VERSION ""

NS_ :

BS_:

BU_: APIM_CISM APIM ESPM DSP FCIMB RACM_RCIM HUD_ADV WCM TRM_ITRM ACM GWM _delete IPC GENERIC TSTR

BO_ 413 LBS1_Indication_Signals: 8 APIM
 SG_ LBS1_ParentID : 31|16@0+ (1,0) [0|65535] "unitless"  RACM_RCIM,IPC
 SG_ LBS1_ListStatus : 57|2@0+ (1,0) [0|3] "SED"  RACM_RCIM,IPC
 SG_ LBS1_ListServer : 7|8@0+ (1,0) [0|255] "unitless"  RACM_RCIM,IPC
 SG_ LBS1_ListID : 15|16@0+ (1,0) [0|65535] "unitless"  RACM_RCIM,IPC
 SG_ LBS1_EntryIndex : 47|16@0+ (1,0) [0|65535] "unitless"  RACM_RCIM,IPC

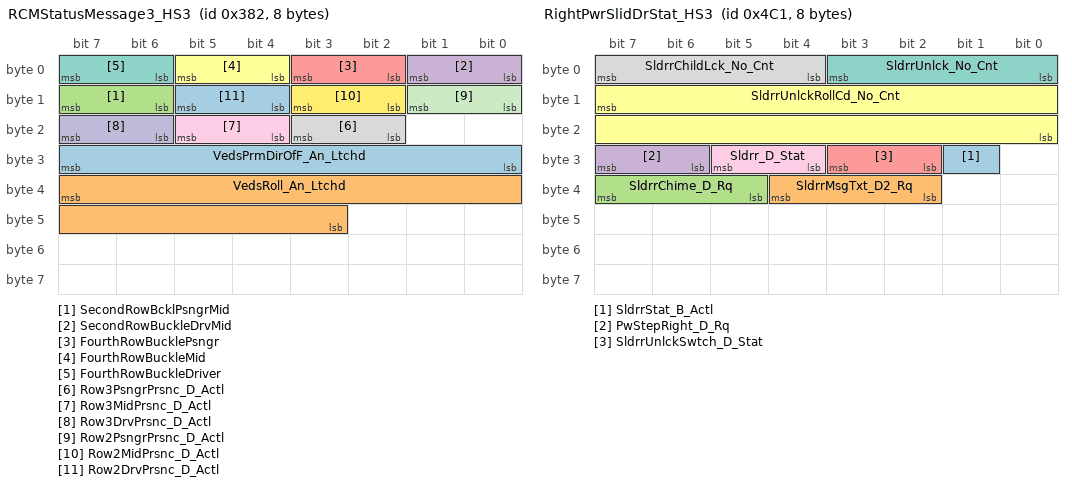
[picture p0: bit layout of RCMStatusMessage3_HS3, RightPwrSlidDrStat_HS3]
BO_ 898 RCMStatusMessage3_HS3: 8 GWM
 SG_ VedsPrmDirOfF_An_Ltchd : 31|8@0+ (2,-180) [-178|326] "degree"  APIM
 SG_ VedsRoll_An_Ltchd : 39|13@0+ (0.5,-2048) [-2047.5|2046.5] "degree"  APIM
 SG_ SecondRowBcklPsngrMid : 15|2@0+ (1,0) [0|3] "SED"  IPC
 SG_ SecondRowBuckleDrvMid : 1|2@0+ (1,0) [0|3] "SED"  IPC
 SG_ FourthRowBucklePsngr : 3|2@0+ (1,0) [0|3] "SED"  IPC
 SG_ FourthRowBuckleMid : 5|2@0+ (1,0) [0|3] "SED"  IPC
 SG_ FourthRowBuckleDriver : 7|2@0+ (1,0) [0|3] "SED"  IPC
 SG_ Row3PsngrPrsnc_D_Actl : 19|2@0+ (1,0) [0|3] "SED"  APIM,APIM_CISM,IPC
 SG_ Row3MidPrsnc_D_Actl : 21|2@0+ (1,0) [0|3] "SED"  APIM,APIM_CISM,IPC
 SG_ Row3DrvPrsnc_D_Actl : 23|2@0+ (1,0) [0|3] "SED"  APIM,APIM_CISM,IPC
 SG_ Row2PsngrPrsnc_D_Actl : 9|2@0+ (1,0) [0|3] "SED"  APIM,APIM_CISM,IPC
 SG_ Row2MidPrsnc_D_Actl : 11|2@0+ (1,0) [0|3] "SED"  APIM,APIM_CISM,IPC
 SG_ Row2DrvPrsnc_D_Actl : 13|2@0+ (1,0) [0|3] "SED"  APIM,APIM_CISM,IPC

BO_ 1020 Personality_APIM_Data4: 8 APIM
 SG_ CtrStkPersIndex2_D_Actl : 39|3@0+ (1,0) [0|7] "SED"  HUD_ADV,IPC
 SG_ CtrStkFeat2ConfigActl : 7|16@0+ (1,0) [0|65535] "Undefined"  HUD_ADV,IPC
 SG_ CtrStkFeat2NoActl : 23|16@0+ (1,0) [0|65535] "Undefined"  HUD_ADV,IPC
 SG_ CtrStkDsplyOp2_D_Rq : 36|3@0+ (1,0) [0|7] "SED"  HUD_ADV,IPC

BO_ 1007 Personality_IPC_Data_3: 8 IPC
 SG_ PersIndexIpc2_D_Actl : 39|3@0+ (1,0) [0|7] "SED"  APIM,APIM_CISM
 SG_ FeatNoIpc2Actl : 23|16@0+ (1,0) [0|65535] "Number"  APIM,APIM_CISM
 SG_ FeatConfigIpc2Actl : 7|16@0+ (1,0) [0|65535] "unitless"  APIM,APIM_CISM

BO_ 1217 RightPwrSlidDrStat_HS3: 8 GWM
 SG_ SldrrStat_B_Actl : 25|1@0+ (1,0) [0|1] "SED"  IPC
 SG_ SldrrMsgTxt_D2_Rq : 36|3@0+ (1,0) [0|7] "SED"  IPC
 SG_ SldrrChime_D_Rq : 39|3@0+ (1,0) [0|7] "SED"  IPC
 SG_ PwStepRight_D_Rq : 31|2@0+ (1,0) [0|3] "SED" Vector__XXX
 SG_ SldrrUnlckSwtch_D_Stat : 27|2@0+ (1,0) [0|3] "SED" Vector__XXX
 SG_ SldrrUnlckRollCd_No_Cnt : 15|16@0+ (1,0) [0|65535] "unitless" Vector__XXX
 SG_ SldrrUnlck_No_Cnt : 3|4@0+ (1,0) [0|15] "unitless" Vector__XXX
 SG_ SldrrChildLck_No_Cnt : 7|4@0+ (1,0) [0|15] "unitless" Vector__XXX
 SG_ Sldrr_D_Stat : 29|2@0+ (1,0) [0|3] "SED" Vector__XXX

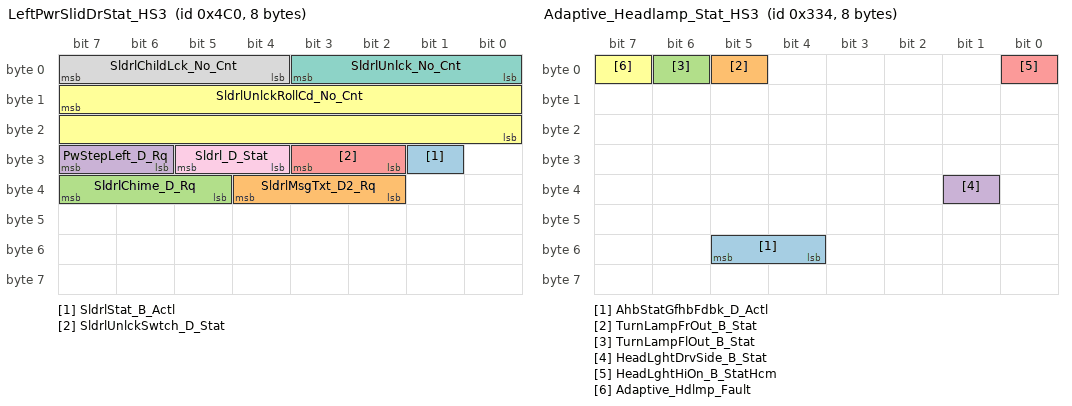
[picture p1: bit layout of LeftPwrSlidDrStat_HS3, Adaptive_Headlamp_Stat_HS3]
BO_ 1216 LeftPwrSlidDrStat_HS3: 8 GWM
 SG_ SldrlStat_B_Actl : 25|1@0+ (1,0) [0|1] "SED"  IPC
 SG_ SldrlMsgTxt_D2_Rq : 36|3@0+ (1,0) [0|7] "SED"  IPC
 SG_ SldrlChime_D_Rq : 39|3@0+ (1,0) [0|7] "SED"  IPC
 SG_ PwStepLeft_D_Rq : 31|2@0+ (1,0) [0|3] "SED" Vector__XXX
 SG_ SldrlUnlckSwtch_D_Stat : 27|2@0+ (1,0) [0|3] "SED" Vector__XXX
 SG_ SldrlUnlckRollCd_No_Cnt : 15|16@0+ (1,0) [0|65535] "unitless" Vector__XXX
 SG_ SldrlUnlck_No_Cnt : 3|4@0+ (1,0) [0|15] "unitless" Vector__XXX
 SG_ SldrlChildLck_No_Cnt : 7|4@0+ (1,0) [0|15] "unitless" Vector__XXX
 SG_ Sldrl_D_Stat : 29|2@0+ (1,0) [0|3] "SED" Vector__XXX

BO_ 820 Adaptive_Headlamp_Stat_HS3: 8 GWM
 SG_ AhbStatGfhbFdbk_D_Actl : 53|2@0+ (1,0) [0|3] "SED" Vector__XXX
 SG_ TurnLampFrOut_B_Stat : 5|1@0+ (1,0) [0|1] "SED" Vector__XXX
 SG_ TurnLampFlOut_B_Stat : 6|1@0+ (1,0) [0|1] "SED" Vector__XXX
 SG_ HeadLghtDrvSide_B_Stat : 33|1@0+ (1,0) [0|1] "SED" Vector__XXX
 SG_ HeadLghtHiOn_B_StatHcm : 0|1@0+ (1,0) [0|1] "SED"  IPC
 SG_ Adaptive_Hdlmp_Fault : 7|1@0+ (1,0) [0|1] "SED"  IPC

BO_ 1247 PowerDistData_4_HS3: 8 GWM
 SG_ TrlrBrkCtl3_B_Falt : 2|1@0+ (1,0) [0|1] "SED"  TRM_ITRM
 SG_ StopLampBRqTrlrAft_No_Cs : 15|8@0+ (1,0) [0|255] "Unitless" Vector__XXX
 SG_ StopLampBRqTrlrAft_No_Cnt : 6|4@0+ (1,0) [0|15] "Unitless" Vector__XXX
 SG_ StopLamp_B_RqTrlrAft : 7|1@0+ (1,0) [0|1] "SED"  TRM_ITRM

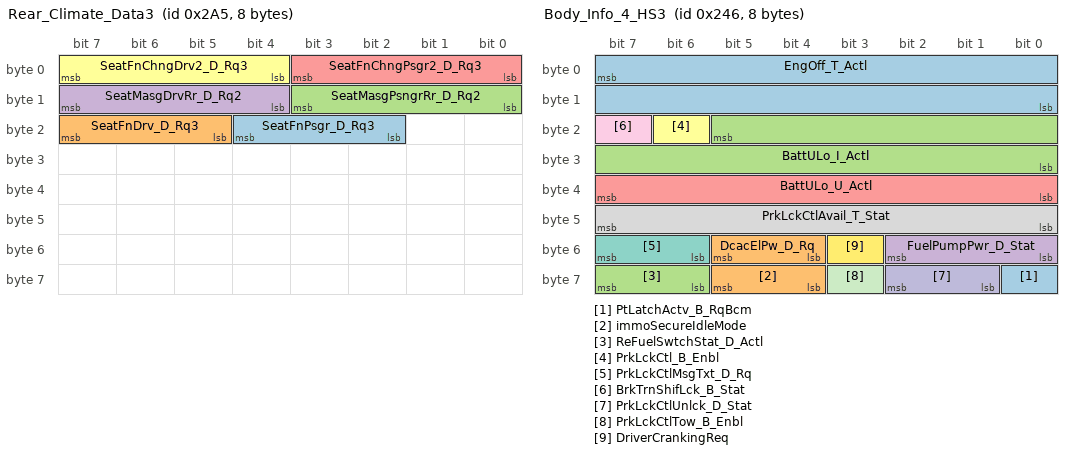
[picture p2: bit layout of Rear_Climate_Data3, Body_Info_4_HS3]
BO_ 677 Rear_Climate_Data3: 8 RACM_RCIM
 SG_ SeatFnPsgr_D_Rq3 : 20|3@0+ (1,0) [0|7] "SED"  GWM
 SG_ SeatFnDrv_D_Rq3 : 23|3@0+ (1,0) [0|7] "SED"  GWM
 SG_ SeatMasgPsngrRr_D_Rq2 : 11|4@0+ (1,0) [0|15] "SED"  GWM
 SG_ SeatMasgDrvRr_D_Rq2 : 15|4@0+ (1,0) [0|15] "SED"  GWM
 SG_ SeatFnChngPsgr2_D_Rq3 : 3|4@0+ (1,0) [0|15] "SED"  GWM
 SG_ SeatFnChngDrv2_D_Rq3 : 7|4@0+ (1,0) [0|15] "SED"  GWM

BO_ 582 Body_Info_4_HS3: 8 GWM
 SG_ PtLatchActv_B_RqBcm : 56|1@0+ (1,0) [0|1] "SED"  IPC
 SG_ immoSecureIdleMode : 61|2@0+ (1,0) [0|3] "SED"  APIM,APIM_CISM
 SG_ ReFuelSwtchStat_D_Actl : 63|2@0+ (1,0) [0|3] "SED" Vector__XXX
 SG_ FuelPumpPwr_D_Stat : 50|3@0+ (1,0) [0|7] "SED" Vector__XXX
 SG_ BattULo_U_Actl : 39|8@0+ (0.0625,0) [0|15.875] "volt" Vector__XXX
 SG_ PrkLckCtl_B_Enbl : 22|1@0+ (1,0) [0|1] "SED"  APIM,APIM_CISM,IPC
 SG_ PrkLckCtlMsgTxt_D_Rq : 55|2@0+ (1,0) [0|3] "SED"  IPC
 SG_ PrkLckCtlAvail_T_Stat : 47|8@0+ (1,0) [0|255] "second"  IPC
 SG_ BrkTrnShifLck_B_Stat : 23|1@0+ (1,0) [0|1] "SED" Vector__XXX
 SG_ PrkLckCtlUnlck_D_Stat : 58|2@0+ (1,0) [0|3] "SED"  IPC
 SG_ PrkLckCtlTow_B_Enbl : 59|1@0+ (1,0) [0|1] "SED"  IPC
 SG_ DriverCrankingReq : 51|1@0+ (1,0) [0|1] "SED" Vector__XXX
 SG_ EngOff_T_Actl : 7|16@0+ (1,0) [0|65534] "second^0.5"  IPC
 SG_ DcacElPw_D_Rq : 53|2@0+ (1,0) [0|3] "SED" Vector__XXX
 SG_ BattULo_I_Actl : 21|14@0+ (0.0625,-512) [-512|511.875] "ampere" Vector__XXX

BO_ 1036 PedestrianAlert_Data_HS3: 8 GWM
 SG_ PdstrnAlrt_B_Falt : 7|1@0+ (1,0) [0|1] "SED"  IPC

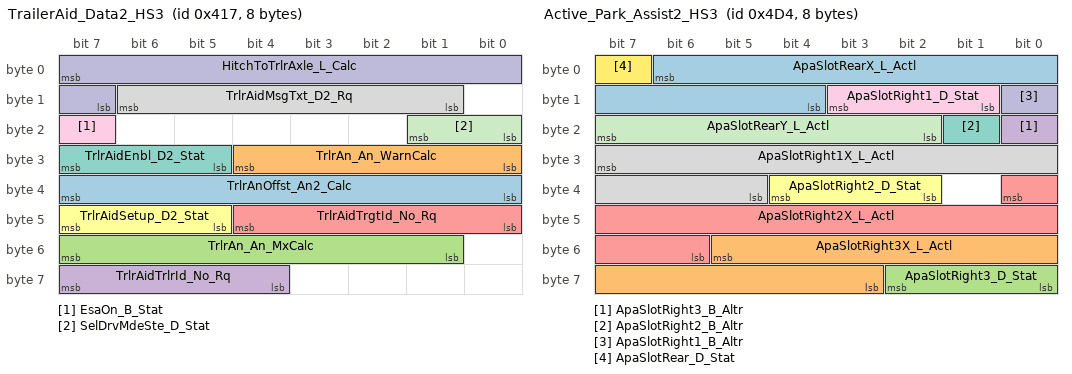
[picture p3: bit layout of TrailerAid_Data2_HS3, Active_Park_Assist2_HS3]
BO_ 1047 TrailerAid_Data2_HS3: 8 GWM
 SG_ TrlrAnOffst_An2_Calc : 39|8@0+ (0.5,-64) [-64|63.5] "degrees" Vector__XXX
 SG_ TrlrAn_An_WarnCalc : 28|5@0+ (1,0) [0|31] "degrees" Vector__XXX
 SG_ TrlrAn_An_MxCalc : 55|7@0+ (1,0) [0|127] "degrees" Vector__XXX
 SG_ TrlrAidTrlrId_No_Rq : 63|4@0+ (1,0) [0|15] "unitless"  APIM,APIM_CISM,IPC
 SG_ TrlrAidTrgtId_No_Rq : 44|5@0+ (1,0) [0|31] "unitless" Vector__XXX
 SG_ TrlrAidSetup_D2_Stat : 47|3@0+ (1,0) [0|7] "SED" Vector__XXX
 SG_ TrlrAidEnbl_D2_Stat : 31|3@0+ (1,0) [0|7] "SED"  APIM,APIM_CISM,TRM_ITRM,IPC
 SG_ TrlrAidMsgTxt_D2_Rq : 14|6@0+ (1,0) [0|63] "SED"  APIM,APIM_CISM,IPC,TRM_ITRM
 SG_ EsaOn_B_Stat : 23|1@0+ (1,0) [0|1] "SED"  IPC
 SG_ HitchToTrlrAxle_L_Calc : 7|9@0+ (0.0254,0) [0|12.9794] "meter" Vector__XXX
 SG_ SelDrvMdeSte_D_Stat : 17|2@0+ (1,0) [0|3] "SED" Vector__XXX

BO_ 688 APIM_TCUB_Word_Rx_HS3: 8 GWM
 SG_ APIM_TCUB_Word_Rx : 7|64@0+ (1,0) [0|1.84467440737096E+019] "unitless"  APIM,APIM_CISM

BO_ 696 APIM_TCUB_Word_Tx: 8 APIM
 SG_ APIM_TCUB_Word_Tx : 7|64@0+ (1,0) [0|1.84467440737096E+019] "unitless"  GWM

BO_ 1236 Active_Park_Assist2_HS3: 8 GWM
 SG_ ApaSlotRearX_L_Actl : 6|11@0+ (0.02,-20.96) [-20.96|19.98] "meter"  APIM,APIM_CISM
 SG_ ApaSlotRight3X_L_Actl : 53|11@0+ (0.02,-20.96) [-20.96|19.98] "meter"  APIM,APIM_CISM
 SG_ ApaSlotRight3_D_Stat : 58|3@0+ (1,0) [0|7] "SED"  APIM,APIM_CISM
 SG_ ApaSlotRight3_B_Altr : 16|1@0+ (1,0) [0|1] "SED"  APIM,APIM_CISM
 SG_ ApaSlotRight2X_L_Actl : 32|11@0+ (0.02,-20.96) [-20.96|19.98] "meter"  APIM,APIM_CISM
 SG_ ApaSlotRight2_D_Stat : 36|3@0+ (1,0) [0|7] "SED"  APIM,APIM_CISM
 SG_ ApaSlotRight2_B_Altr : 17|1@0+ (1,0) [0|1] "SED"  APIM,APIM_CISM
 SG_ ApaSlotRight1X_L_Actl : 31|11@0+ (0.02,-20.96) [-20.96|19.98] "meter"  APIM,APIM_CISM
 SG_ ApaSlotRight1_D_Stat : 11|3@0+ (1,0) [0|7] "SED"  APIM,APIM_CISM
 SG_ ApaSlotRight1_B_Altr : 8|1@0+ (1,0) [0|1] "SED"  APIM,APIM_CISM
 SG_ ApaSlotRearY_L_Actl : 23|6@0+ (0.2,-6.4) [-6.4|6.2] "meter"  APIM,APIM_CISM
 SG_ ApaSlotRear_D_Stat : 7|1@0+ (1,0) [0|1] "SED"  APIM,APIM_CISM

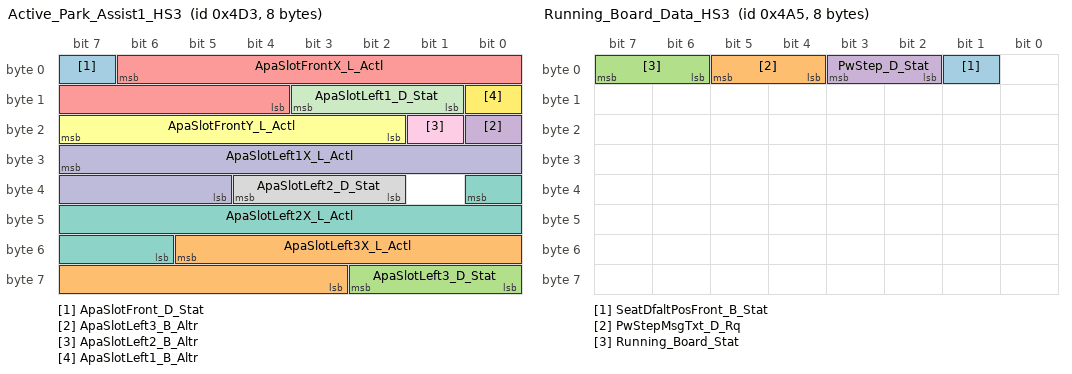
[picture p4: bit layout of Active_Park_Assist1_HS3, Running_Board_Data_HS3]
BO_ 1235 Active_Park_Assist1_HS3: 8 GWM
 SG_ ApaSlotFront_D_Stat : 7|1@0+ (1,0) [0|1] "SED"  APIM,APIM_CISM
 SG_ ApaSlotLeft3X_L_Actl : 53|11@0+ (0.02,-20.96) [-20.96|19.98] "meter"  APIM,APIM_CISM
 SG_ ApaSlotLeft3_D_Stat : 58|3@0+ (1,0) [0|7] "SED"  APIM,APIM_CISM
 SG_ ApaSlotLeft3_B_Altr : 16|1@0+ (1,0) [0|1] "SED"  APIM,APIM_CISM
 SG_ ApaSlotFrontX_L_Actl : 6|11@0+ (0.02,-20.96) [-20.96|19.98] "meter"  APIM,APIM_CISM
 SG_ ApaSlotFrontY_L_Actl : 23|6@0+ (0.2,-6.4) [-6.4|6.2] "meter"  APIM,APIM_CISM
 SG_ ApaSlotLeft2X_L_Actl : 32|11@0+ (0.02,-20.96) [-20.96|19.98] "meter"  APIM,APIM_CISM
 SG_ ApaSlotLeft2_D_Stat : 36|3@0+ (1,0) [0|7] "SED"  APIM,APIM_CISM
 SG_ ApaSlotLeft2_B_Altr : 17|1@0+ (1,0) [0|1] "SED"  APIM,APIM_CISM
 SG_ ApaSlotLeft1X_L_Actl : 31|11@0+ (0.02,-20.96) [-20.96|19.98] "meter"  APIM,APIM_CISM
 SG_ ApaSlotLeft1_D_Stat : 11|3@0+ (1,0) [0|7] "SED"  APIM,APIM_CISM
 SG_ ApaSlotLeft1_B_Altr : 8|1@0+ (1,0) [0|1] "SED"  APIM,APIM_CISM

BO_ 841 FuelOpHeater_Stat2_HS3: 8 GWM
 SG_ FohStrtDateDay_No_Stat : 7|16@0+ (1,0) [0|65535] "julian day"  IPC
 SG_ FohStrtDateYr_No_Stat : 23|8@0+ (1,2000) [2000|2255] "year"  IPC
 SG_ FohAddHeater_D_Stat : 31|2@0+ (1,0) [0|3] "SED" Vector__XXX

BO_ 1189 Running_Board_Data_HS3: 8 GWM
 SG_ SeatDfaltPosFront_B_Stat : 1|1@0+ (1,0) [0|1] "SED" Vector__XXX
 SG_ PwStepMsgTxt_D_Rq : 5|2@0+ (1,0) [0|3] "SED"  IPC
 SG_ Running_Board_Stat : 7|2@0+ (1,0) [0|3] "SED"  APIM,APIM_CISM,IPC
 SG_ PwStep_D_Stat : 3|2@0+ (1,0) [0|3] "SED" Vector__XXX

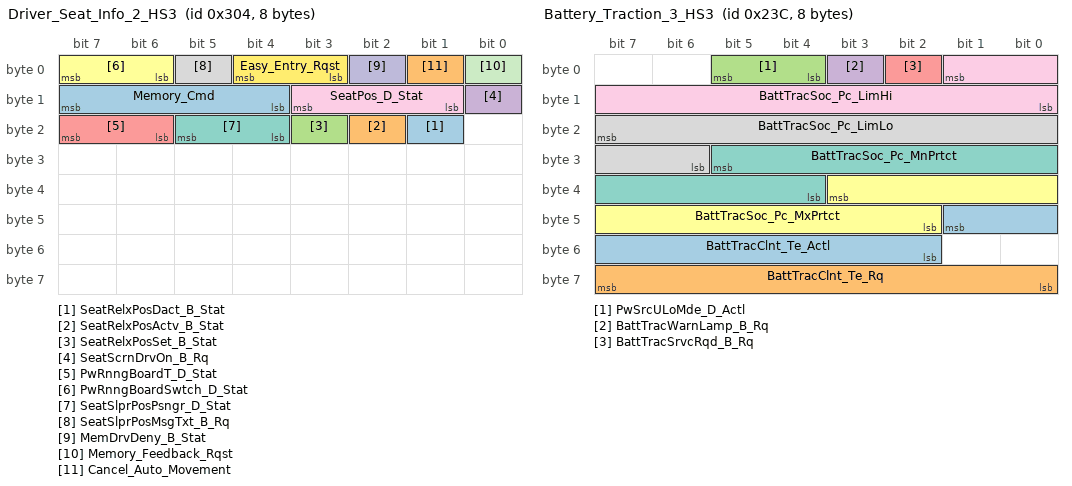
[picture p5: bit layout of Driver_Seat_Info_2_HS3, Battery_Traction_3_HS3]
BO_ 772 Driver_Seat_Info_2_HS3: 8 GWM
 SG_ SeatRelxPosDact_B_Stat : 17|1@0+ (1,0) [0|1] "SED"  APIM,APIM_CISM
 SG_ SeatRelxPosActv_B_Stat : 18|1@0+ (1,0) [0|1] "SED"  APIM,APIM_CISM
 SG_ SeatRelxPosSet_B_Stat : 19|1@0+ (1,0) [0|1] "SED"  APIM,APIM_CISM
 SG_ SeatScrnDrvOn_B_Rq : 8|1@0+ (1,0) [0|1] "SED"  APIM,APIM_CISM
 SG_ PwRnngBoardT_D_Stat : 23|2@0+ (1,0) [0|3] "SED"  APIM,APIM_CISM,IPC
 SG_ PwRnngBoardSwtch_D_Stat : 7|2@0+ (1,0) [0|3] "SED"  APIM,APIM_CISM,IPC
 SG_ SeatSlprPosPsngr_D_Stat : 21|2@0+ (1,0) [0|3] "SED" Vector__XXX
 SG_ SeatSlprPosMsgTxt_B_Rq : 5|1@0+ (1,0) [0|1] "SED"  IPC
 SG_ SeatPos_D_Stat : 11|3@0+ (1,0) [0|7] "SED" Vector__XXX
 SG_ MemDrvDeny_B_Stat : 2|1@0+ (1,0) [0|1] "SED"  IPC
 SG_ Memory_Feedback_Rqst : 0|1@0+ (1,0) [0|1] "SED"  IPC
 SG_ Easy_Entry_Rqst : 4|2@0+ (1,0) [0|3] "SED" Vector__XXX
 SG_ Memory_Cmd : 15|4@0+ (1,0) [0|15] "SED"  IPC
 SG_ Cancel_Auto_Movement : 1|1@0+ (1,0) [0|1] "SED"  APIM_CISM

BO_ 1054 BrakeSysFeatures_3_HS3: 8 GWM
 SG_ SelDrvMdeChassis3_D_Rq : 61|5@0+ (1,0) [0|31] "SED" Vector__XXX
 SG_ RbaBrk_D_Stat : 63|2@0+ (1,0) [0|3] "SED" Vector__XXX
 SG_ SelDrvMdeChassis2_D_Rq : 45|5@0+ (1,0) [0|31] "SED" Vector__XXX
 SG_ BrkBstrLoLampOn_B_Rq : 24|1@0+ (1,0) [0|1] "SED" Vector__XXX
 SG_ TrailCtl_D_Stat : 55|3@0+ (1,0) [0|7] "SED"  APIM,APIM_CISM,IPC
 SG_ TrailCtlMsgTxt_D_Rq : 52|4@0+ (1,0) [0|15] "SED"  APIM_CISM,IPC
 SG_ BrkPadMsgTxt_D_Rq : 31|2@0+ (1,0) [0|3] "SED"  IPC
 SG_ BrkBstrVac_D_Stat : 18|2@0+ (1,0) [0|3] "SED" Vector__XXX
 SG_ DrvSlipCtlOffLamp_D_Rq : 23|2@0+ (1,0) [0|3] "SED"  APIM,APIM_CISM,IPC
 SG_ DrvSlipCtlMdeMsg_D_Rq : 13|5@0+ (1,0) [0|31] "SED"  APIM,APIM_CISM,IPC
 SG_ HdcOn_B_Ind : 16|1@0+ (1,0) [0|1] "SED"  APIM,APIM_CISM,IPC
 SG_ AutoHoldMsgTxt_D_Rq : 4|4@0+ (1,0) [0|15] "SED"  IPC
 SG_ CtaBrk_D_Stat : 47|2@0+ (1,0) [0|3] "SED" Vector__XXX
 SG_ SelDrvMdeAwd_D_Rq : 29|5@0+ (1,0) [0|31] "SED" Vector__XXX
 SG_ AutoHoldSwMde_B_Ind : 0|1@0+ (1,0) [0|1] "SED"  APIM,APIM_CISM
 SG_ AutoHoldMde_D_Ind : 15|2@0+ (1,0) [0|3] "SED"  IPC,HUD_ADV
 SG_ BrkMdeInhbt_B_RqDsply : 8|1@0+ (1,0) [0|1] "SED"  IPC
 SG_ BrkLineLck_D_Stat : 21|3@0+ (1,0) [0|7] "SED"  IPC
 SG_ SelDrvMdeChassis_D_Rq : 39|5@0+ (1,0) [0|31] "SED" Vector__XXX
 SG_ ApaBrk_D_Stat : 34|2@0+ (1,0) [0|3] "SED" Vector__XXX
 SG_ FrontDiffElckrOpen_B_Rq : 48|1@0+ (1,0) [0|1] "SED" Vector__XXX
 SG_ OnePdlDrvDeny_B_Stat : 40|1@0+ (1,0) [0|1] "SED" Vector__XXX
 SG_ BrkDrvMde_D_Stat : 7|3@0+ (1,0) [0|7] "SED"  ACM,IPC
 SG_ TrailOnePdlTqLm_B_Actl : 56|1@0+ (1,0) [0|1] "SED" Vector__XXX

BO_ 572 Battery_Traction_3_HS3: 8 GWM
 SG_ BattTracClnt_Te_Actl : 41|8@0+ (0.5,-60) [-60|66.5] "degC" Vector__XXX
 SG_ BattTracClnt_Te_Rq : 63|8@0+ (0.5,-60) [-60|67.5] "degC" Vector__XXX
 SG_ PwSrcULoMde_D_Actl : 5|2@0+ (1,0) [0|3] "SED" Vector__XXX
 SG_ BattTracWarnLamp_B_Rq : 3|1@0+ (1,0) [0|1] "SED"  IPC
 SG_ BattTracSrvcRqd_B_Rq : 2|1@0+ (1,0) [0|1] "SED"  IPC
 SG_ BattTracSoc_Pc_MxPrtct : 35|10@0+ (0.1,0) [0|100] "%" Vector__XXX
 SG_ BattTracSoc_Pc_MnPrtct : 29|10@0+ (0.1,0) [0|100] "%" Vector__XXX
 SG_ BattTracSoc_Pc_LimLo : 23|10@0+ (0.1,0) [0|100] "%" Vector__XXX
 SG_ BattTracSoc_Pc_LimHi : 1|10@0+ (0.1,0) [0|100] "%" Vector__XXX

BO_ 561 TransGearData_2_HS3: 8 GWM
 SG_ TrnMsgTxt2_D_Rq : 39|3@0+ (1,0) [0|7] "SED"  APIM_CISM,IPC
 SG_ TrnMsgTxt_D_Rq : 23|4@0+ (1,0) [0|15] "SED"  IPC

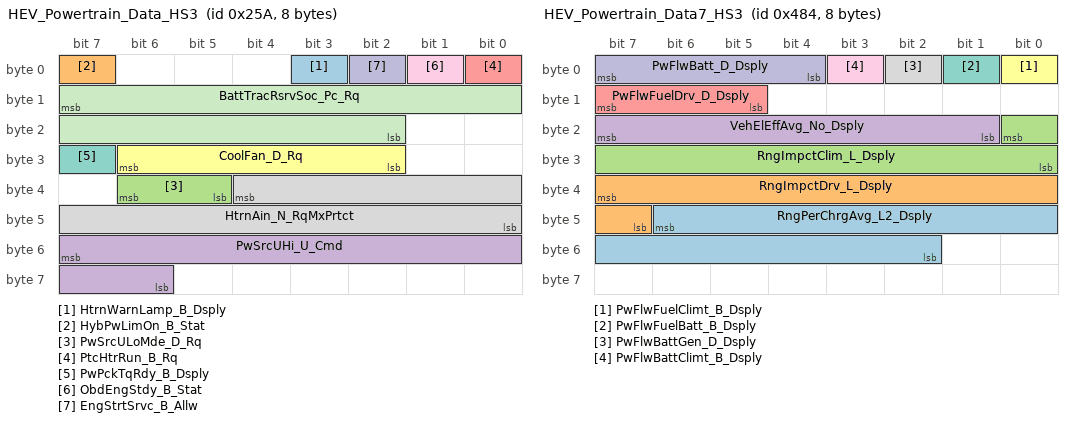
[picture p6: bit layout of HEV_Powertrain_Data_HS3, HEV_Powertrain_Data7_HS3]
BO_ 602 HEV_Powertrain_Data_HS3: 8 GWM
 SG_ HtrnWarnLamp_B_Dsply : 3|1@0+ (1,0) [0|1] "SED"  IPC
 SG_ HybPwLimOn_B_Stat : 7|1@0+ (1,0) [0|1] "SED" Vector__XXX
 SG_ PwSrcULoMde_D_Rq : 38|2@0+ (1,0) [0|3] "SED" Vector__XXX
 SG_ PwSrcUHi_U_Cmd : 55|10@0+ (0.5,0) [0|511.5] "volt" Vector__XXX
 SG_ PtcHtrRun_B_Rq : 0|1@0+ (1,0) [0|1] "SED" Vector__XXX
 SG_ CoolFan_D_Rq : 30|5@0+ (1,0) [0|31] "unitless" Vector__XXX
 SG_ PwPckTqRdy_B_Dsply : 31|1@0+ (1,0) [0|1] "SED"  APIM,APIM_CISM,IPC
 SG_ HtrnAin_N_RqMxPrtct : 36|13@0+ (2,0) [0|16382] "RPM" Vector__XXX
 SG_ ObdEngStdy_B_Stat : 1|1@0+ (1,0) [0|1] "SED" Vector__XXX
 SG_ EngStrtSrvc_B_Allw : 2|1@0+ (1,0) [0|1] "SED" Vector__XXX
 SG_ BattTracRsrvSoc_Pc_Rq : 15|14@0+ (0.01,0) [0|163.81] "percent" Vector__XXX

BO_ 92 Gear_Shift_by_Wire_3_HS3: 8 GWM
 SG_ TrnGearMsgTxt2_D_Rq : 53|5@0+ (1,0) [0|31] "SED"  IPC
 SG_ RaceTrakMde_D_Stat : 55|2@0+ (1,0) [0|3] "SED" Vector__XXX
 SG_ TrnLvrV_D_Rq : 43|2@0+ (1,0) [0|3] "SED" Vector__XXX
 SG_ TrnSbwSysHlth_D_Actl : 1|2@0+ (1,0) [0|3] "SED" Vector__XXX
 SG_ TrnDtpCmd_D_Actl : 46|3@0+ (1,0) [0|7] "SED" Vector__XXX
 SG_ TrnGearNtmAllow_B_Stat : 47|1@0+ (1,0) [0|1] "SED"  APIM,APIM_CISM,IPC
 SG_ GearSelLck_D_Rq : 41|2@0+ (1,0) [0|3] "SED" Vector__XXX
 SG_ TrnGearCmd_No_Cs : 31|8@0+ (1,0) [0|255] "unitless" Vector__XXX
 SG_ TrnValidGear_D_Cnfm : 11|2@0+ (1,0) [0|3] "SED" Vector__XXX
 SG_ TrnNtrlTowCmd_D_Actl : 6|2@0+ (1,0) [0|3] "SED" Vector__XXX
 SG_ TrnGearCmd_Pc_ActlPt : 9|10@0+ (0.1,0) [0|102.2] "percent duty cycle" Vector__XXX
 SG_ TrnGear_D_RqPt : 4|3@0+ (1,0) [0|7] "SED" Vector__XXX
 SG_ TrnCmdState_B_Actl : 39|1@0+ (1,0) [0|1] "SED" Vector__XXX
 SG_ TrnCmdCnt_B_Actl : 7|1@0+ (1,0) [0|1] "unitless" Vector__XXX
 SG_ PrkBrkActv_D_RqTrnGear : 38|2@0+ (1,0) [0|3] "SED" Vector__XXX
 SG_ TrnGearMsgTxt_D_Rq : 36|5@0+ (1,0) [0|31] "SED"  APIM,IPC
 SG_ TrnGearCmd_No_Cnt : 15|4@0+ (1,0) [0|15] "unitless" Vector__XXX

BO_ 1156 HEV_Powertrain_Data7_HS3: 8 GWM
 SG_ RngPerChrgAvg_L2_Dsply : 46|13@0+ (0.1,0) [0|818.9] "km"  APIM,APIM_CISM,IPC
 SG_ RngImpctDrv_L_Dsply : 39|9@0+ (1,-255) [-255|256] "km"  IPC
 SG_ RngImpctClim_L_Dsply : 16|9@0+ (1,-255) [-255|256] "km"  IPC
 SG_ VehElEffAvg_No_Dsply : 23|7@0+ (10,-100) [-100|1150] "wattHr/km"  APIM,APIM_CISM,IPC
 SG_ PwFlwFuelDrv_D_Dsply : 15|3@0+ (1,0) [0|7] "SED"  APIM,APIM_CISM
 SG_ PwFlwFuelClimt_B_Dsply : 0|1@0+ (1,0) [0|1] "SED"  APIM,APIM_CISM
 SG_ PwFlwFuelBatt_B_Dsply : 1|1@0+ (1,0) [0|1] "SED"  APIM,APIM_CISM
 SG_ PwFlwBattGen_D_Dsply : 2|1@0+ (1,0) [0|1] "SED"  APIM,APIM_CISM
 SG_ PwFlwBattClimt_B_Dsply : 3|1@0+ (1,0) [0|1] "SED"  APIM,APIM_CISM
 SG_ PwFlwBatt_D_Dsply : 7|4@0+ (1,0) [0|15] "SED"  APIM,APIM_CISM

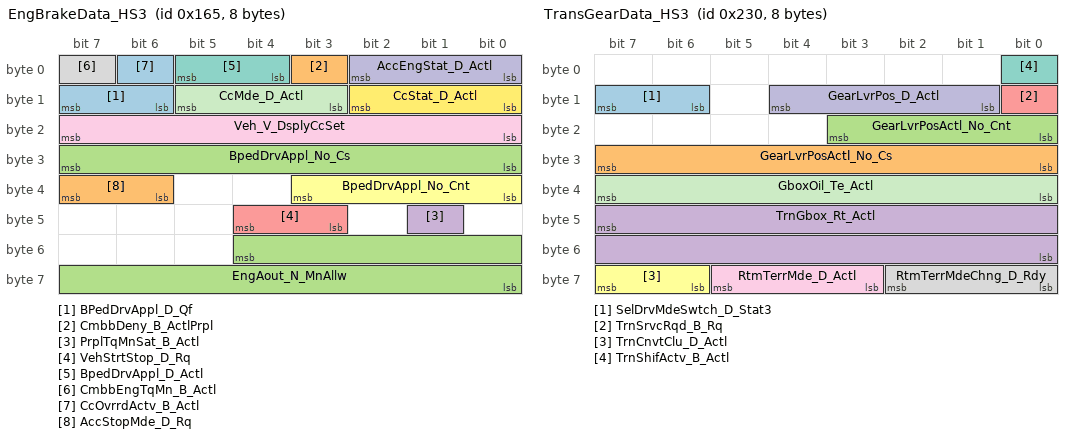
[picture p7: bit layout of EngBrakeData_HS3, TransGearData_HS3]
BO_ 357 EngBrakeData_HS3: 8 GWM
 SG_ BPedDrvAppl_D_Qf : 15|2@0+ (1,0) [0|3] "SED" Vector__XXX
 SG_ CmbbDeny_B_ActlPrpl : 3|1@0+ (1,0) [0|1] "SED" Vector__XXX
 SG_ BpedDrvAppl_No_Cs : 31|8@0+ (1,0) [0|255] "unitless" Vector__XXX
 SG_ PrplTqMnSat_B_Actl : 41|1@0+ (1,0) [0|1] "SED" Vector__XXX
 SG_ VehStrtStop_D_Rq : 44|2@0+ (1,0) [0|3] "SED" Vector__XXX
 SG_ BpedDrvAppl_No_Cnt : 35|4@0+ (1,0) [0|15] "unitless" Vector__XXX
 SG_ BpedDrvAppl_D_Actl : 5|2@0+ (1,0) [0|3] "SED"  APIM,APIM_CISM,IPC,TRM_ITRM
 SG_ CmbbEngTqMn_B_Actl : 7|1@0+ (1,0) [0|1] "SED" Vector__XXX
 SG_ Veh_V_DsplyCcSet : 23|8@0+ (1,0) [0|253] "unitless"  HUD_ADV,IPC
 SG_ AccEngStat_D_Actl : 2|3@0+ (1,0) [0|7] "SED" Vector__XXX
 SG_ CcMde_D_Actl : 13|3@0+ (1,0) [0|7] "SED" Vector__XXX
 SG_ CcStat_D_Actl : 10|3@0+ (1,0) [0|7] "SED"  IPC,HUD_ADV
 SG_ CcOvrrdActv_B_Actl : 6|1@0+ (1,0) [0|1] "SED"  HUD_ADV,IPC
 SG_ AccStopMde_D_Rq : 39|2@0+ (1,0) [0|3] "SED" Vector__XXX
 SG_ EngAout_N_MnAllw : 52|13@0+ (2,0) [0|16382] "rpm" Vector__XXX

BO_ 1100 PowertrainData_9_HS3: 8 GWM
 SG_ RearDiffLckLamp_D_Rq2 : 21|2@0+ (1,0) [0|3] "SED"  IPC
 SG_ RvltnMatchAllw_D_Stat : 41|2@0+ (1,0) [0|3] "SED"  IPC
 SG_ WakeAlarm1_T_Rq : 55|15@0+ (1,0) [0|32767] "minute" Vector__XXX
 SG_ WakeAlarm1_B_Typ : 56|1@0+ (1,0) [0|1] "SED" Vector__XXX
 SG_ TrnNtrlIdlExit_B_Rq : 38|1@0+ (1,0) [0|1] "SED" Vector__XXX
 SG_ Veh_V_DsplyTrailCtlSet : 47|6@0+ (0.5,0) [0|31] "unitless"  IPC
 SG_ TrailCtlPt_B_Falt : 36|2@0+ (1,0) [0|3] "SED" Vector__XXX
 SG_ TrnNtrlIdlInhbt_B_Rq : 37|1@0+ (1,0) [0|1] "SED" Vector__XXX
 SG_ AutoTowAllw_D_StatMnu : 25|2@0+ (1,0) [0|3] "SED"  IPC
 SG_ AutoTowActv_B_Stat : 39|1@0+ (1,0) [0|1] "SED"  IPC
 SG_ SpareTireDetct_B_Stat : 30|1@0+ (1,0) [0|1] "SED" Vector__XXX
 SG_ RearDiffSumpOil_Te_Est : 15|8@0+ (1,-40) [-40|213] "degC" Vector__XXX
 SG_ RearDiffMtrRun_B_Stat : 31|1@0+ (1,0) [0|1] "SED" Vector__XXX
 SG_ EngTrlrCnnct_D_Stat : 23|2@0+ (1,0) [0|3] "SED" Vector__XXX
 SG_ GrossTrainWeight_M_Est : 7|8@0+ (100,0) [0|25300] "kilogram" Vector__XXX
 SG_ SuspVlimMsgTxt_B_Rq : 29|1@0+ (1,0) [0|1] "SED"  IPC
 SG_ RearDiffLckMsg2_D_Rq : 19|4@0+ (1,0) [0|15] "SED"  IPC
 SG_ EngExhMdeQuiet_D2_Stat : 28|3@0+ (1,0) [0|7] "SED"  APIM,APIM_CISM,ACM,IPC
 SG_ HvacCmprLim_D_Stat : 34|3@0+ (1,0) [0|7] "SED" Vector__XXX

BO_ 1152 HEV_Powertrain_Data6_HS3: 8 GWM
 SG_ PwCabinEnblScnd_B_Rq : 28|1@0+ (1,0) [0|1] "SED" Vector__XXX
 SG_ PwCabinEnbl_B_Rq : 29|1@0+ (1,0) [0|1] "SED" Vector__XXX
 SG_ PwTrnkFrntEnblScnd_B_Rq : 30|1@0+ (1,0) [0|1] "SED" Vector__XXX
 SG_ PwTrnkFrntEnbl_B_Rq : 31|1@0+ (1,0) [0|1] "SED" Vector__XXX
 SG_ PwOutlet8EnblScnd_B_Rq : 16|1@0+ (1,0) [0|1] "SED" Vector__XXX
 SG_ PwOutlet8Enbl_B_Rq : 17|1@0+ (1,0) [0|1] "SED" Vector__XXX
 SG_ PwOutlet7EnblScnd_B_Rq : 18|1@0+ (1,0) [0|1] "SED" Vector__XXX
 SG_ PwOutlet7Enbl_B_Rq : 19|1@0+ (1,0) [0|1] "SED" Vector__XXX
 SG_ PwOutlet6EnblScnd_B_Rq : 20|1@0+ (1,0) [0|1] "SED" Vector__XXX
 SG_ PwOutlet6Enbl_B_Rq : 21|1@0+ (1,0) [0|1] "SED" Vector__XXX
 SG_ HybPwULoLamp_B_Rq : 22|1@0+ (1,0) [0|1] "SED" Vector__XXX
 SG_ StopStrtVThres_D_Stat : 1|2@0+ (1,0) [0|3] "SED"  APIM,IPC
 SG_ GrdAsstActv_B_Stat : 8|1@0+ (1,0) [0|1] "SED"  IPC
 SG_ EngTeHi_B_Actl : 5|1@0+ (1,0) [0|1] "SED" Vector__XXX
 SG_ DcdcOn_B_Rq : 6|1@0+ (1,0) [0|1] "SED" Vector__XXX
 SG_ ULoBattSpprtSustn_B_Rq : 7|1@0+ (1,0) [0|1] "SED" Vector__XXX
 SG_ OnePdlDrv_D_Dsply : 4|2@0+ (1,0) [0|3] "SED"  APIM,APIM_CISM,IPC
 SG_ OnePdlDrvLamp_B_Rq : 23|1@0+ (1,0) [0|1] "SED"  IPC
 SG_ BattTracDiagClr_B_Stat : 2|1@0+ (1,0) [0|1] "SED" Vector__XXX
 SG_ VehElEff_No_Avg : 15|7@0+ (10,-100) [-100|1150] "watt*hr/km" Vector__XXX

BO_ 2612224064 PARSEDPushWCMtoGWM_ECG: 8 WCM
 SG_ PARSEDPushWCMtoGWM_ECG : 7|29@0+ (1,0) [0|536870911] "unitless"  GWM

BO_ 2612068568 PARSEDPushFcGWM_ECGtoWCM: 8 GWM
 SG_ PARSEDPushFcGWM_ECGtoWCM : 7|29@0+ (1,0) [0|536870911] "unitless"  WCM

BO_ 2611175488 PARSEDPhysWCMtoGWM_ECG: 8 WCM
 SG_ PARSEDPhysWCMtoGWM_ECG : 7|29@0+ (1,0) [0|536870911] "unitless"  GWM

BO_ 2611019992 PARSEDPhysGWM_ECGtoWCM: 8 GWM
 SG_ PARSEDPhysGWM_ECGtoWCM : 7|29@0+ (1,0) [0|536870911] "unitless"  WCM

BO_ 2610126912 OTAPhysWCMtoGWM_ECG: 8 WCM
 SG_ OTAPhysWCMtoGWM_ECG : 7|29@0+ (1,0) [0|536870911] "unitless"  GWM

BO_ 2609971416 OTAPhysGWM_ECGtoWCM: 8 GWM
 SG_ OTAPhysGWM_ECGtoWCM : 7|29@0+ (1,0) [0|536870911] "unitless"  WCM

BO_ 652 TCUB_Send_Signals_HS3: 8 GWM
 SG_ TelematicsSrvc_D_St2 : 7|3@0+ (1,0) [0|7] "SED"  APIM,APIM_CISM

BO_ 560 TransGearData_HS3: 8 GWM
 SG_ SelDrvMdeSwtch_D_Stat3 : 15|2@0+ (1,0) [0|3] "SED" Vector__XXX
 SG_ GearLvrPosActl_No_Cs : 31|8@0+ (1,0) [0|255] "unitless"  TRM_ITRM
 SG_ GearLvrPosActl_No_Cnt : 19|4@0+ (1,0) [0|15] "unitless"  TRM_ITRM
 SG_ TrnGbox_Rt_Actl : 47|16@0+ (0.001,0) [0|65.533] "unitless" Vector__XXX
 SG_ TrnSrvcRqd_B_Rq : 8|1@0+ (1,0) [0|1] "SED"  IPC
 SG_ TrnCnvtClu_D_Actl : 63|2@0+ (1,0) [0|3] "SED" Vector__XXX
 SG_ TrnShifActv_B_Actl : 0|1@0+ (1,0) [0|1] "SED" Vector__XXX
 SG_ RtmTerrMdeChng_D_Rdy : 58|3@0+ (1,0) [0|7] "SED" Vector__XXX
 SG_ RtmTerrMde_D_Actl : 61|3@0+ (1,0) [0|7] "SED" Vector__XXX
 SG_ GearLvrPos_D_Actl : 12|4@0+ (1,0) [0|15] "SED"  APIM,APIM_CISM,ACM,DSP,IPC,TRM_ITRM
 SG_ GboxOil_Te_Actl : 39|8@0+ (1,-60) [-60|193] "degC"  APIM,APIM_CISM,IPC

BO_ 1153 All_Terrain_Data_HS3: 8 GWM
 SG_ TerrStat_D_RqDsply : 7|4@0+ (1,0) [0|15] "SED"  GENERIC
 SG_ TerrMde_D_RqDrv : 3|3@0+ (1,0) [0|7] "SED" Vector__XXX

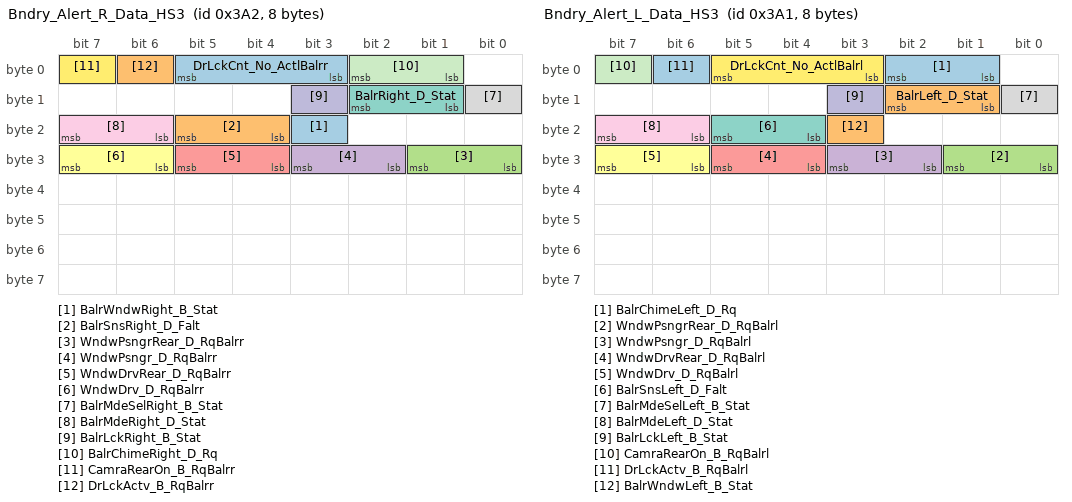
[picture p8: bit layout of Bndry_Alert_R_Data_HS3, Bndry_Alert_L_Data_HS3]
BO_ 930 Bndry_Alert_R_Data_HS3: 8 GWM
 SG_ BalrWndwRight_B_Stat : 19|1@0+ (1,0) [0|1] "SED"  IPC
 SG_ BalrSnsRight_D_Falt : 21|2@0+ (1,0) [0|3] "SED"  IPC
 SG_ WndwPsngrRear_D_RqBalrr : 25|2@0+ (1,0) [0|3] "SED" Vector__XXX
 SG_ WndwPsngr_D_RqBalrr : 27|2@0+ (1,0) [0|3] "SED" Vector__XXX
 SG_ WndwDrvRear_D_RqBalrr : 29|2@0+ (1,0) [0|3] "SED" Vector__XXX
 SG_ WndwDrv_D_RqBalrr : 31|2@0+ (1,0) [0|3] "SED" Vector__XXX
 SG_ BalrRight_D_Stat : 10|2@0+ (1,0) [0|3] "SED"  IPC
 SG_ BalrMdeSelRight_B_Stat : 8|1@0+ (1,0) [0|1] "SED"  IPC
 SG_ BalrMdeRight_D_Stat : 23|2@0+ (1,0) [0|3] "SED"  IPC
 SG_ BalrLckRight_B_Stat : 11|1@0+ (1,0) [0|1] "SED"  IPC
 SG_ BalrChimeRight_D_Rq : 2|2@0+ (1,0) [0|3] "SED"  IPC
 SG_ CamraRearOn_B_RqBalrr : 7|1@0+ (1,0) [0|1] "SED"  APIM,APIM_CISM,ACM,TRM_ITRM
 SG_ DrLckCnt_No_ActlBalrr : 5|3@0+ (1,0) [0|7] "unitless" Vector__XXX
 SG_ DrLckActv_B_RqBalrr : 6|1@0+ (1,0) [0|1] "SED" Vector__XXX

BO_ 929 Bndry_Alert_L_Data_HS3: 8 GWM
 SG_ BalrChimeLeft_D_Rq : 2|2@0+ (1,0) [0|3] "SED"  IPC
 SG_ BalrLeft_D_Stat : 10|2@0+ (1,0) [0|3] "SED"  IPC
 SG_ WndwPsngrRear_D_RqBalrl : 25|2@0+ (1,0) [0|3] "SED" Vector__XXX
 SG_ WndwPsngr_D_RqBalrl : 27|2@0+ (1,0) [0|3] "SED" Vector__XXX
 SG_ WndwDrvRear_D_RqBalrl : 29|2@0+ (1,0) [0|3] "SED" Vector__XXX
 SG_ WndwDrv_D_RqBalrl : 31|2@0+ (1,0) [0|3] "SED" Vector__XXX
 SG_ BalrSnsLeft_D_Falt : 21|2@0+ (1,0) [0|3] "SED"  IPC
 SG_ BalrMdeSelLeft_B_Stat : 8|1@0+ (1,0) [0|1] "SED"  IPC
 SG_ BalrMdeLeft_D_Stat : 23|2@0+ (1,0) [0|3] "SED"  IPC
 SG_ BalrLckLeft_B_Stat : 11|1@0+ (1,0) [0|1] "SED"  IPC
 SG_ CamraRearOn_B_RqBalrl : 7|1@0+ (1,0) [0|1] "SED"  APIM,APIM_CISM,ACM,TRM_ITRM
 SG_ DrLckCnt_No_ActlBalrl : 5|3@0+ (1,0) [0|7] "unitless" Vector__XXX
 SG_ DrLckActv_B_RqBalrl : 6|1@0+ (1,0) [0|1] "SED" Vector__XXX
 SG_ BalrWndwLeft_B_Stat : 19|1@0+ (1,0) [0|1] "SED"  IPC

BO_ 788 PowertrainData_13_HS3: 8 GWM
 SG_ EcoCochDecel2_Pc_Dsply : 47|8@0+ (0.392157,0) [0|100.000035] "percent"  APIM,APIM_CISM
 SG_ EcoCochDecel1_Pc_Dsply : 39|8@0+ (0.392157,0) [0|100.000035] "percent"  APIM,APIM_CISM
 SG_ EcoCochCrus2_Pc_Dsply : 31|8@0+ (0.392157,0) [0|100.000035] "percent"  APIM,APIM_CISM
 SG_ EcoCochCrus1_Pc_Dsply : 23|8@0+ (0.392157,0) [0|100.000035] "percent"  APIM,APIM_CISM
 SG_ EcoCochATrip2_Pc_Dsply : 15|8@0+ (0.392157,0) [0|100.000035] "percent"  APIM,APIM_CISM
 SG_ EcoCochATrip1_Pc_Dsply : 7|8@0+ (0.392157,0) [0|100.000035] "percent"  APIM,APIM_CISM

BO_ 391 ACU_Request_Signals_3: 8 ACM
 SG_ ACU_CtrlChimeChan_Rq : 7|2@0+ (1,0) [0|3] "SED"  DSP

BO_ 670 Driver_Dr_Stat2_HS3: 8 GWM
 SG_ DrHandleOuterRl_D_Stat : 4|3@0+ (1,0) [0|7] "SED"  IPC
 SG_ DrHandleOuterFl_D_Stat : 7|3@0+ (1,0) [0|7] "SED"  IPC

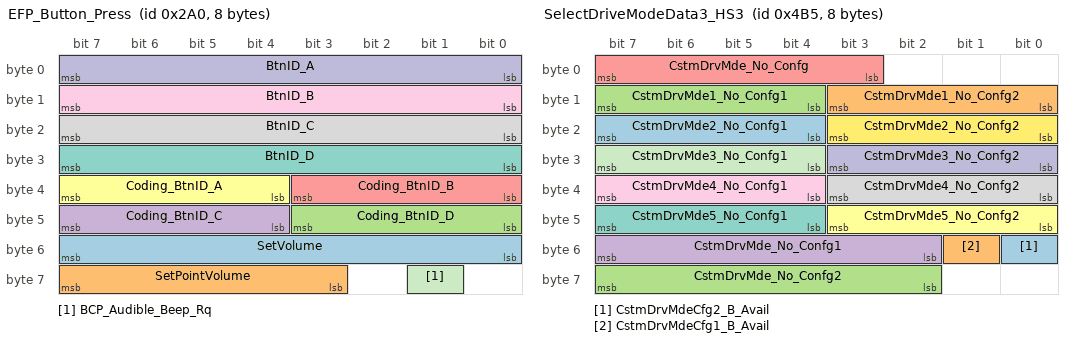
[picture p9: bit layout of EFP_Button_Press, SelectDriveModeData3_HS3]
BO_ 672 EFP_Button_Press: 8 FCIMB
 SG_ SetVolume : 55|8@0+ (1,-30) [-30|30] "unitless"  APIM,APIM_CISM,GWM,DSP,ACM
 SG_ SetPointVolume : 63|5@0+ (1,0) [0|31] "unitless"  APIM,APIM_CISM,GWM,DSP,ACM
 SG_ Coding_BtnID_D : 43|4@0+ (1,0) [0|15] "SED"  APIM,APIM_CISM,ACM
 SG_ Coding_BtnID_C : 47|4@0+ (1,0) [0|15] "SED"  APIM,APIM_CISM,ACM
 SG_ Coding_BtnID_B : 35|4@0+ (1,0) [0|15] "SED"  APIM,APIM_CISM,ACM
 SG_ Coding_BtnID_A : 39|4@0+ (1,0) [0|15] "SED"  APIM,APIM_CISM,ACM
 SG_ BtnID_D : 31|8@0+ (1,0) [0|255] "unitless"  APIM,APIM_CISM,ACM
 SG_ BtnID_C : 23|8@0+ (1,0) [0|255] "unitless"  APIM,APIM_CISM,ACM
 SG_ BtnID_B : 15|8@0+ (1,0) [0|255] "unitless"  APIM,APIM_CISM,ACM
 SG_ BtnID_A : 7|8@0+ (1,0) [0|255] "unitless"  APIM,APIM_CISM,ACM
 SG_ BCP_Audible_Beep_Rq : 57|1@0+ (1,0) [0|1] "SED"  APIM_CISM,ACM,DSP

BO_ 1205 SelectDriveModeData3_HS3: 8 GWM
 SG_ CstmDrvMdeCfg2_B_Avail : 48|1@0+ (1,0) [0|1] "SED"  IPC
 SG_ CstmDrvMdeCfg1_B_Avail : 49|1@0+ (1,0) [0|1] "SED"  IPC
 SG_ CstmDrvMde_No_Confg2 : 63|6@0+ (1,0) [0|63] "unitless"  IPC
 SG_ CstmDrvMde_No_Confg1 : 55|6@0+ (1,0) [0|63] "unitless"  IPC
 SG_ CstmDrvMde_No_Confg : 7|5@0+ (1,0) [0|31] "unitless"  IPC
 SG_ CstmDrvMde5_No_Confg2 : 43|4@0+ (1,0) [0|15] "unitless"  IPC
 SG_ CstmDrvMde5_No_Confg1 : 47|4@0+ (1,0) [0|15] "unitless"  IPC
 SG_ CstmDrvMde4_No_Confg2 : 35|4@0+ (1,0) [0|15] "unitless"  IPC
 SG_ CstmDrvMde4_No_Confg1 : 39|4@0+ (1,0) [0|15] "unitless"  IPC
 SG_ CstmDrvMde3_No_Confg2 : 27|4@0+ (1,0) [0|15] "unitless"  IPC
 SG_ CstmDrvMde3_No_Confg1 : 31|4@0+ (1,0) [0|15] "unitless"  IPC
 SG_ CstmDrvMde2_No_Confg2 : 19|4@0+ (1,0) [0|15] "unitless"  IPC
 SG_ CstmDrvMde2_No_Confg1 : 23|4@0+ (1,0) [0|15] "unitless"  IPC
 SG_ CstmDrvMde1_No_Confg2 : 11|4@0+ (1,0) [0|15] "unitless"  IPC
 SG_ CstmDrvMde1_No_Confg1 : 15|4@0+ (1,0) [0|15] "unitless"  IPC

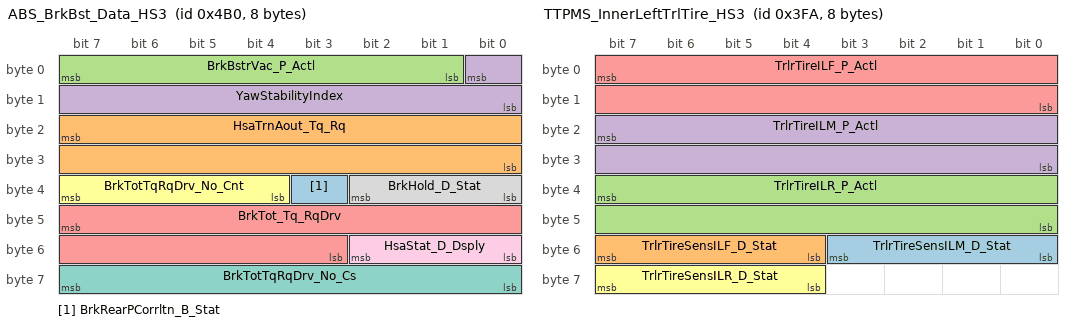
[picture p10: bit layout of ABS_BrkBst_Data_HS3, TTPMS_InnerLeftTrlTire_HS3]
BO_ 1200 ABS_BrkBst_Data_HS3: 8 GWM
 SG_ BrkRearPCorrltn_B_Stat : 35|1@0+ (1,0) [0|1] "SED" Vector__XXX
 SG_ HsaTrnAout_Tq_Rq : 23|16@0+ (4,-131072) [-131072|131060] "Nm" Vector__XXX
 SG_ BrkBstrVac_P_Actl : 7|7@0+ (8,0) [0|1008] "millibar" Vector__XXX
 SG_ YawStabilityIndex : 0|9@0+ (1,-256) [-256|255] "%" Vector__XXX
 SG_ BrkTot_Tq_RqDrv : 47|13@0+ (4,0) [0|32760] "Nm"  APIM,APIM_CISM
 SG_ BrkTotTqRqDrv_No_Cnt : 39|4@0+ (1,0) [0|15] "unitless" Vector__XXX
 SG_ BrkTotTqRqDrv_No_Cs : 63|8@0+ (1,0) [0|255] "unitless" Vector__XXX
 SG_ BrkHold_D_Stat : 34|3@0+ (1,0) [0|7] "SED" Vector__XXX
 SG_ HsaStat_D_Dsply : 50|3@0+ (1,0) [0|7] "SED" Vector__XXX

BO_ 593 ECG_MC_WORD_Tx: 8 GWM
 SG_ ECG_MC_WORD_Tx : 7|64@0+ (1,0) [0|1.84467440737096E+019] "unitless"  IPC

BO_ 601 ECG_MC_WORD_Rx: 8 IPC
 SG_ ECG_MC_WORD_Rx : 7|64@0+ (1,0) [0|1.84467440737096E+019] "unitless"  GWM

BO_ 1018 TTPMS_InnerLeftTrlTire_HS3: 8 GWM
 SG_ TrlrTireSensILM_D_Stat : 51|4@0+ (1,0) [0|15] "SED"  APIM,APIM_CISM,IPC
 SG_ TrlrTireSensILF_D_Stat : 55|4@0+ (1,0) [0|15] "SED"  APIM,APIM_CISM,IPC
 SG_ TrlrTireILR_P_Actl : 39|16@0+ (1,0) [0|65533] "kilopascal"  APIM,APIM_CISM,IPC
 SG_ TrlrTireILM_P_Actl : 23|16@0+ (1,0) [0|65533] "kilopascal"  APIM,APIM_CISM,IPC
 SG_ TrlrTireILF_P_Actl : 7|16@0+ (1,0) [0|65533] "kilopascal"  APIM,APIM_CISM,IPC
 SG_ TrlrTireSensILR_D_Stat : 63|4@0+ (1,0) [0|15] "SED"  APIM,APIM_CISM,IPC

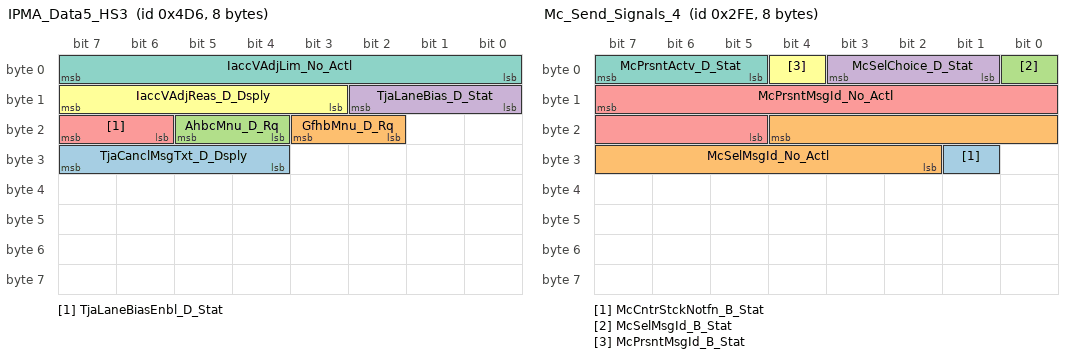
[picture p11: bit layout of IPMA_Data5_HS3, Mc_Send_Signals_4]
BO_ 1238 IPMA_Data5_HS3: 8 GWM
 SG_ TjaCanclMsgTxt_D_Dsply : 31|4@0+ (1,0) [0|15] "SED" Vector__XXX
 SG_ GfhbMnu_D_Rq : 19|2@0+ (1,0) [0|3] "SED"  APIM,IPC,APIM_CISM
 SG_ AhbcMnu_D_Rq : 21|2@0+ (1,0) [0|3] "SED"  APIM,IPC,APIM_CISM
 SG_ TjaLaneBias_D_Stat : 10|3@0+ (1,0) [0|7] "SED"  IPC
 SG_ TjaLaneBiasEnbl_D_Stat : 23|2@0+ (1,0) [0|3] "SED"  APIM,APIM_CISM
 SG_ IaccVAdjReas_D_Dsply : 15|5@0+ (1,0) [0|31] "SED"  APIM,APIM_CISM,IPC
 SG_ IaccVAdjLim_No_Actl : 7|8@0+ (1,0) [0|255] "unitless"  APIM,APIM_CISM,IPC

BO_ 766 Mc_Send_Signals_4: 8 APIM
 SG_ McCntrStckNotfn_B_Stat : 25|1@0+ (1,0) [0|1] "SED"  IPC
 SG_ McSelMsgId_No_Actl : 20|11@0+ (1,0) [0|2047] "unitless"  IPC
 SG_ McSelMsgId_B_Stat : 0|1@0+ (1,0) [0|1] "SED"  IPC
 SG_ McSelChoice_D_Stat : 3|3@0+ (1,0) [0|7] "SED"  IPC
 SG_ McPrsntMsgId_No_Actl : 15|11@0+ (1,0) [0|2047] "unitless"  IPC
 SG_ McPrsntMsgId_B_Stat : 4|1@0+ (1,0) [0|1] "SED"  IPC
 SG_ McPrsntActv_D_Stat : 7|3@0+ (1,0) [0|7] "SED"  IPC

BO_ 840 FoH_Day_Req: 8 IPC
 SG_ FohAddHeater_D_Rq : 9|2@0+ (1,0) [0|3] "SED"  GWM
 SG_ FohStrtDateYr_No_Rq : 39|8@0+ (1,2000) [2000|2255] "year"  GWM
 SG_ FohStrtDateDay_No_Rq : 23|16@0+ (1,0) [0|65535] "julian day"  GWM
 SG_ FohT2Friday_T_Rq : 0|1@0+ (1,0) [0|1] "SED"  GWM
 SG_ FohT1Friday_T_Rq : 7|1@0+ (1,0) [0|1] "SED"  GWM
 SG_ FohT2Wednesday_T_Rq : 10|1@0+ (1,0) [0|1] "SED"  GWM
 SG_ FohT2Tuesday_T_Rq : 11|1@0+ (1,0) [0|1] "SED"  GWM
 SG_ FohT2Thursday_T_Rq : 12|1@0+ (1,0) [0|1] "SED"  GWM
 SG_ FohT2Sunday_T_Rq : 13|1@0+ (1,0) [0|1] "SED"  GWM
 SG_ FohT2Saturday_T_Rq : 14|1@0+ (1,0) [0|1] "SED"  GWM
 SG_ FohT2Monday_T_Rq : 15|1@0+ (1,0) [0|1] "SED"  GWM
 SG_ FohT1Wednesday_T_Rq : 1|1@0+ (1,0) [0|1] "SED"  GWM
 SG_ FohT1Tuesday_T_Rq : 2|1@0+ (1,0) [0|1] "SED"  GWM
 SG_ FohT1Thursday_T_Rq : 3|1@0+ (1,0) [0|1] "SED"  GWM
 SG_ FohT1Sunday_T_Rq : 4|1@0+ (1,0) [0|1] "SED"  GWM
 SG_ FohT1Saturday_T_Rq : 5|1@0+ (1,0) [0|1] "SED"  GWM
 SG_ FohT1Monday_T_Rq : 6|1@0+ (1,0) [0|1] "SED"  GWM

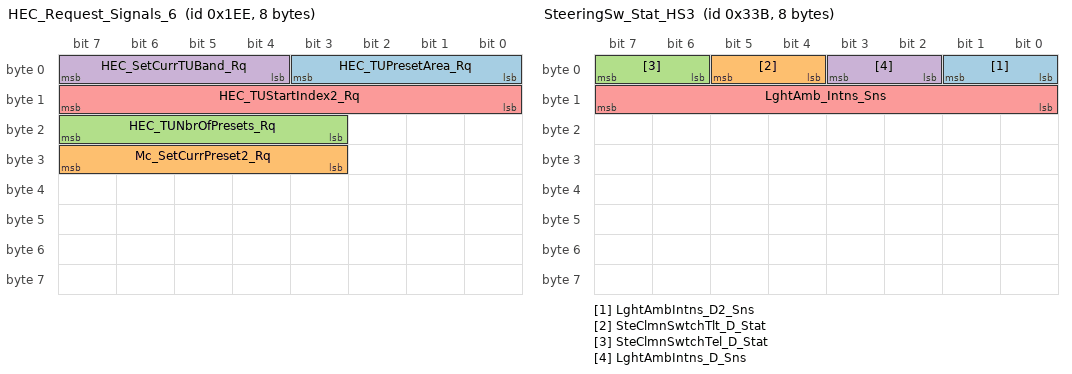
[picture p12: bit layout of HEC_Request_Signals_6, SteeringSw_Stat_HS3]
BO_ 494 HEC_Request_Signals_6: 8 IPC
 SG_ HEC_TUPresetArea_Rq : 3|4@0+ (1,0) [0|15] "SED"  APIM_CISM,ACM
 SG_ Mc_SetCurrPreset2_Rq : 31|5@0+ (1,0) [0|30] "SED"  APIM_CISM,ACM
 SG_ HEC_TUNbrOfPresets_Rq : 23|5@0+ (1,0) [0|30] "unitless"  APIM_CISM,ACM
 SG_ HEC_SetCurrTUBand_Rq : 7|4@0+ (1,0) [0|15] "SED"  APIM_CISM,ACM
 SG_ HEC_TUStartIndex2_Rq : 15|8@0+ (1,0) [0|255] "unitless"  APIM_CISM,ACM

BO_ 714 SDARS_MC_WORD_Rx: 8 IPC
 SG_ SDARS_MC_WORD_Rx : 7|64@0+ (1,0) [0|1.84467440737096E+019] "unitless"  APIM_CISM,ACM

BO_ 498 HEC_Request_Signals_3: 8 IPC
 SG_ HEC_ARReqstrPriority_Rq : 11|4@0+ (1,0) [0|15] "SED"  APIM_CISM,ACM
 SG_ HEC_AROperationType_Rq : 7|3@0+ (1,0) [0|7] "SED"  APIM_CISM,ACM
 SG_ HEC_ARReqstrSystem_Rq : 4|1@0+ (1,0) [0|1] "SED"  APIM_CISM,ACM
 SG_ HEC_ARAudioSource_Rq : 3|4@0+ (1,0) [0|15] "SED"  APIM_CISM,ACM

BO_ 145 MFD_DateTime: 8 APIM
 SG_ MFD_Year : 7|8@0+ (1,2000) [2000|2254] "year"  DSP,IPC,RACM_RCIM
 SG_ MFD_Second : 39|8@0+ (1,0) [0|59] "second"  DSP,IPC,RACM_RCIM
 SG_ MFD_Month : 15|8@0+ (1,0) [0|12] "month"  DSP,IPC,RACM_RCIM
 SG_ MFD_Minute : 47|8@0+ (1,0) [0|59] "minute"  DSP,IPC,RACM_RCIM
 SG_ MFD_Hour : 31|8@0+ (1,0) [0|23] "hour"  DSP,IPC,RACM_RCIM
 SG_ MFD_Day : 23|8@0+ (1,0) [0|31] "day"  DSP,IPC,RACM_RCIM

BO_ 607 RDRV_RSE_WORD_Rx: 8 RACM_RCIM
 SG_ RDRV_RSE_WORD_Rx : 7|64@0+ (1,0) [0|1.84467440737096E+019] "unitless"  GENERIC

BO_ 598 CONMP_RSE_WORD_Tx: 8 APIM
 SG_ CONMP_RSE_WORD_Tx : 7|64@0+ (1,0) [0|1.84467440737096E+019] "unitless"  RACM_RCIM

BO_ 606 CONMP_RSE_WORD_Rx: 8 RACM_RCIM
 SG_ CONMP_RSE_WORD_Rx : 7|64@0+ (1,0) [0|1.84467440737096E+019] "unitless"  APIM,APIM_CISM

BO_ 597 AUDIO_RSE_WORD_Tx: 8 APIM
 SG_ AUDIO_RSE_WORD_Tx : 7|64@0+ (1,0) [0|1.84467440737096E+019] "unitless"  RACM_RCIM

BO_ 605 AUDIO_RSE_WORD_Rx: 8 RACM_RCIM
 SG_ AUDIO_RSE_WORD_Rx : 7|64@0+ (1,0) [0|1.84467440737096E+019] "unitless"  APIM_CISM,ACM

BO_ 827 SteeringSw_Stat_HS3: 8 GWM
 SG_ LghtAmbIntns_D2_Sns : 1|2@0+ (1,0) [0|3] "SED"  HUD_ADV
 SG_ SteClmnSwtchTlt_D_Stat : 5|2@0+ (1,0) [0|3] "SED" Vector__XXX
 SG_ SteClmnSwtchTel_D_Stat : 7|2@0+ (1,0) [0|3] "SED" Vector__XXX
 SG_ LghtAmbIntns_D_Sns : 3|2@0+ (1,0) [0|3] "SED"  HUD_ADV
 SG_ LghtAmb_Intns_Sns : 15|8@0+ (1,0) [0|255] "unitless"  HUD_ADV

BO_ 1043 ABS_BrkData_HS3: 8 GWM
 SG_ PrkBrkApplCpblty_B_Stat : 42|1@0+ (1,0) [0|1] "SED" Vector__XXX
 SG_ PrkBrkPerfActv_B_Stat : 32|1@0+ (1,0) [0|1] "SED" Vector__XXX
 SG_ PrkBrkPerfMde_D_Stat : 34|2@0+ (1,0) [0|3] "SED"  APIM,IPC,APIM_CISM
 SG_ PrkBrkPerfMsgTxt_D_Rq : 63|5@0+ (1,0) [0|31] "SED"  APIM,IPC,APIM_CISM
 SG_ SelDrvMdeHmi04_D_Rq : 55|5@0+ (1,0) [0|31] "SED"  APIM_CISM,ACM
 SG_ SelDrvMdeHmi02_D_Rq : 47|5@0+ (1,0) [0|31] "SED"  APIM,APIM_CISM,HUD_ADV,IPC
 SG_ IndvMde5_B_Avail : 35|1@0+ (1,0) [0|1] "SED"  IPC
 SG_ IndvMde4_B_Avail : 36|1@0+ (1,0) [0|1] "SED"  IPC
 SG_ IndvMde3_B_Avail : 37|1@0+ (1,0) [0|1] "SED"  IPC
 SG_ IndvMde2_B_Avail : 38|1@0+ (1,0) [0|1] "SED"  IPC
 SG_ IndvMde1_B_Avail : 39|1@0+ (1,0) [0|1] "SED"  IPC
 SG_ IndvMdeSusp_No_Stat : 27|4@0+ (1,0) [0|15] "unitless"  IPC
 SG_ IndvMdeSte_No_Stat : 31|4@0+ (1,0) [0|15] "unitless"  IPC
 SG_ IndvMdeSel_No_Rq : 19|4@0+ (1,0) [0|15] "unitless"  IPC
 SG_ IndvMdeSel_D_Stat : 9|2@0+ (1,0) [0|3] "SED"  IPC
 SG_ IndvMdeMsgTxt_D_Rq : 23|4@0+ (1,0) [0|15] "SED"  IPC
 SG_ TrailOnePdlMsgTxt_D_Rq : 12|3@0+ (1,0) [0|7] "SED"  APIM_CISM,IPC
 SG_ TrailOnePdlMde_D_Ind : 15|3@0+ (1,0) [0|7] "SED"  APIM_CISM,IPC
 SG_ OrtaSwtchLamp_B_Rq : 0|1@0+ (1,0) [0|1] "SED"  APIM,APIM_CISM
 SG_ OrtaMsgTxt_D_Rq : 4|4@0+ (1,0) [0|15] "SED"  APIM,APIM_CISM,IPC
 SG_ OrtaMde_D_Ind : 7|3@0+ (1,0) [0|7] "SED"  APIM,APIM_CISM,IPC

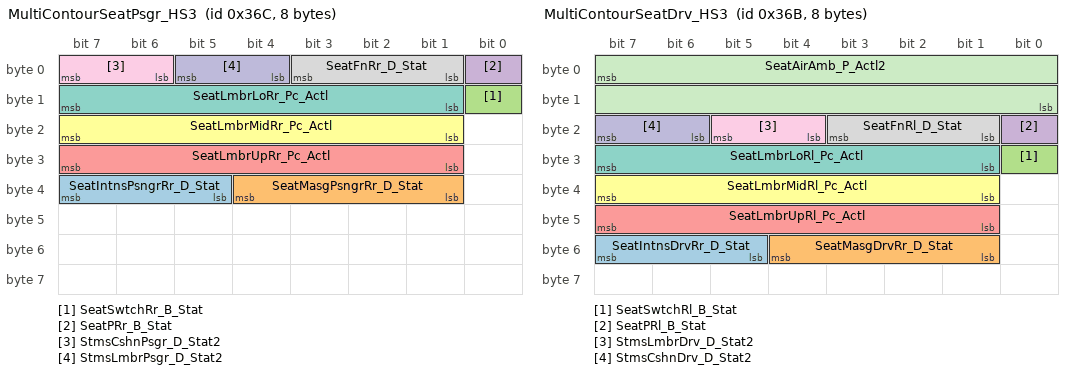
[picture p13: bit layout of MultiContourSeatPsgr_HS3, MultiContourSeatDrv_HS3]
BO_ 876 MultiContourSeatPsgr_HS3: 8 GWM
 SG_ SeatIntnsPsngrRr_D_Stat : 39|3@0+ (1,0) [0|7] "SED"  GENERIC
 SG_ SeatMasgPsngrRr_D_Stat : 36|4@0+ (1,0) [0|15] "SED"  GENERIC
 SG_ SeatSwtchRr_B_Stat : 8|1@0+ (1,0) [0|1] "SED"  RACM_RCIM
 SG_ SeatPRr_B_Stat : 0|1@0+ (1,0) [0|1] "SED"  RACM_RCIM
 SG_ SeatLmbrUpRr_Pc_Actl : 31|7@0+ (1,0) [0|127] "Percent"  RACM_RCIM
 SG_ SeatLmbrMidRr_Pc_Actl : 23|7@0+ (1,0) [0|127] "Percent" Vector__XXX
 SG_ SeatLmbrLoRr_Pc_Actl : 15|7@0+ (1,0) [0|127] "Percent"  RACM_RCIM
 SG_ SeatFnRr_D_Stat : 3|3@0+ (1,0) [0|7] "SED"  RACM_RCIM
 SG_ StmsCshnPsgr_D_Stat2 : 7|2@0+ (1,0) [0|3] "SED"  RACM_RCIM
 SG_ StmsLmbrPsgr_D_Stat2 : 5|2@0+ (1,0) [0|3] "SED"  RACM_RCIM

BO_ 875 MultiContourSeatDrv_HS3: 8 GWM
 SG_ SeatIntnsDrvRr_D_Stat : 55|3@0+ (1,0) [0|7] "SED"  GENERIC
 SG_ SeatMasgDrvRr_D_Stat : 52|4@0+ (1,0) [0|15] "SED"  GENERIC
 SG_ SeatSwtchRl_B_Stat : 24|1@0+ (1,0) [0|1] "SED"  RACM_RCIM
 SG_ SeatPRl_B_Stat : 16|1@0+ (1,0) [0|1] "SED"  RACM_RCIM
 SG_ SeatLmbrUpRl_Pc_Actl : 47|7@0+ (1,0) [0|127] "Percent"  RACM_RCIM
 SG_ SeatLmbrMidRl_Pc_Actl : 39|7@0+ (1,0) [0|127] "Percent"  RACM_RCIM
 SG_ SeatLmbrLoRl_Pc_Actl : 31|7@0+ (1,0) [0|127] "Percent"  RACM_RCIM
 SG_ SeatFnRl_D_Stat : 19|3@0+ (1,0) [0|7] "SED"  RACM_RCIM
 SG_ StmsLmbrDrv_D_Stat2 : 21|2@0+ (1,0) [0|3] "SED"  RACM_RCIM
 SG_ StmsCshnDrv_D_Stat2 : 23|2@0+ (1,0) [0|3] "SED"  RACM_RCIM
 SG_ SeatAirAmb_P_Actl2 : 7|16@0+ (0.01,0) [0|655.35] "kilopascal"  RACM_RCIM

BO_ 545 DSPAMP_Send_Signals_1: 8 DSP
 SG_ SpkrDgtlRight_D_Stat : 47|2@0+ (1,0) [0|3] "SED"  GENERIC
 SG_ SpkrDgtlLeft_D_Stat : 45|2@0+ (1,0) [0|3] "SED"  GENERIC
 SG_ SpkrDgtlCntr_D_Stat : 43|2@0+ (1,0) [0|3] "SED"  APIM_CISM,ACM
 SG_ SurndSndUpmix2_D_Stat : 34|3@0+ (1,0) [0|7] "SED"  APIM,APIM_CISM
 SG_ DSP_Bezel_Diag_St : 23|4@0+ (1,0) [0|15] "SED"  APIM,APIM_CISM
 SG_ SndImmrsnLvl_D_Stat : 55|8@0+ (1,0) [0|255] "SED"  APIM,APIM_CISM
 SG_ DSP_Sur_Sound_st : 7|2@0+ (1,0) [0|3] "SED"  APIM,APIM_CISM
 SG_ DSP_MyKeyVolLimitUp_St : 19|2@0+ (1,0) [0|3] "SED"  APIM,APIM_CISM
 SG_ DSP_MyKeyVolLim_St : 2|2@0+ (1,0) [0|3] "SED"  APIM,APIM_CISM
 SG_ DSP_BeltminderAudio_St : 4|2@0+ (1,0) [0|3] "SED"  APIM,APIM_CISM
 SG_ DSP_Audio_Volume_Up_St : 9|1@0+ (1,0) [0|1] "SED"  APIM,APIM_CISM,IPC,ACM,HUD_ADV,RACM_RCIM,GWM
 SG_ DSP_Audio_Vol_Level_St : 15|5@0+ (1,0) [0|30] "unitless"  APIM,APIM_CISM,IPC,ACM,HUD_ADV,RACM_RCIM,WCM
 SG_ AutoConfigOcc_Rear : 28|1@0+ (1,0) [0|1] "SED"  APIM,APIM_CISM
 SG_ AutoConfigOcc_Front : 30|1@0+ (1,0) [0|1] "SED"  APIM,APIM_CISM
 SG_ AutoConfigOcc_Driver : 31|1@0+ (1,0) [0|1] "SED"  APIM,APIM_CISM
 SG_ AutoConfigOcc_AllSeats : 29|1@0+ (1,0) [0|1] "SED"  APIM,APIM_CISM
 SG_ AudioOccMde_D_Stat : 39|5@0+ (1,0) [0|31] "SED"  APIM,APIM_CISM

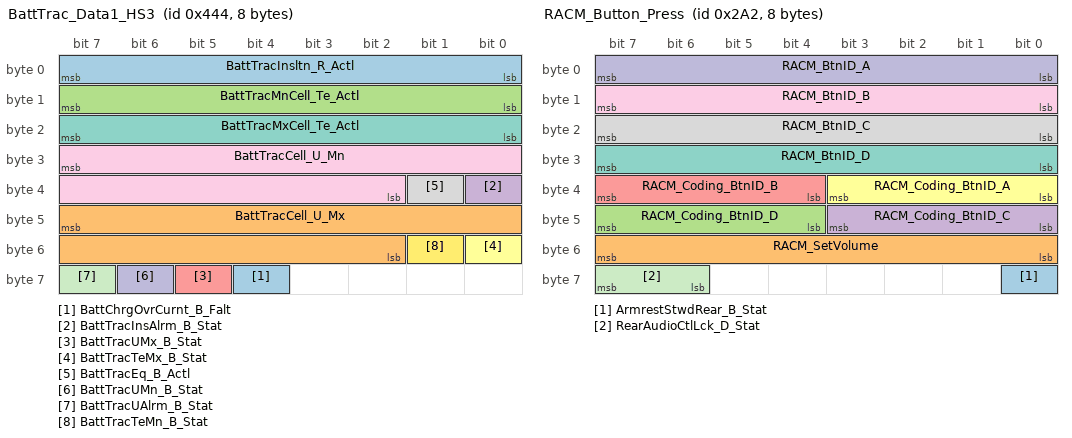
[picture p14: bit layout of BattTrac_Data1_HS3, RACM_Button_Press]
BO_ 1092 BattTrac_Data1_HS3: 8 GWM
 SG_ BattChrgOvrCurnt_B_Falt : 60|1@0+ (1,0) [0|1] "SED"  GENERIC
 SG_ BattTracCell_U_Mx : 47|14@0+ (0.001,0) [0|16.382] "volt" Vector__XXX
 SG_ BattTracMnCell_Te_Actl : 15|8@0+ (1,-40) [-40|213] "degC" Vector__XXX
 SG_ BattTracInsAlrm_B_Stat : 32|1@0+ (1,0) [0|1] "SED" Vector__XXX
 SG_ BattTracUMx_B_Stat : 61|1@0+ (1,0) [0|1] "SED" Vector__XXX
 SG_ BattTracTeMx_B_Stat : 48|1@0+ (1,0) [0|1] "SED" Vector__XXX
 SG_ BattTracMxCell_Te_Actl : 23|8@0+ (1,-40) [-40|213] "degC" Vector__XXX
 SG_ BattTracEq_B_Actl : 33|1@0+ (1,0) [0|1] "SED" Vector__XXX
 SG_ BattTracCell_U_Mn : 31|14@0+ (0.001,0) [0|16.382] "volt" Vector__XXX
 SG_ BattTracUMn_B_Stat : 62|1@0+ (1,0) [0|1] "SED" Vector__XXX
 SG_ BattTracUAlrm_B_Stat : 63|1@0+ (1,0) [0|1] "SED" Vector__XXX
 SG_ BattTracTeMn_B_Stat : 49|1@0+ (1,0) [0|1] "SED" Vector__XXX
 SG_ BattTracInsltn_R_Actl : 7|8@0+ (6000,0) [0|1524000] "ohm" Vector__XXX

BO_ 936 ParkAid_Data_HS3: 8 GWM
 SG_ SAPPStatusCoding : 7|8@0+ (1,0) [0|255] "unitless"  APIM,APIM_CISM
 SG_ ApaButtnPrssd_B_Stat : 58|1@0+ (1,0) [0|1] "SED"  GENERIC
 SG_ ApaSys_D_Stat : 61|3@0+ (1,0) [0|7] "SED"  APIM,APIM_CISM,IPC,ACM
 SG_ ApaSteWhl_D_RqDrv : 63|2@0+ (1,0) [0|3] "SED"  APIM,APIM_CISM,ACM
 SG_ ApaSteScanMde_D_Stat : 49|2@0+ (1,0) [0|3] "SED"  APIM,APIM_CISM,ACM
 SG_ ApaSelSapp_D_Stat : 51|2@0+ (1,0) [0|3] "SED"  APIM,APIM_CISM,ACM
 SG_ ApaSelPpa_D_Stat : 53|2@0+ (1,0) [0|3] "SED"  APIM,APIM_CISM,ACM
 SG_ ApaSelPoa_D_Stat : 55|2@0+ (1,0) [0|3] "SED"  APIM,APIM_CISM,ACM
 SG_ ApaScan_D_Stat : 41|2@0+ (1,0) [0|3] "SED"  APIM,APIM_CISM,ACM
 SG_ ApaLongCtl_D_RqDrv : 44|3@0+ (1,0) [0|7] "SED"  APIM,APIM_CISM,ACM
 SG_ ApaGearShif_D_RqDrv : 47|3@0+ (1,0) [0|7] "SED"  APIM,APIM_CISM,ACM
 SG_ ApaActvSide2_D_Stat : 33|2@0+ (1,0) [0|3] "SED"  APIM,APIM_CISM,ACM
 SG_ ApaAcsy_D_RqDrv : 36|3@0+ (1,0) [0|7] "SED"  APIM,APIM_CISM,ACM
 SG_ ApaChime_D_Rq : 39|3@0+ (1,0) [0|7] "SED"  IPC
 SG_ EPASExtAngleStatReq : 23|1@0+ (1,0) [0|1] "SED" Vector__XXX
 SG_ ExtSteeringAngleReq2 : 22|15@0+ (0.1,-1000) [-1000|2276.5] "degrees" Vector__XXX
 SG_ ApaTrgtDist_D_Stat : 11|4@0+ (1,0) [0|15] "SED"  APIM,APIM_CISM,ACM
 SG_ ApaMsgTxt_D_Rq : 15|4@0+ (1,0) [0|15] "SED"  APIM,APIM_CISM,ACM

BO_ 674 RACM_Button_Press: 8 RACM_RCIM
 SG_ ArmrestStwdRear_B_Stat : 56|1@0+ (1,0) [0|1] "SED"  GWM
 SG_ RACM_SetVolume : 55|8@0+ (1,-30) [-30|30] "unitless"  APIM,APIM_CISM
 SG_ RACM_Coding_BtnID_D : 47|4@0+ (1,0) [0|15] "SED"  APIM,APIM_CISM
 SG_ RACM_Coding_BtnID_C : 43|4@0+ (1,0) [0|15] "SED"  APIM,APIM_CISM
 SG_ RACM_Coding_BtnID_B : 39|4@0+ (1,0) [0|15] "SED"  APIM,APIM_CISM
 SG_ RACM_Coding_BtnID_A : 35|4@0+ (1,0) [0|15] "SED"  APIM,APIM_CISM
 SG_ RACM_BtnID_D : 31|8@0+ (1,0) [0|255] "unitless"  APIM,APIM_CISM
 SG_ RACM_BtnID_C : 23|8@0+ (1,0) [0|255] "unitless"  APIM,APIM_CISM
 SG_ RACM_BtnID_B : 15|8@0+ (1,0) [0|255] "unitless"  APIM,APIM_CISM
 SG_ RACM_BtnID_A : 7|8@0+ (1,0) [0|255] "unitless"  APIM,APIM_CISM
 SG_ RearAudioCtlLck_D_Stat : 63|2@0+ (1,0) [0|3] "SED"  APIM,APIM_CISM,FCIMB

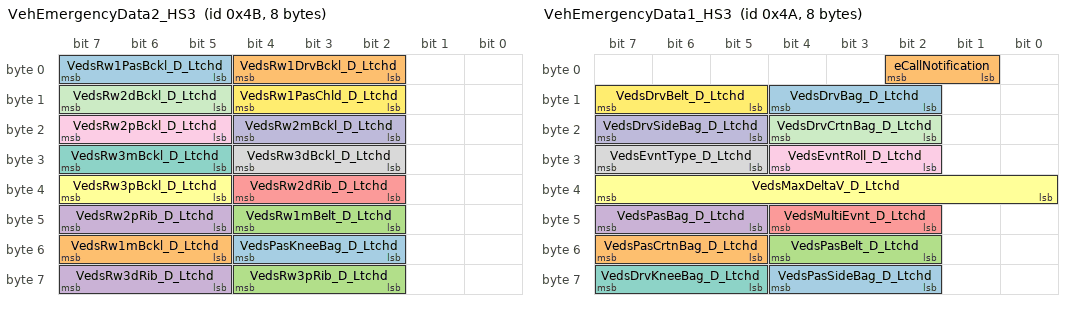
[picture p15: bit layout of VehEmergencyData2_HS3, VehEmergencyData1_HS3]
BO_ 75 VehEmergencyData2_HS3: 8 GWM
 SG_ VedsPasKneeBag_D_Ltchd : 52|3@0+ (1,0) [0|7] "SED"  APIM,APIM_CISM,ACM
 SG_ VedsRw1mBckl_D_Ltchd : 55|3@0+ (1,0) [0|7] "SED"  APIM,APIM_CISM
 SG_ VedsRw1mBelt_D_Ltchd : 44|3@0+ (1,0) [0|7] "SED"  APIM,APIM_CISM
 SG_ VedsRw2pRib_D_Ltchd : 47|3@0+ (1,0) [0|7] "SED"  APIM,APIM_CISM
 SG_ VedsRw2dRib_D_Ltchd : 36|3@0+ (1,0) [0|7] "SED"  APIM,APIM_CISM
 SG_ VedsRw3pBckl_D_Ltchd : 39|3@0+ (1,0) [0|7] "SED"  APIM,APIM_CISM
 SG_ VedsRw3mBckl_D_Ltchd : 31|3@0+ (1,0) [0|7] "SED"  APIM,APIM_CISM
 SG_ VedsRw3dBckl_D_Ltchd : 28|3@0+ (1,0) [0|7] "SED"  APIM,APIM_CISM
 SG_ VedsRw2pBckl_D_Ltchd : 23|3@0+ (1,0) [0|7] "SED"  APIM,APIM_CISM
 SG_ VedsRw2mBckl_D_Ltchd : 20|3@0+ (1,0) [0|7] "SED"  APIM,APIM_CISM
 SG_ VedsRw2dBckl_D_Ltchd : 15|3@0+ (1,0) [0|7] "SED"  APIM,APIM_CISM
 SG_ VedsRw1PasChld_D_Ltchd : 12|3@0+ (1,0) [0|7] "SED"  APIM,APIM_CISM
 SG_ VedsRw1PasBckl_D_Ltchd : 7|3@0+ (1,0) [0|7] "SED"  APIM,APIM_CISM
 SG_ VedsRw1DrvBckl_D_Ltchd : 4|3@0+ (1,0) [0|7] "SED"  APIM,APIM_CISM
 SG_ VedsRw3pRib_D_Ltchd : 60|3@0+ (1,0) [0|7] "SED"  APIM,APIM_CISM
 SG_ VedsRw3dRib_D_Ltchd : 63|3@0+ (1,0) [0|7] "SED"  APIM,APIM_CISM

BO_ 74 VehEmergencyData1_HS3: 8 GWM
 SG_ VedsPasSideBag_D_Ltchd : 60|3@0+ (1,0) [0|7] "SED"  APIM,APIM_CISM
 SG_ VedsPasCrtnBag_D_Ltchd : 55|3@0+ (1,0) [0|7] "SED"  APIM,APIM_CISM
 SG_ VedsPasBelt_D_Ltchd : 52|3@0+ (1,0) [0|7] "SED"  APIM,APIM_CISM
 SG_ VedsPasBag_D_Ltchd : 47|3@0+ (1,0) [0|7] "SED"  APIM,APIM_CISM
 SG_ VedsMultiEvnt_D_Ltchd : 44|3@0+ (1,0) [0|7] "SED"  APIM,APIM_CISM
 SG_ VedsMaxDeltaV_D_Ltchd : 39|8@0+ (1,0) [0|255] "kph"  APIM,APIM_CISM
 SG_ VedsDrvKneeBag_D_Ltchd : 63|3@0+ (1,0) [0|7] "SED"  APIM,APIM_CISM
 SG_ VedsEvntType_D_Ltchd : 31|3@0+ (1,0) [0|7] "SED"  APIM,APIM_CISM
 SG_ VedsEvntRoll_D_Ltchd : 28|3@0+ (1,0) [0|7] "SED"  APIM,APIM_CISM
 SG_ VedsDrvSideBag_D_Ltchd : 23|3@0+ (1,0) [0|7] "SED"  APIM,APIM_CISM
 SG_ VedsDrvCrtnBag_D_Ltchd : 20|3@0+ (1,0) [0|7] "SED"  APIM,APIM_CISM
 SG_ VedsDrvBelt_D_Ltchd : 15|3@0+ (1,0) [0|7] "SED"  APIM,APIM_CISM
 SG_ VedsDrvBag_D_Ltchd : 12|3@0+ (1,0) [0|7] "SED"  APIM,APIM_CISM,ACM
 SG_ eCallNotification : 2|2@0+ (1,0) [0|3] "SED"  APIM,APIM_CISM

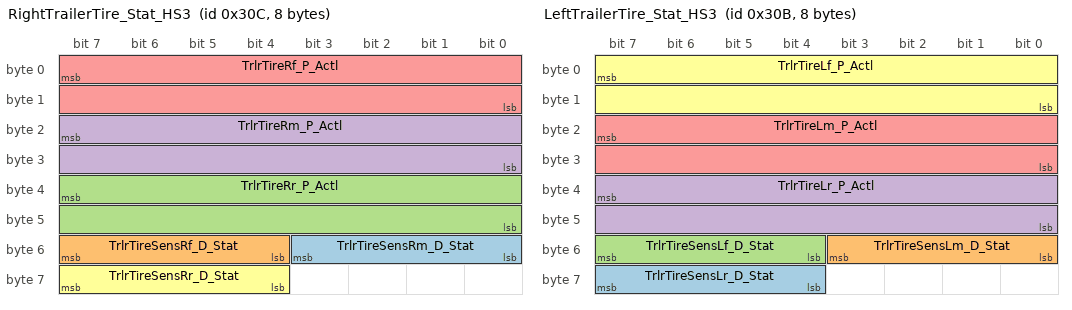
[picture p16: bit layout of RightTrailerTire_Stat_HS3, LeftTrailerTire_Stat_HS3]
BO_ 780 RightTrailerTire_Stat_HS3: 8 GWM
 SG_ TrlrTireSensRm_D_Stat : 51|4@0+ (1,0) [0|15] "SED"  IPC
 SG_ TrlrTireSensRf_D_Stat : 55|4@0+ (1,0) [0|15] "SED"  IPC
 SG_ TrlrTireRr_P_Actl : 39|16@0+ (1,0) [0|65533] "kilopascal"  IPC
 SG_ TrlrTireRm_P_Actl : 23|16@0+ (1,0) [0|65533] "kilopascal"  IPC
 SG_ TrlrTireRf_P_Actl : 7|16@0+ (1,0) [0|65533] "kilopascal"  IPC
 SG_ TrlrTireSensRr_D_Stat : 63|4@0+ (1,0) [0|15] "SED"  IPC

BO_ 779 LeftTrailerTire_Stat_HS3: 8 GWM
 SG_ TrlrTireSensLr_D_Stat : 63|4@0+ (1,0) [0|15] "SED"  APIM_CISM,IPC
 SG_ TrlrTireSensLm_D_Stat : 51|4@0+ (1,0) [0|15] "SED"  APIM_CISM,IPC
 SG_ TrlrTireSensLf_D_Stat : 55|4@0+ (1,0) [0|15] "SED"  APIM_CISM,IPC
 SG_ TrlrTireLr_P_Actl : 39|16@0+ (1,0) [0|65533] "kilopascal"  APIM_CISM,IPC
 SG_ TrlrTireLm_P_Actl : 23|16@0+ (1,0) [0|65533] "kilopascal"  APIM_CISM,IPC
 SG_ TrlrTireLf_P_Actl : 7|16@0+ (1,0) [0|65533] "kilopascal"  APIM_CISM,IPC

BO_ 783 Cluster_TireData: 8 IPC
 SG_ TrlrTireThresh_D_RqDrv : 7|8@0+ (1,0) [0|255] "unitless"  GWM
 SG_ TrlrTireCnt_D_RqDrv : 15|3@0+ (1,0) [0|6] "SED"  GWM
 SG_ TrlrLearnMdeOn_B_RqDrv : 12|1@0+ (1,0) [0|1] "SED"  GWM

BO_ 638 TCU_Send_Signals_5_HS3: 8 GWM
 SG_ EmgcyCallHmi_D_Stat : 14|4@0+ (1,0) [0|15] "SED"  APIM,APIM_CISM
 SG_ EmgcyCallFalt_B_Dsply : 15|1@0+ (1,0) [0|1] "SED"  IPC
 SG_ EmgcyCallCancl_T_Actl : 4|5@0+ (1,0) [0|31] "second"  APIM,APIM_CISM
 SG_ EmgcyCall_D_Stat : 7|3@0+ (1,0) [0|7] "SED"  APIM,APIM_CISM

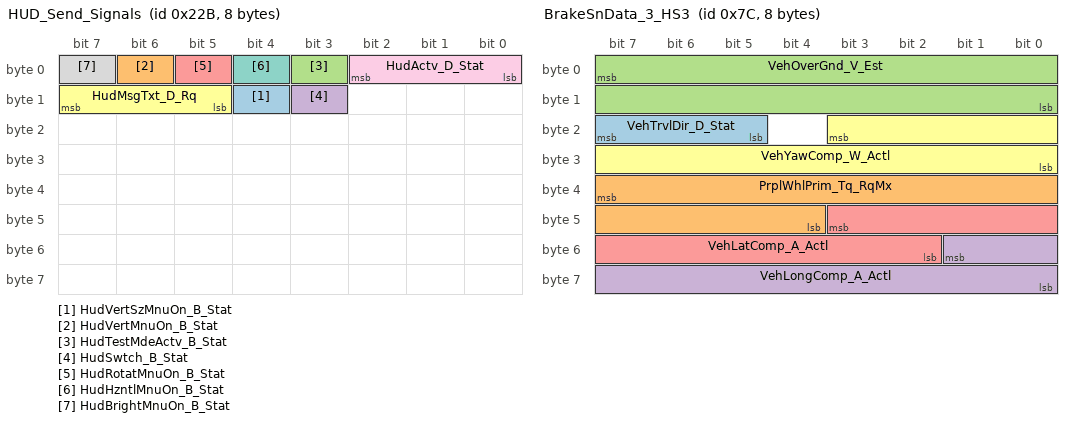
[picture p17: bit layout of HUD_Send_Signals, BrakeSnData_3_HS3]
BO_ 555 HUD_Send_Signals: 8 HUD_ADV
 SG_ HudVertSzMnuOn_B_Stat : 12|1@0+ (1,0) [0|1] "SED"  APIM_CISM,IPC
 SG_ HudVertMnuOn_B_Stat : 6|1@0+ (1,0) [0|1] "SED"  APIM_CISM,IPC
 SG_ HudTestMdeActv_B_Stat : 3|1@0+ (1,0) [0|1] "SED"  APIM_CISM,IPC
 SG_ HudSwtch_B_Stat : 11|1@0+ (1,0) [0|1] "SED"  APIM_CISM,IPC
 SG_ HudRotatMnuOn_B_Stat : 5|1@0+ (1,0) [0|1] "SED"  APIM_CISM,IPC
 SG_ HudMsgTxt_D_Rq : 15|3@0+ (1,0) [0|7] "SED"  APIM_CISM,IPC
 SG_ HudHzntlMnuOn_B_Stat : 4|1@0+ (1,0) [0|1] "SED"  APIM_CISM,IPC
 SG_ HudBrightMnuOn_B_Stat : 7|1@0+ (1,0) [0|1] "SED"  APIM_CISM,IPC
 SG_ HudActv_D_Stat : 2|3@0+ (1,0) [0|7] "SED"  APIM_CISM,IPC

BO_ 124 BrakeSnData_3_HS3: 8 GWM
 SG_ VehTrvlDir_D_Stat : 23|3@0+ (1,0) [0|7] "SED"  GENERIC
 SG_ PrplWhlPrim_Tq_RqMx : 39|12@0+ (8,0) [0|32760] "Nm"  GENERIC
 SG_ VehOverGnd_V_Est : 7|16@0+ (0.01,0) [0|655.33] "kph"  APIM,APIM_CISM,IPC
 SG_ VehLongComp_A_Actl : 49|10@0+ (0.035,-17.9) [-17.9|17.835] "m/s^2"  APIM,APIM_CISM,IPC
 SG_ VehLatComp_A_Actl : 43|10@0+ (0.035,-17.9) [-17.9|17.835] "m/s^2"  APIM,APIM_CISM,IPC
 SG_ VehYawComp_W_Actl : 19|12@0+ (0.03663,-75) [-75|74.92659] "deg/s"  APIM,APIM_CISM,IPC

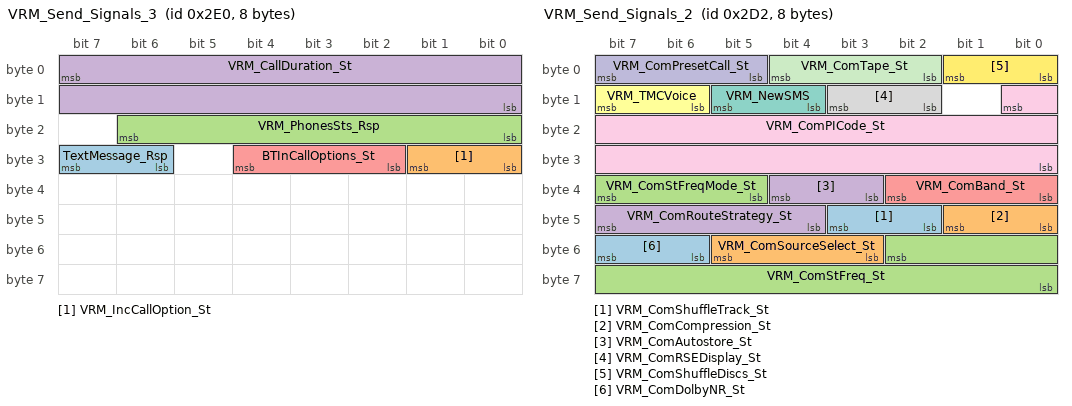
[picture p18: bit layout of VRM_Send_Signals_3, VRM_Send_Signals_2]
BO_ 736 VRM_Send_Signals_3: 8 APIM
 SG_ TextMessage_Rsp : 31|2@0+ (1,0) [0|3] "SED"  IPC
 SG_ VRM_IncCallOption_St : 25|2@0+ (1,0) [0|3] "SED"  GENERIC
 SG_ VRM_PhonesSts_Rsp : 22|7@0+ (1,0) [0|127] "unitless"  GENERIC
 SG_ VRM_CallDuration_St : 7|16@0+ (1,0) [0|65534] "second"  IPC
 SG_ BTInCallOptions_St : 28|3@0+ (1,0) [0|7] "SED"  IPC

BO_ 722 VRM_Send_Signals_2: 8 APIM
 SG_ VRM_ComShuffleTrack_St : 43|2@0+ (1,0) [0|3] "SED"  GENERIC
 SG_ VRM_ComCompression_St : 41|2@0+ (1,0) [0|3] "SED"  GENERIC
 SG_ VRM_ComStFreqMode_St : 39|3@0+ (1,0) [0|7] "SED"  GENERIC
 SG_ VRM_ComAutostore_St : 36|2@0+ (1,0) [0|3] "SED"  GENERIC
 SG_ VRM_ComBand_St : 34|3@0+ (1,0) [0|7] "SED"  GENERIC
 SG_ VRM_TMCVoice : 15|2@0+ (1,0) [0|3] "SED"  GENERIC
 SG_ VRM_NewSMS : 13|2@0+ (1,0) [0|3] "SED"  HUD_ADV,IPC
 SG_ VRM_ComRSEDisplay_St : 11|2@0+ (1,0) [0|3] "SED"  GENERIC
 SG_ VRM_ComPICode_St : 8|17@0+ (1,0) [0|65535] "unitless"  GENERIC
 SG_ VRM_ComPresetCall_St : 7|3@0+ (1,0) [0|7] "SED"  GENERIC
 SG_ VRM_ComTape_St : 4|3@0+ (1,0) [0|7] "SED"  GENERIC
 SG_ VRM_ComShuffleDiscs_St : 1|2@0+ (1,0) [0|3] "SED"  GENERIC
 SG_ VRM_ComDolbyNR_St : 55|2@0+ (1,0) [0|3] "SED"  GENERIC
 SG_ VRM_ComSourceSelect_St : 53|3@0+ (1,0) [0|7] "SED"  GENERIC
 SG_ VRM_ComStFreq_St : 50|11@0+ (1,0) [0|1557] "unitless"  GENERIC
 SG_ VRM_ComRouteStrategy_St : 47|4@0+ (1,0) [0|15] "SED"  GENERIC

BO_ 721 VRM_Send_Signals_1: 8 APIM
 SG_ VRM_BTDefaultPhone_St : 63|4@0+ (1,0) [0|15] "SED"  IPC
 SG_ VRM_DetourUnit_st : 59|2@0+ (1,0) [0|3] "SED"  GENERIC
 SG_ VRM_Zoom_Option_St : 57|2@0+ (1,0) [0|3] "SED"  GENERIC
 SG_ VRM_ComBTDTMFTone_St : 55|4@0+ (1,0) [0|15] "SED"  GENERIC
 SG_ VRM_SuggestedRoute_St : 51|2@0+ (1,0) [0|3] "SED"  GENERIC
 SG_ VRM_ComDelWaypoint_St : 49|2@0+ (1,0) [0|3] "SED"  GENERIC
 SG_ VRM_ComSelectDisc_St : 47|3@0+ (1,0) [0|7] "SED"  GENERIC
 SG_ VRM_ComTelService_St : 44|3@0+ (1,0) [0|7] "SED"  GENERIC
 SG_ VRM_ComDestHome_St : 41|2@0+ (1,0) [0|3] "SED"  GENERIC
 SG_ VRM_ComSelectTrack_St : 39|7@0+ (1,0) [0|100] "unitless"  GENERIC
 SG_ VRM_ComShowNavInfo_St : 31|3@0+ (1,0) [0|7] "SED"  GENERIC
 SG_ VRM_VoiceRecStatus_St : 28|3@0+ (1,0) [0|7] "SED"  IPC
 SG_ VRM_ComSelTrackSource_St : 25|2@0+ (1,0) [0|3] "SED"  GENERIC
 SG_ VRM_ComDetour_St : 23|4@0+ (1,0) [0|15] "SED"  GENERIC
 SG_ VRM_ComDisplay_St : 19|3@0+ (1,0) [0|7] "SED"  GENERIC
 SG_ VRM_ComDynamicGuidande_St : 15|2@0+ (1,0) [0|3] "SED"  GENERIC
 SG_ VRM_ComZoom_St : 12|5@0+ (1,0) [0|31] "SED"  GENERIC
 SG_ VRM_ComCallControl_St : 7|3@0+ (1,0) [0|7] "SED"  GENERIC
 SG_ VRM_ComGuidance_St : 4|3@0+ (1,0) [0|7] "SED"  GENERIC
 SG_ VRM_ComTrafficInfDsp_St : 1|2@0+ (1,0) [0|3] "SED"  GENERIC

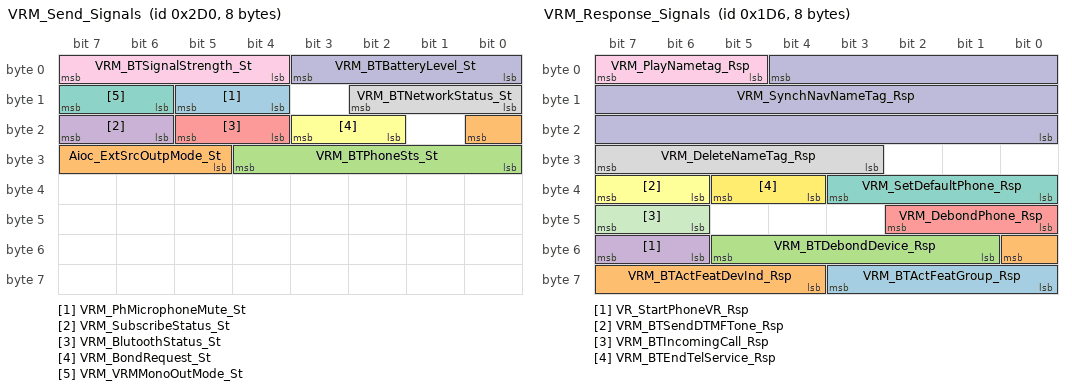
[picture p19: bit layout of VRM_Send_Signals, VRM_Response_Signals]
BO_ 720 VRM_Send_Signals: 8 APIM
 SG_ VRM_PhMicrophoneMute_St : 13|2@0+ (1,0) [0|3] "SED"  IPC
 SG_ Aioc_ExtSrcOutpMode_St : 16|4@0+ (1,0) [0|15] "SED"  GENERIC
 SG_ VRM_BTPhoneSts_St : 28|5@0+ (1,0) [0|31] "SED"  IPC,GWM,HUD_ADV
 SG_ VRM_SubscribeStatus_St : 23|2@0+ (1,0) [0|3] "SED"  GENERIC
 SG_ VRM_BlutoothStatus_St : 21|2@0+ (1,0) [0|3] "SED"  IPC
 SG_ VRM_BondRequest_St : 19|2@0+ (1,0) [0|3] "SED"  GENERIC
 SG_ VRM_VRMMonoOutMode_St : 15|2@0+ (1,0) [0|3] "SED"  GENERIC
 SG_ VRM_BTNetworkStatus_St : 10|3@0+ (1,0) [0|7] "unitless"  IPC
 SG_ VRM_BTSignalStrength_St : 7|4@0+ (1,0) [0|15] "unitless"  IPC
 SG_ VRM_BTBatteryLevel_St : 3|4@0+ (1,0) [0|15] "unitless"  IPC

BO_ 470 VRM_Response_Signals: 8 APIM
 SG_ VRM_BTActFeatGroup_Rsp : 59|4@0+ (1,0) [0|15] "SED" Vector__XXX
 SG_ VRM_BTActFeatDevInd_Rsp : 48|5@0+ (1,0) [0|31] "SED" Vector__XXX
 SG_ VRM_BTDebondDevice_Rsp : 53|5@0+ (1,0) [0|31] "SED" Vector__XXX
 SG_ VR_StartPhoneVR_Rsp : 55|2@0+ (1,0) [0|3] "SED" Vector__XXX
 SG_ VRM_DebondPhone_Rsp : 42|3@0+ (1,0) [0|7] "SED" Vector__XXX
 SG_ VRM_BTSendDTMFTone_Rsp : 39|2@0+ (1,0) [0|3] "SED" Vector__XXX
 SG_ VRM_SetDefaultPhone_Rsp : 35|4@0+ (1,0) [0|15] "SED" Vector__XXX
 SG_ VRM_DeleteNameTag_Rsp : 31|5@0+ (1,0) [0|31] "SED" Vector__XXX
 SG_ VRM_PlayNametag_Rsp : 7|3@0+ (1,0) [0|7] "SED" Vector__XXX
 SG_ VRM_SynchNavNameTag_Rsp : 4|21@0+ (1,0) [0|2097151] "unitless" Vector__XXX
 SG_ VRM_BTIncomingCall_Rsp : 47|2@0+ (1,0) [0|3] "SED"  HUD_ADV,IPC
 SG_ VRM_BTEndTelService_Rsp : 37|2@0+ (1,0) [0|3] "SED"  HUD_ADV,IPC

BO_ 1978 TesterPhysicalResHUD_ADV: 8 HUD_ADV
 SG_ TesterPhysicalResHUD_ADV : 7|64@0+ (1,0) [0|1.84467E+019] "unitless"  TSTR

BO_ 1970 TesterPhysicalReqHUD_ADV: 8 TSTR
 SG_ TesterPhysicalReqHUD_ADV : 7|64@0+ (1,0) [0|1.84467E+019] "unitless"  HUD_ADV

BO_ 758 SDARS_Status_Msg_1: 8 ACM
 SG_ SDARS_OpMode_St : 5|3@0+ (1,0) [0|7] "SED"  APIM,IPC
 SG_ SDARS_SetCategory_St : 31|8@0+ (1,0) [0|255] "unitless"  APIM,IPC
 SG_ SDARS_GCI_Update_Prg_St : 23|8@0+ (1,0) [0|255] "unitless"  APIM,RACM_RCIM,IPC
 SG_ SDARS_Factory_Reset_St : 7|2@0+ (1,0) [0|3] "SED"  APIM,IPC

BO_TX_BU_ 413 : APIM_CISM,APIM;
BO_TX_BU_ 1020 : APIM_CISM,APIM;
BO_TX_BU_ 696 : APIM_CISM,APIM;
BO_TX_BU_ 391 : APIM_CISM,ACM;
BO_TX_BU_ 672 : GWM,FCIMB;
BO_TX_BU_ 766 : APIM_CISM,APIM;
BO_TX_BU_ 145 : APIM_CISM,APIM;
BO_TX_BU_ 598 : APIM_CISM,APIM;
BO_TX_BU_ 597 : APIM_CISM,ACM,APIM;
BO_TX_BU_ 736 : APIM_CISM,APIM;
BO_TX_BU_ 722 : APIM_CISM,APIM;
BO_TX_BU_ 721 : APIM_CISM,APIM;
BO_TX_BU_ 720 : APIM_CISM,APIM;
BO_TX_BU_ 470 : APIM_CISM,APIM;
BO_TX_BU_ 758 : APIM_CISM,APIM,ACM;
CM_ SG_ 413 LBS1_ParentID "Object. ListBrowser.ItemInf.Rq.ActiveListID
0x0000:Root
0xFFFF:Reserved";
CM_ SG_ 413 LBS1_ListID "Object. ListBrowser.ItemInf.Rq.ItemIndex
0x0000:BrowseActiveListID
0x0001:EntryIndex_1
0xFFFF:ParentOfActiveListID";
CM_ SG_ 413 LBS1_EntryIndex "Object. ListBrowser.ItemInf.Rq.ActiveListID
0x0000:Root
0xFFFF:Reserved";
CM_ BO_ 688 "TP message";
CM_ SG_ 696 APIM_TCUB_Word_Tx "Tx by HS3 APIM";
CM_ SG_ 1189 Running_Board_Stat "Update msg. $115 to Event @ INIT in CMDB v4.06, 5/27/05.";
CM_ SG_ 772 Memory_Feedback_Rqst "Updated to 1 bit for CGEA, Not backwards compatible";
CM_ SG_ 92 TrnGearMsgTxt2_D_Rq "Signal not transmitted on vehicles that do not have shift by wire.";
CM_ SG_ 92 TrnSbwSysHlth_D_Actl "Signal not transmitted on vehicles that do not have shift by wire.";
CM_ SG_ 92 TrnDtpCmd_D_Actl "Signal not transmitted on vehicles that do not have shift by wire.";
CM_ SG_ 92 TrnGearNtmAllow_B_Stat "Signal not transmitted on vehicles that do not have shift by wire.";
CM_ SG_ 92 TrnGearCmd_No_Cs "Signal not transmitted on vehicles that do not have shift by wire.";
CM_ SG_ 92 TrnValidGear_D_Cnfm "Signal not transmitted on vehicles that do not have shift by wire.";
CM_ SG_ 92 TrnNtrlTowCmd_D_Actl "Signal not transmitted on vehicles that do not have shift by wire.";
CM_ SG_ 92 TrnGearCmd_Pc_ActlPt "Signal not transmitted on vehicles that do not have shift by wire.";
CM_ SG_ 92 TrnGear_D_RqPt "Signal not transmitted on vehicles that do not have shift by wire.";
CM_ SG_ 92 TrnCmdState_B_Actl "Signal not transmitted on vehicles that do not have shift by wire.";
CM_ SG_ 92 TrnCmdCnt_B_Actl "Signal not transmitted on vehicles that do not have shift by wire.";
CM_ SG_ 92 PrkBrkActv_D_RqTrnGear "Signal not transmitted on vehicles that do not have shift by wire.";
CM_ SG_ 92 TrnGearMsgTxt_D_Rq "Signal not transmitted on vehicles that do not have shift by wire.";
CM_ SG_ 92 TrnGearCmd_No_Cnt "Signal not transmitted on vehicles that do not have shift by wire.";
CM_ SG_ 357 BpedDrvAppl_D_Actl "CCMGenSigTimeoutTime=1000";
CM_ SG_ 357 CcStat_D_Actl "ABSGenSigTimeoutTime=1000";
CM_ SG_ 357 AccStopMde_D_Rq "ABSGenSigTimeoutTime=1000";
CM_ BO_ 560 "MHT (U611/625) the HPCM will Rx 0x230 from the PCM_HEV
Powersplit FWD HEV’s (Cx482/3 430) the HPCM will Tx 0x230";
CM_ SG_ 560 SelDrvMdeSwtch_D_Stat3 "ECM_HEV does not support or Transmit signal.";
CM_ SG_ 560 GearLvrPosActl_No_Cs "Signal not transmitted on Gas & HEV variants. MHT(U611/625) HPCM Rx 0x230 from PCM_HEV. Powersplit FWD HEV’s(Cx482/3 430) HPCM Tx 0x230.";
CM_ SG_ 560 GearLvrPosActl_No_Cnt "Signal not transmitted on Gas & HEV variants. MHT(U611/625) HPCM Rx 0x230 from PCM_HEV. Powersplit FWD HEV’s(Cx482/3 430) HPCM Tx 0x230.";
CM_ SG_ 560 TrnGbox_Rt_Actl "Signal not transmitted on Gas & HEV variants. MHT(U611/625) HPCM Rx 0x230 from PCM_HEV. Powersplit FWD HEV’s(Cx482/3 430) HPCM Tx 0x230.";
CM_ SG_ 560 TrnSrvcRqd_B_Rq "Signal not transmitted on Diesel & HEV variants. MHT(U611/625) HPCM Rx 0x230 from PCM_HEV. Powersplit FWD HEV’s(Cx482/3 430) HPCM Tx 0x230.";
CM_ SG_ 560 TrnCnvtClu_D_Actl "Signal not transmitted on Gas & HEV variants. MHT(U611/625) HPCM Rx 0x230 from PCM_HEV. Powersplit FWD HEV’s(Cx482/3 430) HPCM Tx 0x230.";
CM_ SG_ 560 TrnShifActv_B_Actl "Signal not transmitted on HEV variants. MHT(U611/625) HPCM Rx 0x230 from PCM_HEV. Powersplit FWD HEV’s(Cx482/3 430) HPCM Tx 0x230.";
CM_ SG_ 560 GboxOil_Te_Actl "Signal not transmitted on HEV variants. MHT(U611/625) HPCM Rx 0x230 from PCM_HEV. Powersplit FWD HEV’s(Cx482/3 430) HPCM Tx 0x230.";
CM_ SG_ 391 ACU_CtrlChimeChan_Rq "Object BodyInterface.StdChimeIF.ControlChimeChannel.Rq";
CM_ SG_ 672 SetVolume "$0: -30Steps
$1: -29Steps
$2: -28Steps
$1D: -1Step
$1E: NotPressed_Inactive
$1F: +1Step
$20: +2Steps
$21: +3Steps
$3C: +30Steps";
CM_ SG_ 672 SetPointVolume "Method: EFP_Button_Press
0x0:Inactive
$0: Inactive
$1: No_Volume
$2: Volume_Step1
$3: Vol_Step2
$1F: Vol_Step30";
CM_ SG_ 672 Coding_BtnID_D "Object InputControlInterface ICI ButtonCoding_D
Object InputControlInterface ICI ButtonID_D";
CM_ SG_ 672 Coding_BtnID_C "Object InputControlInterface.ICI ButtonCoding_C
Object InputControlInterface.ICI ButtonID_C";
CM_ SG_ 672 Coding_BtnID_B "Object InputControlInterface ICI ButtonCoding_B
Object InputControlInterface.ICI ButtonID_B";
CM_ SG_ 672 Coding_BtnID_A "Object InputControlInterface ICI ButtonCoding_A
Object InputControlInterface.ICI ButtonID A";
CM_ SG_ 672 BtnID_D "Object InputControlInterface ICI ButtonID_D... 0xFF: Inactive";
CM_ SG_ 672 BtnID_C "Object InputControlInterface ICI ButtonID_D... 0xFF: Inactive";
CM_ SG_ 672 BtnID_B "Object InputControlInterface ICI ButtonID_D... 0xFF: Inactive";
CM_ SG_ 672 BtnID_A "Object InputControlInterface ICI ButtonID_D... 0xFF: Inactive";
CM_ SG_ 672 BCP_Audible_Beep_Rq "Object.AlertMethod.BCP_Audible_Beep";
CM_ SG_ 1200 BrkTot_Tq_RqDrv "DCR 1836 to update Tx from GWM to EP100ms rejected due MPS6 TCM requires BrkTot_Tq_RqDrv at 20ms (bshu1).";
CM_ SG_ 840 FohT2Friday_T_Rq "Signal not transmitted on vehicles that do not have the Fuel operated heater feature.";
CM_ SG_ 840 FohT1Friday_T_Rq "Signal not transmitted on vehicles that do not have the Fuel operated heater feature.";
CM_ SG_ 840 FohT2Wednesday_T_Rq "Signal not transmitted on vehicles that do not have the Fuel operated heater feature.";
CM_ SG_ 840 FohT2Tuesday_T_Rq "Signal not transmitted on vehicles that do not have the Fuel operated heater feature.";
CM_ SG_ 840 FohT2Thursday_T_Rq "Signal not transmitted on vehicles that do not have the Fuel operated heater feature.";
CM_ SG_ 840 FohT2Sunday_T_Rq "Signal not transmitted on vehicles that do not have the Fuel operated heater feature.";
CM_ SG_ 840 FohT2Saturday_T_Rq "Signal not transmitted on vehicles that do not have the Fuel operated heater feature.";
CM_ SG_ 840 FohT2Monday_T_Rq "Signal not transmitted on vehicles that do not have the Fuel operated heater feature.";
CM_ SG_ 840 FohT1Wednesday_T_Rq "Signal not transmitted on vehicles that do not have the Fuel operated heater feature.";
CM_ SG_ 840 FohT1Tuesday_T_Rq "Signal not transmitted on vehicles that do not have the Fuel operated heater feature.";
CM_ SG_ 840 FohT1Thursday_T_Rq "Signal not transmitted on vehicles that do not have the Fuel operated heater feature.";
CM_ SG_ 840 FohT1Sunday_T_Rq "Signal not transmitted on vehicles that do not have the Fuel operated heater feature.";
CM_ SG_ 840 FohT1Saturday_T_Rq "Signal not transmitted on vehicles that do not have the Fuel operated heater feature.";
CM_ SG_ 840 FohT1Monday_T_Rq "Signal not transmitted on vehicles that do not have the Fuel operated heater feature.";
CM_ SG_ 494 HEC_TUPresetArea_Rq "Object Tuner.GetTUPresetInfo.PresetArea

$5: Get AMAST (MW) Preset Data
$6: Get AM (LW) Preset Data";
CM_ SG_ 494 Mc_SetCurrPreset2_Rq "Object Tuner.SetCurrentPreset2

$1-$1E: Preset 1 to 30
$0: Inactive
";
CM_ SG_ 494 HEC_TUNbrOfPresets_Rq "Object Tuner.GetTUPresetInfo.NumberOfPresets

$1-$1E: Preset 1 to 30";
CM_ SG_ 494 HEC_SetCurrTUBand_Rq "Object Tuner.SetCurrTUBand
$5: AM (LLN, HLN: MW)
$6: AM AST (LLN, HLN: LW)";
CM_ SG_ 494 HEC_TUStartIndex2_Rq "Object Tuner.GetTUPresetInfo.StartIndex2

$1-$FF: Preset 1 to 255";
CM_ SG_ 498 HEC_ARReqstrPriority_Rq "Object Audio Management Audio Client.AudioRequest.Requester Priority";
CM_ SG_ 498 HEC_AROperationType_Rq "Object Audio Management Audio Client.AudioRequest.Operation Type";
CM_ SG_ 498 HEC_ARReqstrSystem_Rq "Object Audio Management Audio Client.AudioRequest.Requester System";
CM_ SG_ 498 HEC_ARAudioSource_Rq "Object Audio Management Audio Client.AudioRequest.Requested Audio Source";
CM_ BO_ 145 "MFD Shall not send this message when configured as a slave

Method: Clock Modes";
CM_ SG_ 145 MFD_Year "Used by MFD to distribute actual Master Clock data to the Slave";
CM_ SG_ 145 MFD_Second "Used by MFD to distribute actual Master Clock data to the Slave";
CM_ SG_ 145 MFD_Month "Used by MFD to distribute actual Master Clock data to the Slave";
CM_ SG_ 145 MFD_Minute "Used by MFD to distribute actual Master Clock data to the Slave";
CM_ SG_ 145 MFD_Hour "Used by MFD to distribute actual Master Clock data to the Slave";
CM_ SG_ 145 MFD_Day "Used by MFD to distribute actual Master Clock data to the Slave";
CM_ SG_ 607 RDRV_RSE_WORD_Rx "MM ISO 15765-2 Message Catalogue RSE - RDRV";
CM_ SG_ 598 CONMP_RSE_WORD_Tx "MM ISO 15765-2 Message Catalogue MediaPlayerServer – MediaPlayerClient3";
CM_ SG_ 606 CONMP_RSE_WORD_Rx "MM ISO 15765-2 Message Catalogue MediaPlayerClient3 - MediaPlayerServer";
CM_ SG_ 597 AUDIO_RSE_WORD_Tx "MM ISO 15765-2 Message Catalogue AUDIO - RSE";
CM_ SG_ 605 AUDIO_RSE_WORD_Rx "MM ISO 15765-2 Message Catalogue RSE - AUDIO";
CM_ BO_ 827 "MSGDCR 000176 HUD_ADV requested EP 60ms.   ";
CM_ SG_ 545 SurndSndUpmix2_D_Stat "Object:Surround_Sound_Upmix2_St";
CM_ SG_ 545 SndImmrsnLvl_D_Stat "ImmersionLevel_D_St";
CM_ SG_ 545 DSP_Sur_Sound_st "Method DSP_Sur_Sound_Upmix.St";
CM_ SG_ 545 DSP_MyKeyVolLimitUp_St "Method MykeyvolumeIsLimited";
CM_ SG_ 545 DSP_MyKeyVolLim_St "Method MykeyvolumeIsLimited";
CM_ SG_ 545 DSP_BeltminderAudio_St "Object.MyKey.BeltminderAudioIsMuted";
CM_ SG_ 545 DSP_Audio_Volume_Up_St "Object.VolumeControl.DSP_Audio_Vol_updated
";
CM_ SG_ 545 DSP_Audio_Vol_Level_St "Object.VolumeControl.DSP_Audio_Vol_Level.St

0x0 No Volume
0x1 Vol_Step1
0x2 Vol_Step2
0x3 Vol_Step3
Cont.
0x1E Vol_Step30";
CM_ SG_ 545 AudioOccMde_D_Stat "Object: Occupancy_Mode.St";
CM_ SG_ 674 RACM_SetVolume "Object CAN Button Strategy.BCP_Button_Press.SetVolume";
CM_ SG_ 674 RACM_Coding_BtnID_D "Object InputControlInterface ICI ButtonCoding_D
Object InputControlInterface ICI ButtonID_D";
CM_ SG_ 674 RACM_Coding_BtnID_C "Object InputControlInterface.ICI ButtonCoding_C
Object InputControlInterface.ICI ButtonID_C";
CM_ SG_ 674 RACM_Coding_BtnID_B "Object InputControlInterface ICI ButtonCoding_B
Object InputControlInterface.ICI ButtonID_B";
CM_ SG_ 674 RACM_Coding_BtnID_A "Object InputControlInterface ICI ButtonCoding_A
Object InputControlInterface.ICI ButtonID A";
CM_ SG_ 674 RACM_BtnID_D "Object InputControlInterface ICI ButtonID_D... 0xFF: Inactive";
CM_ SG_ 674 RACM_BtnID_C "Object InputControlInterface ICI ButtonID_D... 0xFF: Inactive";
CM_ SG_ 674 RACM_BtnID_B "Object InputControlInterface ICI ButtonID_D... 0xFF: Inactive";
CM_ SG_ 674 RACM_BtnID_A "Object InputControlInterface ICI ButtonID_D... 0xFF: Inactive";
CM_ SG_ 674 RearAudioCtlLck_D_Stat "RACLockout_St";
CM_ BO_ 74 "Reserve eCallNotification message";
CM_ SG_ 736 TextMessage_Rsp "Object.BTPhoneServer.TextMessage.Rsp.ResponseCode";
CM_ SG_ 736 VRM_IncCallOption_St "Object Bluetooth Phone.IncCallOption";
CM_ SG_ 736 VRM_PhonesSts_Rsp "Object Bluetooth Phone

Bit 0:  0: invalid, 1: valid
Bit 1: 
0:  Phone on index 1 not  connectable.
1: Phone on index 1 connectable.
.......
Bit 6: 
0:  Phone on index 6 not  connectable.
1: Phone on index 6 connectable.";
CM_ SG_ 736 VRM_CallDuration_St "Object Bluetooth Phone.CallDuration";
CM_ SG_ 736 BTInCallOptions_St "Object.BTPhoneServer.BTInCallOptions.Rsp.Result";
CM_ SG_ 722 VRM_ComShuffleTrack_St "Object Voice Recogniser.ComShuffleTrack";
CM_ SG_ 722 VRM_ComCompression_St "Object Voice Recogniser.ComCompression";
CM_ SG_ 722 VRM_ComStFreqMode_St "Object Voice Recogniser.ComFrequency(Parameter1)
Object Voice Recogniser.ComStation";
CM_ SG_ 722 VRM_ComAutostore_St "Object Voice Recogniser.ComAutostore";
CM_ SG_ 722 VRM_ComBand_St "Object Voice Recogniser.ComBand";
CM_ SG_ 722 VRM_TMCVoice "Object Voice Recogniser.TMC Voice";
CM_ SG_ 722 VRM_NewSMS "Object Bluetooth Phone";
CM_ SG_ 722 VRM_ComRSEDisplay_St "Object Voice Recogniser.ComRSEDisplay
NOT USED";
CM_ SG_ 722 VRM_ComPICode_St "Object Voice Recogniser.ComStation(PI Code)
(Parameter1)

16 bit hex coded PI Code";
CM_ SG_ 722 VRM_ComPresetCall_St "Object Voice Recogniser.ComPresetCall
NOT USED";
CM_ SG_ 722 VRM_ComTape_St "Object Voice Recogniser.ComTape
NOT USED";
CM_ SG_ 722 VRM_ComShuffleDiscs_St "Object Voice Recogniser.ComShuffleDiscs
NOT USED";
CM_ SG_ 722 VRM_ComDolbyNR_St "Object Voice Recogniser.ComDolbyNr
NOT USED";
CM_ SG_ 722 VRM_ComSourceSelect_St "Object Voice Recogniser.ComSourceSelect";
CM_ SG_ 722 VRM_ComStFreq_St "Object Voice Recogniser.ComFrequency(Parameter2)
Object Voice Recogniser.ComStation(Parameter2)

AM: Freq = 153+ Offset kHz. Offset 0..1557
FM: Freq = 76+ Offset*0.05 MHz. Offset 0..640
Selected tuned band determine frequency (kHz or MHz).
";
CM_ SG_ 722 VRM_ComRouteStrategy_St "Object Voice Recogniser.ComRouteStrategy";
CM_ SG_ 721 VRM_BTDefaultPhone_St "Object Voice Recogniser.BTDefaultPhone";
CM_ SG_ 721 VRM_DetourUnit_st "Object Voice Recogniser.DetourUnit";
CM_ SG_ 721 VRM_Zoom_Option_St "Object Voice Recogniser.ComZoom";
CM_ SG_ 721 VRM_ComBTDTMFTone_St "Object Voice Recogniser.ComBTDTMFTone";
CM_ SG_ 721 VRM_SuggestedRoute_St "Object Voice Recogniser.ComSuggestedRoute
NOT USED";
CM_ SG_ 721 VRM_ComDelWaypoint_St "Object Voice Recogniser.ComDelWaypoint";
CM_ SG_ 721 VRM_ComSelectDisc_St "Object Voice Recogniser.ComSelectDisc";
CM_ SG_ 721 VRM_ComTelService_St "Object Voice Recogniser.ComTelematicsService
NOT USED";
CM_ SG_ 721 VRM_ComDestHome_St "Object Voice Recogniser.ComDestHome";
CM_ SG_ 721 VRM_ComSelectTrack_St "Object Voice Recogniser.ComSelectTrack

$01: Command has not been issued";
CM_ SG_ 721 VRM_ComShowNavInfo_St "Object Voice Recogniser.ComShowNavInfo";
CM_ SG_ 721 VRM_VoiceRecStatus_St "Object VoiceRecognizer.VoiceRecStatus";
CM_ SG_ 721 VRM_ComSelTrackSource_St "Object Voice Recogniser.ComSelectTrack, parameter Source";
CM_ SG_ 721 VRM_ComDetour_St "Object Voice Recogniser.ComDetour";
CM_ SG_ 721 VRM_ComDisplay_St "Object Voice Recogniser.ComDisplay";
CM_ SG_ 721 VRM_ComDynamicGuidande_St "Object Voice Recogniser.DynamicRouteGuidance";
CM_ SG_ 721 VRM_ComZoom_St "Object Voice Recogniser.ComZoom";
CM_ SG_ 721 VRM_ComCallControl_St "Object Voice Recogniser.ComCallControl
NOT USED";
CM_ SG_ 721 VRM_ComGuidance_St "Object Voice Recogniser.ComGuidance";
CM_ SG_ 721 VRM_ComTrafficInfDsp_St "Object Voice Recogniser.ComTrafficInformation";
CM_ SG_ 720 VRM_PhMicrophoneMute_St "Object Bluetooth Phone.PhMicrophoneMute";
CM_ SG_ 720 Aioc_ExtSrcOutpMode_St "Object Audio Management Audio Switch.BVCOutputMode";
CM_ SG_ 720 VRM_BTPhoneSts_St "Object Bluetooth Phone.BTPhoneSts";
CM_ SG_ 720 VRM_SubscribeStatus_St "Object Bluetooth Phone";
CM_ SG_ 720 VRM_BlutoothStatus_St "Object Bluetooth Phone (Spelled as BluetoothStatus in OS)";
CM_ SG_ 720 VRM_BondRequest_St "Object Bluetooth Phone";
CM_ SG_ 720 VRM_VRMMonoOutMode_St "Object VRMAudioIOController.VRMMonoOutMode";
CM_ SG_ 720 VRM_BTNetworkStatus_St "Object Bluetooth Phone.BTNetworkStatus";
CM_ SG_ 720 VRM_BTSignalStrength_St "Object Bluetooth Phone.BTSignalStrength";
CM_ SG_ 720 VRM_BTBatteryLevel_St "Object Bluetooth Phone.BTBatteryLevel";
CM_ SG_ 470 VRM_BTActFeatGroup_Rsp "Object BT Device.BTActiveFeature.Group";
CM_ SG_ 470 VRM_BTActFeatDevInd_Rsp "Object BT Device.BTActiveFeature.BTDeviceIndex";
CM_ SG_ 470 VRM_BTDebondDevice_Rsp "Object BT Device.BTDebondDevice";
CM_ SG_ 470 VR_StartPhoneVR_Rsp "Object Bluetooth Phone.StartPhoneVR";
CM_ SG_ 470 VRM_DebondPhone_Rsp "Object Bluetooth Phone.DebondPhone";
CM_ SG_ 470 VRM_BTSendDTMFTone_Rsp "Object Bluetooth Phone.BTSendDTMFTone";
CM_ SG_ 470 VRM_SetDefaultPhone_Rsp "Object Bluetooth Phone.SetDefaultPhone";
CM_ SG_ 470 VRM_DeleteNameTag_Rsp "Object Voice Recogniser.DeleteNameTag

$00: Inactive
$01: Nametag Ref 1
...
$14: Nametag Ref 20
$15: Reserved
...
$1D: reserved
$1E: All Nametags
$1F: Unkown Nametag";
CM_ SG_ 470 VRM_PlayNametag_Rsp "Object Voice Recogniser.PlayNameTag";
CM_ SG_ 470 VRM_SynchNavNameTag_Rsp "Object Voice Recogniser.SynchronizeNavNameTag

Bit 0: 0: invalid 1: valid
Bit 1: 0: Ref1 no NameTag; 1: Ref1 NameTag
Bit 2: 0: Ref2 no NameTag; 1: Ref2 NameTag
..
Bit 20: 0: Ref20 no NameTag; 1: Ref20 NameTag";
CM_ SG_ 758 SDARS_OpMode_St "Object Tuner.SDARS Tuner.OperationMode";
CM_ SG_ 758 SDARS_SetCategory_St "Object.ExternalPersonalization.SDARS_SetCategory.St.Category
0x00: All
0x01: Category1
0x02: Category2
....
0xF9: Category249
0xFA: Reserved
....
0xFE: Reserved
0xFF: Invalid 
";
CM_ SG_ 758 SDARS_GCI_Update_Prg_St "Object Tuner.SDARS Tuner.GCIUpdateProgress
0-100%";
CM_ SG_ 758 SDARS_Factory_Reset_St "Object Tuner.SDARS Tuner.FactoryReset";
BA_DEF_ BO_  "FrameRouting" STRING ;
BA_DEF_ BO_  "NetworkInitialization" ENUM  "No","Yes";
BA_DEF_ BO_  "GenMsgStartDelayTime" INT 0 10000;
BA_DEF_ BO_  "GenMsgNrOfRepetition" INT 0 100;
BA_DEF_ BO_  "GenMsgDelayTime" INT 0 1000;
BA_DEF_ BO_  "GenMsgCycleTime" INT 0 100000;
BA_DEF_ BO_  "GenMsgSendType" ENUM  "FixedPeriodic","Event","EnabledPeriodic","NotUsed","NotUsed","EventPeriodic","NotUsed","NotUsed","NoMsgSendType";
BA_DEF_ SG_  "U_V710_MY2023_Tx" ENUM  "No","Yes";
BA_DEF_ SG_  "U_P708_MY2023_Tx" ENUM  "No","Yes";
BA_DEF_ SG_  "U_V713AV_MY2022_Tx" ENUM  "No","Yes";
BA_DEF_ SG_  "U_V713N_MY2022_Tx" ENUM  "No","Yes";
BA_DEF_ SG_  "ECGUsedTxSignal" ENUM  "No","Yes";
BA_DEF_ SG_  "U_V710_MY2023_Rx" ENUM  "No","Yes";
BA_DEF_ SG_  "U_P708_MY2023_Rx" ENUM  "No","Yes";
BA_DEF_ SG_  "U_V713AV_MY2022_Rx" ENUM  "No","Yes";
BA_DEF_ SG_  "U_V713N_MY2022_Rx" ENUM  "No","Yes";
BA_DEF_ SG_  "ECGUsedRxSignal" ENUM  "No","Yes";
BA_DEF_ SG_  "UsedOnPgmDBC" ENUM  "No","Yes";
BA_DEF_ SG_  "ContentDependant" ENUM  "No","Yes";
BA_DEF_ SG_  "GenSigStartValue" HEX 0 268435455;
BA_DEF_ SG_  "MetaData" ENUM  "No","Yes";
BA_DEF_ SG_  "WakeupSignal" ENUM  "No","Yes";
BA_DEF_ SG_  "GenSigInactiveValue" INT 0 100000;
BA_DEF_ SG_  "GenSigSendType" ENUM  "Cyclic","OnWrite","vector_leerstring","OnChange","vector_leerstring","IfActive","vector_leerstring","NoSigSendType";
BA_DEF_ BO_  "TpTxIndex" INT 0 536870911;
BA_DEF_ BO_  "OvtpPushApplication" ENUM  "FALSE","TRUE";
BA_DEF_ BO_  "SCP_FreshnessValueLength" INT 0 512;
BA_DEF_ BO_  "SCP_DataId" INT 0 17663;
BA_DEF_ BO_  "SCP_FreshnessValueTxLength" INT 0 512;
BA_DEF_ BO_  "SCP_AuthInfoTxLength" INT 0 512;
BA_DEF_ BO_  "SC_Message" ENUM  "No","Yes";
BA_DEF_ BO_  "GenMsgRoutingTimeoutTime" INT 0 5000;
BA_DEF_ BO_  "MessageGateway" ENUM  "No","Yes";
BA_DEF_ BO_  "NmAsrMessage" ENUM  "No","Yes";
BA_DEF_ BO_  "DiagState" ENUM  "No","Yes";
BA_DEF_ BO_  "DiagRequest" ENUM  "No","Yes";
BA_DEF_ BO_  "DiagResponse" ENUM  "No","Yes";
BA_DEF_ BO_  "GenMsgILSupport" ENUM  "No","Yes";
BA_DEF_DEF_  "FrameRouting" "";
BA_DEF_DEF_  "NetworkInitialization" "Yes";
BA_DEF_DEF_  "GenMsgStartDelayTime" 0;
BA_DEF_DEF_  "GenMsgNrOfRepetition" 1;
BA_DEF_DEF_  "GenMsgDelayTime" 20;
BA_DEF_DEF_  "GenMsgCycleTime" 0;
BA_DEF_DEF_  "GenMsgSendType" "NoMsgSendType";
BA_DEF_DEF_  "U_V710_MY2023_Tx" "No";
BA_DEF_DEF_  "U_P708_MY2023_Tx" "No";
BA_DEF_DEF_  "U_V713AV_MY2022_Tx" "No";
BA_DEF_DEF_  "U_V713N_MY2022_Tx" "No";
BA_DEF_DEF_  "ECGUsedTxSignal" "No";
BA_DEF_DEF_  "U_V710_MY2023_Rx" "No";
BA_DEF_DEF_  "U_P708_MY2023_Rx" "No";
BA_DEF_DEF_  "U_V713AV_MY2022_Rx" "No";
BA_DEF_DEF_  "U_V713N_MY2022_Rx" "No";
BA_DEF_DEF_  "ECGUsedRxSignal" "No";
BA_DEF_DEF_  "UsedOnPgmDBC" "Yes";
BA_DEF_DEF_  "ContentDependant" "No";
BA_DEF_DEF_  "GenSigStartValue" 0;
BA_DEF_DEF_  "MetaData" "No";
BA_DEF_DEF_  "WakeupSignal" "No";
BA_DEF_DEF_  "GenSigInactiveValue" 0;
BA_DEF_DEF_  "GenSigSendType" "NoSigSendType";
BA_DEF_DEF_  "TpTxIndex" 0;
BA_DEF_DEF_  "OvtpPushApplication" "FALSE";
BA_DEF_DEF_  "SCP_FreshnessValueLength" 64;
BA_DEF_DEF_  "SCP_DataId" 0;
BA_DEF_DEF_  "SCP_FreshnessValueTxLength" 11;
BA_DEF_DEF_  "SCP_AuthInfoTxLength" 53;
BA_DEF_DEF_  "SC_Message" "No";
BA_DEF_DEF_  "GenMsgRoutingTimeoutTime" 0;
BA_DEF_DEF_  "MessageGateway" "No";
BA_DEF_DEF_  "NmAsrMessage" "No";
BA_DEF_DEF_  "DiagState" "No";
BA_DEF_DEF_  "DiagRequest" "No";
BA_DEF_DEF_  "DiagResponse" "No";
BA_DEF_DEF_  "GenMsgILSupport" "Yes";
BA_ "GenMsgSendType" BO_ 413 1;
BA_ "FrameRouting" BO_ 898 "HS2_CAN,0x382;";
BA_ "GenMsgCycleTime" BO_ 1020 1000;
BA_ "GenMsgSendType" BO_ 1020 5;
BA_ "GenMsgCycleTime" BO_ 1007 1000;
BA_ "GenMsgSendType" BO_ 1007 5;
BA_ "FrameRouting" BO_ 1217 "MS1_CAN,0x4C1;";
BA_ "FrameRouting" BO_ 1216 "MS1_CAN,0x4C0;";
BA_ "FrameRouting" BO_ 820 "FD1_CAN,0x334;FD3_CAN,0x334";
BA_ "FrameRouting" BO_ 1247 "FD1_CAN,0x4DF;";
BA_ "GenMsgCycleTime" BO_ 677 1000;
BA_ "GenMsgSendType" BO_ 677 5;
BA_ "FrameRouting" BO_ 582 "FD1_CAN,0x242;";
BA_ "FrameRouting" BO_ 1036 "HS2_CAN,0x40C;";
BA_ "FrameRouting" BO_ 1047 "FD1_CAN,0x417;FD3_CAN,0x417";
BA_ "FrameRouting" BO_ 688 "FD2_CAN,0x2B0;";
BA_ "TpTxIndex" BO_ 688 121;
BA_ "TpTxIndex" BO_ 696 121;
BA_ "FrameRouting" BO_ 1236 "FD1_CAN,0x4D4;FD3_CAN,0x4D4";
BA_ "FrameRouting" BO_ 1235 "FD1_CAN,0x4D3;FD3_CAN,0x4D3";
BA_ "FrameRouting" BO_ 841 "MS1_CAN,0x349;";
BA_ "FrameRouting" BO_ 1189 "MS1_CAN,0x4A5;";
BA_ "FrameRouting" BO_ 772 "MS1_CAN,0x304;";
BA_ "FrameRouting" BO_ 1054 "FD1_CAN,0x41E;";
BA_ "FrameRouting" BO_ 572 "HS2_CAN,0x24B;";
BA_ "FrameRouting" BO_ 561 "FD1_CAN,0x231;";
BA_ "FrameRouting" BO_ 602 "FD1_CAN,0x25A;";
BA_ "FrameRouting" BO_ 92 "FD1_CAN,0x5C;";
BA_ "FrameRouting" BO_ 1156 "FD1_CAN,0x36D;";
BA_ "FrameRouting" BO_ 357 "FD1_CAN,0x165;";
BA_ "GenMsgRoutingTimeoutTime" BO_ 357 60;
BA_ "FrameRouting" BO_ 1100 "FD1_CAN,0x44C;";
BA_ "FrameRouting" BO_ 1152 "FD1_CAN,0x480;";
BA_ "NetworkInitialization" BO_ 2612224064 0;
BA_ "GenMsgDelayTime" BO_ 2612224064 0;
BA_ "GenMsgSendType" BO_ 2612224064 1;
BA_ "TpTxIndex" BO_ 2612224064 464584920;
BA_ "OvtpPushApplication" BO_ 2612224064 1;
BA_ "NetworkInitialization" BO_ 2612068568 0;
BA_ "GenMsgDelayTime" BO_ 2612068568 0;
BA_ "GenMsgSendType" BO_ 2612068568 1;
BA_ "TpTxIndex" BO_ 2612068568 464584920;
BA_ "OvtpPushApplication" BO_ 2612068568 1;
BA_ "NetworkInitialization" BO_ 2611175488 0;
BA_ "GenMsgDelayTime" BO_ 2611175488 0;
BA_ "GenMsgSendType" BO_ 2611175488 1;
BA_ "TpTxIndex" BO_ 2611175488 463536344;
BA_ "NetworkInitialization" BO_ 2611019992 0;
BA_ "GenMsgDelayTime" BO_ 2611019992 0;
BA_ "GenMsgSendType" BO_ 2611019992 1;
BA_ "TpTxIndex" BO_ 2611019992 463536344;
BA_ "NetworkInitialization" BO_ 2610126912 0;
BA_ "GenMsgDelayTime" BO_ 2610126912 0;
BA_ "GenMsgSendType" BO_ 2610126912 1;
BA_ "TpTxIndex" BO_ 2610126912 462487768;
BA_ "NetworkInitialization" BO_ 2609971416 0;
BA_ "GenMsgDelayTime" BO_ 2609971416 0;
BA_ "GenMsgSendType" BO_ 2609971416 1;
BA_ "TpTxIndex" BO_ 2609971416 462487768;
BA_ "FrameRouting" BO_ 652 "FD2_CAN,0x28C;";
BA_ "FrameRouting" BO_ 560 "FD1_CAN,0x230;";
BA_ "FrameRouting" BO_ 1153 "HS2_CAN,0x481;";
BA_ "FrameRouting" BO_ 930 "FD3_CAN,0x3A2;";
BA_ "FrameRouting" BO_ 929 "FD3_CAN,0x3A1;";
BA_ "FrameRouting" BO_ 788 "FD1_CAN,0x314;";
BA_ "GenMsgSendType" BO_ 391 1;
BA_ "FrameRouting" BO_ 670 "FD3_CAN,0x29E;";
BA_ "FrameRouting" BO_ 672 "MS1_CAN,0x2A0;";
BA_ "GenMsgStartDelayTime" BO_ 672 150;
BA_ "GenMsgCycleTime" BO_ 672 1000;
BA_ "GenMsgSendType" BO_ 672 5;
BA_ "FrameRouting" BO_ 1205 "FD1_CAN,0x4B5;";
BA_ "FrameRouting" BO_ 1200 "FD1_CAN,0x4B0;";
BA_ "TpTxIndex" BO_ 593 58;
BA_ "NetworkInitialization" BO_ 601 0;
BA_ "TpTxIndex" BO_ 601 58;
BA_ "FrameRouting" BO_ 1018 "MS2_CAN,0x3FA;";
BA_ "FrameRouting" BO_ 1238 "FD1_CAN,0x4D6;FD3_CAN,0x4D6";
BA_ "GenMsgCycleTime" BO_ 766 1000;
BA_ "GenMsgSendType" BO_ 766 5;
BA_ "GenMsgCycleTime" BO_ 840 1000;
BA_ "GenMsgSendType" BO_ 840 5;
BA_ "NetworkInitialization" BO_ 494 0;
BA_ "GenMsgSendType" BO_ 494 1;
BA_ "NetworkInitialization" BO_ 714 0;
BA_ "TpTxIndex" BO_ 714 28;
BA_ "NetworkInitialization" BO_ 498 0;
BA_ "GenMsgSendType" BO_ 498 1;
BA_ "GenMsgSendType" BO_ 145 1;
BA_ "TpTxIndex" BO_ 607 48;
BA_ "TpTxIndex" BO_ 598 47;
BA_ "TpTxIndex" BO_ 606 47;
BA_ "TpTxIndex" BO_ 597 46;
BA_ "TpTxIndex" BO_ 605 46;
BA_ "FrameRouting" BO_ 827 "FD3_CAN,0x33B;";
BA_ "FrameRouting" BO_ 1043 "FD1_CAN,0x413;";
BA_ "FrameRouting" BO_ 876 "MS1_CAN,0x36C;";
BA_ "FrameRouting" BO_ 875 "MS1_CAN,0x36B;";
BA_ "GenMsgCycleTime" BO_ 545 1000;
BA_ "GenMsgSendType" BO_ 545 5;
BA_ "FrameRouting" BO_ 1092 "HS2_CAN,0x444;";
BA_ "GenMsgCycleTime" BO_ 936 1000;
BA_ "GenMsgSendType" BO_ 936 5;
BA_ "GenMsgRoutingTimeoutTime" BO_ 936 60;
BA_ "GenMsgStartDelayTime" BO_ 674 150;
BA_ "GenMsgDelayTime" BO_ 674 10;
BA_ "GenMsgCycleTime" BO_ 674 1000;
BA_ "GenMsgSendType" BO_ 674 5;
BA_ "GenMsgCycleTime" BO_ 75 1000;
BA_ "GenMsgSendType" BO_ 75 5;
BA_ "GenMsgRoutingTimeoutTime" BO_ 75 300;
BA_ "GenMsgCycleTime" BO_ 74 1000;
BA_ "GenMsgSendType" BO_ 74 5;
BA_ "GenMsgRoutingTimeoutTime" BO_ 74 300;
BA_ "FrameRouting" BO_ 780 "MS2_CAN,0x30C;";
BA_ "FrameRouting" BO_ 779 "MS2_CAN,0x30B;";
BA_ "GenMsgCycleTime" BO_ 783 1000;
BA_ "GenMsgSendType" BO_ 783 5;
BA_ "FrameRouting" BO_ 638 "FD2_CAN,0x27E;";
BA_ "GenMsgCycleTime" BO_ 555 1000;
BA_ "GenMsgSendType" BO_ 555 5;
BA_ "FrameRouting" BO_ 124 "FD1_CAN,0x77;";
BA_ "GenMsgCycleTime" BO_ 736 1000;
BA_ "GenMsgSendType" BO_ 736 5;
BA_ "GenMsgCycleTime" BO_ 722 1000;
BA_ "GenMsgSendType" BO_ 722 5;
BA_ "GenMsgCycleTime" BO_ 721 1000;
BA_ "GenMsgSendType" BO_ 721 5;
BA_ "GenMsgCycleTime" BO_ 720 1000;
BA_ "GenMsgSendType" BO_ 720 5;
BA_ "GenMsgSendType" BO_ 470 1;
BA_ "NetworkInitialization" BO_ 1978 0;
BA_ "GenMsgDelayTime" BO_ 1978 0;
BA_ "GenMsgSendType" BO_ 1978 1;
BA_ "DiagResponse" BO_ 1978 1;
BA_ "GenMsgILSupport" BO_ 1978 0;
BA_ "NetworkInitialization" BO_ 1970 0;
BA_ "GenMsgDelayTime" BO_ 1970 0;
BA_ "GenMsgSendType" BO_ 1970 1;
BA_ "DiagRequest" BO_ 1970 1;
BA_ "GenMsgILSupport" BO_ 1970 0;
BA_ "GenMsgCycleTime" BO_ 758 1000;
BA_ "GenMsgSendType" BO_ 758 5;
BA_ "U_P708_MY2023_Rx" SG_ 413 LBS1_ParentID 1;
BA_ "U_P708_MY2023_Rx" SG_ 413 LBS1_ListStatus 1;
BA_ "GenSigSendType" SG_ 413 LBS1_ListStatus 3;
BA_ "U_P708_MY2023_Rx" SG_ 413 LBS1_ListServer 1;
BA_ "U_P708_MY2023_Rx" SG_ 413 LBS1_ListID 1;
BA_ "U_P708_MY2023_Rx" SG_ 413 LBS1_EntryIndex 1;
BA_ "GenSigStartValue" SG_ 898 VedsPrmDirOfF_An_Ltchd 90;
BA_ "GenSigStartValue" SG_ 898 VedsRoll_An_Ltchd 4096;
BA_ "U_V710_MY2023_Rx" SG_ 898 SecondRowBcklPsngrMid 1;
BA_ "U_P708_MY2023_Rx" SG_ 898 SecondRowBcklPsngrMid 1;
BA_ "GenSigStartValue" SG_ 898 SecondRowBcklPsngrMid 3;
BA_ "U_V710_MY2023_Rx" SG_ 898 SecondRowBuckleDrvMid 1;
BA_ "U_P708_MY2023_Rx" SG_ 898 SecondRowBuckleDrvMid 1;
BA_ "GenSigStartValue" SG_ 898 SecondRowBuckleDrvMid 3;
BA_ "U_V710_MY2023_Rx" SG_ 898 FourthRowBucklePsngr 1;
BA_ "U_P708_MY2023_Rx" SG_ 898 FourthRowBucklePsngr 1;
BA_ "GenSigStartValue" SG_ 898 FourthRowBucklePsngr 3;
BA_ "U_V710_MY2023_Rx" SG_ 898 FourthRowBuckleMid 1;
BA_ "U_P708_MY2023_Rx" SG_ 898 FourthRowBuckleMid 1;
BA_ "GenSigStartValue" SG_ 898 FourthRowBuckleMid 3;
BA_ "U_V710_MY2023_Rx" SG_ 898 FourthRowBuckleDriver 1;
BA_ "U_P708_MY2023_Rx" SG_ 898 FourthRowBuckleDriver 1;
BA_ "GenSigStartValue" SG_ 898 FourthRowBuckleDriver 3;
BA_ "U_V710_MY2023_Rx" SG_ 898 Row3PsngrPrsnc_D_Actl 1;
BA_ "U_P708_MY2023_Rx" SG_ 898 Row3PsngrPrsnc_D_Actl 1;
BA_ "GenSigStartValue" SG_ 898 Row3PsngrPrsnc_D_Actl 3;
BA_ "U_V710_MY2023_Rx" SG_ 898 Row3MidPrsnc_D_Actl 1;
BA_ "U_P708_MY2023_Rx" SG_ 898 Row3MidPrsnc_D_Actl 1;
BA_ "GenSigStartValue" SG_ 898 Row3MidPrsnc_D_Actl 3;
BA_ "U_V710_MY2023_Rx" SG_ 898 Row3DrvPrsnc_D_Actl 1;
BA_ "U_P708_MY2023_Rx" SG_ 898 Row3DrvPrsnc_D_Actl 1;
BA_ "GenSigStartValue" SG_ 898 Row3DrvPrsnc_D_Actl 3;
BA_ "U_V710_MY2023_Rx" SG_ 898 Row2PsngrPrsnc_D_Actl 1;
BA_ "U_P708_MY2023_Rx" SG_ 898 Row2PsngrPrsnc_D_Actl 1;
BA_ "GenSigStartValue" SG_ 898 Row2PsngrPrsnc_D_Actl 3;
BA_ "U_V710_MY2023_Rx" SG_ 898 Row2MidPrsnc_D_Actl 1;
BA_ "U_P708_MY2023_Rx" SG_ 898 Row2MidPrsnc_D_Actl 1;
BA_ "GenSigStartValue" SG_ 898 Row2MidPrsnc_D_Actl 3;
BA_ "U_V710_MY2023_Rx" SG_ 898 Row2DrvPrsnc_D_Actl 1;
BA_ "U_P708_MY2023_Rx" SG_ 898 Row2DrvPrsnc_D_Actl 1;
BA_ "GenSigStartValue" SG_ 898 Row2DrvPrsnc_D_Actl 3;
BA_ "U_V710_MY2023_Rx" SG_ 1020 CtrStkPersIndex2_D_Actl 1;
BA_ "U_P708_MY2023_Rx" SG_ 1020 CtrStkPersIndex2_D_Actl 1;
BA_ "GenSigSendType" SG_ 1020 CtrStkPersIndex2_D_Actl 3;
BA_ "GenSigStartValue" SG_ 1020 CtrStkPersIndex2_D_Actl 4;
BA_ "U_V710_MY2023_Rx" SG_ 1020 CtrStkFeat2ConfigActl 1;
BA_ "GenSigSendType" SG_ 1020 CtrStkFeat2ConfigActl 3;
BA_ "U_V710_MY2023_Rx" SG_ 1020 CtrStkFeat2NoActl 1;
BA_ "U_P708_MY2023_Rx" SG_ 1020 CtrStkFeat2NoActl 1;
BA_ "GenSigSendType" SG_ 1020 CtrStkFeat2NoActl 3;
BA_ "U_V710_MY2023_Rx" SG_ 1020 CtrStkDsplyOp2_D_Rq 1;
BA_ "U_P708_MY2023_Rx" SG_ 1020 CtrStkDsplyOp2_D_Rq 1;
BA_ "GenSigSendType" SG_ 1020 CtrStkDsplyOp2_D_Rq 3;
BA_ "U_V710_MY2023_Tx" SG_ 1007 PersIndexIpc2_D_Actl 1;
BA_ "U_P708_MY2023_Tx" SG_ 1007 PersIndexIpc2_D_Actl 1;
BA_ "U_V713N_MY2022_Tx" SG_ 1007 PersIndexIpc2_D_Actl 1;
BA_ "GenSigSendType" SG_ 1007 PersIndexIpc2_D_Actl 3;
BA_ "GenSigStartValue" SG_ 1007 PersIndexIpc2_D_Actl 4;
BA_ "U_V710_MY2023_Tx" SG_ 1007 FeatNoIpc2Actl 1;
BA_ "U_P708_MY2023_Tx" SG_ 1007 FeatNoIpc2Actl 1;
BA_ "U_V713N_MY2022_Tx" SG_ 1007 FeatNoIpc2Actl 1;
BA_ "GenSigSendType" SG_ 1007 FeatNoIpc2Actl 3;
BA_ "U_V710_MY2023_Tx" SG_ 1007 FeatConfigIpc2Actl 1;
BA_ "U_P708_MY2023_Tx" SG_ 1007 FeatConfigIpc2Actl 1;
BA_ "U_V713N_MY2022_Tx" SG_ 1007 FeatConfigIpc2Actl 1;
BA_ "GenSigSendType" SG_ 1007 FeatConfigIpc2Actl 3;
BA_ "U_V710_MY2023_Rx" SG_ 1217 SldrrStat_B_Actl 1;
BA_ "U_P708_MY2023_Rx" SG_ 1217 SldrrStat_B_Actl 1;
BA_ "U_V710_MY2023_Rx" SG_ 1217 SldrrMsgTxt_D2_Rq 1;
BA_ "U_P708_MY2023_Rx" SG_ 1217 SldrrMsgTxt_D2_Rq 1;
BA_ "U_V713AV_MY2022_Rx" SG_ 1217 SldrrMsgTxt_D2_Rq 1;
BA_ "U_V713N_MY2022_Rx" SG_ 1217 SldrrMsgTxt_D2_Rq 1;
BA_ "WakeupSignal" SG_ 1217 SldrrMsgTxt_D2_Rq 1;
BA_ "U_V710_MY2023_Rx" SG_ 1217 SldrrChime_D_Rq 1;
BA_ "U_P708_MY2023_Rx" SG_ 1217 SldrrChime_D_Rq 1;
BA_ "U_V713AV_MY2022_Rx" SG_ 1217 SldrrChime_D_Rq 1;
BA_ "U_V713N_MY2022_Rx" SG_ 1217 SldrrChime_D_Rq 1;
BA_ "WakeupSignal" SG_ 1217 SldrrChime_D_Rq 1;
BA_ "MetaData" SG_ 1217 SldrrUnlckRollCd_No_Cnt 1;
BA_ "MetaData" SG_ 1217 SldrrUnlck_No_Cnt 1;
BA_ "WakeupSignal" SG_ 1217 SldrrUnlck_No_Cnt 1;
BA_ "MetaData" SG_ 1217 SldrrChildLck_No_Cnt 1;
BA_ "WakeupSignal" SG_ 1217 SldrrChildLck_No_Cnt 1;
BA_ "WakeupSignal" SG_ 1217 Sldrr_D_Stat 1;
BA_ "U_V710_MY2023_Rx" SG_ 1216 SldrlStat_B_Actl 1;
BA_ "U_P708_MY2023_Rx" SG_ 1216 SldrlStat_B_Actl 1;
BA_ "U_V710_MY2023_Rx" SG_ 1216 SldrlMsgTxt_D2_Rq 1;
BA_ "U_P708_MY2023_Rx" SG_ 1216 SldrlMsgTxt_D2_Rq 1;
BA_ "U_V713AV_MY2022_Rx" SG_ 1216 SldrlMsgTxt_D2_Rq 1;
BA_ "U_V713N_MY2022_Rx" SG_ 1216 SldrlMsgTxt_D2_Rq 1;
BA_ "WakeupSignal" SG_ 1216 SldrlMsgTxt_D2_Rq 1;
BA_ "U_V710_MY2023_Rx" SG_ 1216 SldrlChime_D_Rq 1;
BA_ "U_P708_MY2023_Rx" SG_ 1216 SldrlChime_D_Rq 1;
BA_ "U_V713AV_MY2022_Rx" SG_ 1216 SldrlChime_D_Rq 1;
BA_ "U_V713N_MY2022_Rx" SG_ 1216 SldrlChime_D_Rq 1;
BA_ "WakeupSignal" SG_ 1216 SldrlChime_D_Rq 1;
BA_ "MetaData" SG_ 1216 SldrlUnlckRollCd_No_Cnt 1;
BA_ "MetaData" SG_ 1216 SldrlUnlck_No_Cnt 1;
BA_ "WakeupSignal" SG_ 1216 SldrlUnlck_No_Cnt 1;
BA_ "MetaData" SG_ 1216 SldrlChildLck_No_Cnt 1;
BA_ "WakeupSignal" SG_ 1216 SldrlChildLck_No_Cnt 1;
BA_ "WakeupSignal" SG_ 1216 Sldrl_D_Stat 1;
BA_ "U_V710_MY2023_Rx" SG_ 820 HeadLghtHiOn_B_StatHcm 1;
BA_ "U_P708_MY2023_Rx" SG_ 820 HeadLghtHiOn_B_StatHcm 1;
BA_ "U_V713AV_MY2022_Rx" SG_ 820 HeadLghtHiOn_B_StatHcm 1;
BA_ "U_V713N_MY2022_Rx" SG_ 820 HeadLghtHiOn_B_StatHcm 1;
BA_ "U_V710_MY2023_Rx" SG_ 820 Adaptive_Hdlmp_Fault 1;
BA_ "U_P708_MY2023_Rx" SG_ 820 Adaptive_Hdlmp_Fault 1;
BA_ "U_V713AV_MY2022_Rx" SG_ 820 Adaptive_Hdlmp_Fault 1;
BA_ "U_V713N_MY2022_Rx" SG_ 820 Adaptive_Hdlmp_Fault 1;
BA_ "MetaData" SG_ 1247 StopLampBRqTrlrAft_No_Cs 1;
BA_ "MetaData" SG_ 1247 StopLampBRqTrlrAft_No_Cnt 1;
BA_ "GenSigSendType" SG_ 677 SeatFnPsgr_D_Rq3 3;
BA_ "GenSigSendType" SG_ 677 SeatFnDrv_D_Rq3 3;
BA_ "GenSigSendType" SG_ 677 SeatMasgPsngrRr_D_Rq2 3;
BA_ "GenSigSendType" SG_ 677 SeatMasgDrvRr_D_Rq2 3;
BA_ "GenSigSendType" SG_ 677 SeatFnChngPsgr2_D_Rq3 3;
BA_ "GenSigSendType" SG_ 677 SeatFnChngDrv2_D_Rq3 3;
BA_ "U_V710_MY2023_Rx" SG_ 582 PtLatchActv_B_RqBcm 1;
BA_ "U_P708_MY2023_Rx" SG_ 582 PtLatchActv_B_RqBcm 1;
BA_ "U_V713N_MY2022_Rx" SG_ 582 PtLatchActv_B_RqBcm 1;
BA_ "WakeupSignal" SG_ 582 ReFuelSwtchStat_D_Actl 1;
BA_ "GenSigStartValue" SG_ 582 BattULo_U_Actl 255;
BA_ "U_P708_MY2023_Rx" SG_ 582 PrkLckCtl_B_Enbl 1;
BA_ "U_V713N_MY2022_Rx" SG_ 582 PrkLckCtl_B_Enbl 1;
BA_ "U_V710_MY2023_Rx" SG_ 582 PrkLckCtlMsgTxt_D_Rq 1;
BA_ "U_P708_MY2023_Rx" SG_ 582 PrkLckCtlMsgTxt_D_Rq 1;
BA_ "U_V713N_MY2022_Rx" SG_ 582 PrkLckCtlMsgTxt_D_Rq 1;
BA_ "WakeupSignal" SG_ 582 PrkLckCtlMsgTxt_D_Rq 1;
BA_ "U_V710_MY2023_Rx" SG_ 582 PrkLckCtlAvail_T_Stat 1;
BA_ "U_P708_MY2023_Rx" SG_ 582 PrkLckCtlAvail_T_Stat 1;
BA_ "U_V713N_MY2022_Rx" SG_ 582 PrkLckCtlAvail_T_Stat 1;
BA_ "WakeupSignal" SG_ 582 PrkLckCtlAvail_T_Stat 1;
BA_ "U_V710_MY2023_Rx" SG_ 582 PrkLckCtlUnlck_D_Stat 1;
BA_ "U_P708_MY2023_Rx" SG_ 582 PrkLckCtlUnlck_D_Stat 1;
BA_ "U_V713N_MY2022_Rx" SG_ 582 PrkLckCtlUnlck_D_Stat 1;
BA_ "U_P708_MY2023_Rx" SG_ 582 PrkLckCtlTow_B_Enbl 1;
BA_ "U_V713N_MY2022_Rx" SG_ 582 PrkLckCtlTow_B_Enbl 1;
BA_ "U_P708_MY2023_Rx" SG_ 582 EngOff_T_Actl 1;
BA_ "U_V713N_MY2022_Rx" SG_ 582 EngOff_T_Actl 1;
BA_ "GenSigStartValue" SG_ 582 BattULo_I_Actl 16383;
BA_ "U_V710_MY2023_Rx" SG_ 1036 PdstrnAlrt_B_Falt 1;
BA_ "U_P708_MY2023_Rx" SG_ 1036 PdstrnAlrt_B_Falt 1;
BA_ "U_V713N_MY2022_Rx" SG_ 1036 PdstrnAlrt_B_Falt 1;
BA_ "U_P708_MY2023_Rx" SG_ 1047 TrlrAidTrlrId_No_Rq 1;
BA_ "U_V713AV_MY2022_Rx" SG_ 1047 TrlrAidTrlrId_No_Rq 1;
BA_ "U_V713N_MY2022_Rx" SG_ 1047 TrlrAidTrlrId_No_Rq 1;
BA_ "U_P708_MY2023_Rx" SG_ 1047 TrlrAidEnbl_D2_Stat 1;
BA_ "U_V713AV_MY2022_Rx" SG_ 1047 TrlrAidEnbl_D2_Stat 1;
BA_ "U_V713N_MY2022_Rx" SG_ 1047 TrlrAidEnbl_D2_Stat 1;
BA_ "U_V710_MY2023_Rx" SG_ 1047 TrlrAidMsgTxt_D2_Rq 1;
BA_ "U_P708_MY2023_Rx" SG_ 1047 TrlrAidMsgTxt_D2_Rq 1;
BA_ "U_V713AV_MY2022_Rx" SG_ 1047 TrlrAidMsgTxt_D2_Rq 1;
BA_ "U_V713N_MY2022_Rx" SG_ 1047 TrlrAidMsgTxt_D2_Rq 1;
BA_ "U_P708_MY2023_Rx" SG_ 1047 EsaOn_B_Stat 1;
BA_ "U_V713N_MY2022_Rx" SG_ 1047 EsaOn_B_Stat 1;
BA_ "GenSigStartValue" SG_ 1047 EsaOn_B_Stat 1;
BA_ "GenSigStartValue" SG_ 1236 ApaSlotRearY_L_Actl 32;
BA_ "GenSigStartValue" SG_ 1235 ApaSlotFrontY_L_Actl 32;
BA_ "U_V710_MY2023_Rx" SG_ 841 FohStrtDateDay_No_Stat 1;
BA_ "U_V710_MY2023_Rx" SG_ 841 FohStrtDateYr_No_Stat 1;
BA_ "U_P708_MY2023_Rx" SG_ 1189 PwStepMsgTxt_D_Rq 1;
BA_ "U_V713N_MY2022_Rx" SG_ 1189 PwStepMsgTxt_D_Rq 1;
BA_ "U_V710_MY2023_Rx" SG_ 1189 Running_Board_Stat 1;
BA_ "U_P708_MY2023_Rx" SG_ 1189 Running_Board_Stat 1;
BA_ "U_V713N_MY2022_Rx" SG_ 1189 Running_Board_Stat 1;
BA_ "WakeupSignal" SG_ 772 SeatScrnDrvOn_B_Rq 1;
BA_ "U_P708_MY2023_Rx" SG_ 772 PwRnngBoardT_D_Stat 1;
BA_ "U_V713N_MY2022_Rx" SG_ 772 PwRnngBoardT_D_Stat 1;
BA_ "U_P708_MY2023_Rx" SG_ 772 PwRnngBoardSwtch_D_Stat 1;
BA_ "U_V713N_MY2022_Rx" SG_ 772 PwRnngBoardSwtch_D_Stat 1;
BA_ "U_P708_MY2023_Rx" SG_ 772 SeatSlprPosMsgTxt_B_Rq 1;
BA_ "U_V713N_MY2022_Rx" SG_ 772 SeatSlprPosMsgTxt_B_Rq 1;
BA_ "U_V710_MY2023_Rx" SG_ 772 MemDrvDeny_B_Stat 1;
BA_ "U_P708_MY2023_Rx" SG_ 772 MemDrvDeny_B_Stat 1;
BA_ "U_V713N_MY2022_Rx" SG_ 772 MemDrvDeny_B_Stat 1;
BA_ "U_V710_MY2023_Rx" SG_ 772 Memory_Feedback_Rqst 1;
BA_ "U_P708_MY2023_Rx" SG_ 772 Memory_Feedback_Rqst 1;
BA_ "U_V713N_MY2022_Rx" SG_ 772 Memory_Feedback_Rqst 1;
BA_ "WakeupSignal" SG_ 772 Memory_Feedback_Rqst 1;
BA_ "WakeupSignal" SG_ 772 Easy_Entry_Rqst 1;
BA_ "U_P708_MY2023_Rx" SG_ 772 Memory_Cmd 1;
BA_ "U_V713N_MY2022_Rx" SG_ 772 Memory_Cmd 1;
BA_ "WakeupSignal" SG_ 772 Memory_Cmd 1;
BA_ "WakeupSignal" SG_ 772 Cancel_Auto_Movement 1;
BA_ "U_P708_MY2023_Rx" SG_ 1054 TrailCtl_D_Stat 1;
BA_ "U_P708_MY2023_Rx" SG_ 1054 TrailCtlMsgTxt_D_Rq 1;
BA_ "U_V710_MY2023_Rx" SG_ 1054 BrkPadMsgTxt_D_Rq 1;
BA_ "U_P708_MY2023_Rx" SG_ 1054 BrkPadMsgTxt_D_Rq 1;
BA_ "U_V713N_MY2022_Rx" SG_ 1054 BrkPadMsgTxt_D_Rq 1;
BA_ "U_V710_MY2023_Rx" SG_ 1054 DrvSlipCtlOffLamp_D_Rq 1;
BA_ "U_P708_MY2023_Rx" SG_ 1054 DrvSlipCtlOffLamp_D_Rq 1;
BA_ "U_V713N_MY2022_Rx" SG_ 1054 DrvSlipCtlOffLamp_D_Rq 1;
BA_ "U_V710_MY2023_Rx" SG_ 1054 DrvSlipCtlMdeMsg_D_Rq 1;
BA_ "U_P708_MY2023_Rx" SG_ 1054 DrvSlipCtlMdeMsg_D_Rq 1;
BA_ "U_V713N_MY2022_Rx" SG_ 1054 DrvSlipCtlMdeMsg_D_Rq 1;
BA_ "U_P708_MY2023_Rx" SG_ 1054 HdcOn_B_Ind 1;
BA_ "U_V713N_MY2022_Rx" SG_ 1054 HdcOn_B_Ind 1;
BA_ "U_V710_MY2023_Rx" SG_ 1054 AutoHoldMsgTxt_D_Rq 1;
BA_ "U_P708_MY2023_Rx" SG_ 1054 AutoHoldMsgTxt_D_Rq 1;
BA_ "U_V713N_MY2022_Rx" SG_ 1054 AutoHoldMsgTxt_D_Rq 1;
BA_ "GenSigStartValue" SG_ 1054 SelDrvMdeAwd_D_Rq 31;
BA_ "U_V710_MY2023_Rx" SG_ 1054 AutoHoldMde_D_Ind 1;
BA_ "U_P708_MY2023_Rx" SG_ 1054 AutoHoldMde_D_Ind 1;
BA_ "U_V713N_MY2022_Rx" SG_ 1054 AutoHoldMde_D_Ind 1;
BA_ "U_P708_MY2023_Rx" SG_ 1054 BrkMdeInhbt_B_RqDsply 1;
BA_ "U_V713N_MY2022_Rx" SG_ 1054 BrkMdeInhbt_B_RqDsply 1;
BA_ "WakeupSignal" SG_ 1054 BrkMdeInhbt_B_RqDsply 1;
BA_ "U_V713N_MY2022_Rx" SG_ 1054 BrkLineLck_D_Stat 1;
BA_ "GenSigStartValue" SG_ 1054 BrkLineLck_D_Stat 4;
BA_ "U_V713AV_MY2022_Rx" SG_ 1054 BrkDrvMde_D_Stat 1;
BA_ "U_P708_MY2023_Rx" SG_ 1054 BrkDrvMde_D_Stat 1;
BA_ "U_V713N_MY2022_Rx" SG_ 1054 BrkDrvMde_D_Stat 1;
BA_ "GenSigStartValue" SG_ 572 BattTracClnt_Te_Actl 254;
BA_ "GenSigStartValue" SG_ 572 BattTracClnt_Te_Rq 190;
BA_ "U_V710_MY2023_Rx" SG_ 572 BattTracWarnLamp_B_Rq 1;
BA_ "U_P708_MY2023_Rx" SG_ 572 BattTracWarnLamp_B_Rq 1;
BA_ "U_V713N_MY2022_Rx" SG_ 572 BattTracWarnLamp_B_Rq 1;
BA_ "U_V710_MY2023_Rx" SG_ 572 BattTracSrvcRqd_B_Rq 1;
BA_ "U_P708_MY2023_Rx" SG_ 572 BattTracSrvcRqd_B_Rq 1;
BA_ "U_V713N_MY2022_Rx" SG_ 572 BattTracSrvcRqd_B_Rq 1;
BA_ "GenSigStartValue" SG_ 572 BattTracSoc_Pc_MxPrtct 700;
BA_ "GenSigStartValue" SG_ 572 BattTracSoc_Pc_MnPrtct 30;
BA_ "GenSigStartValue" SG_ 572 BattTracSoc_Pc_LimLo 400;
BA_ "GenSigStartValue" SG_ 572 BattTracSoc_Pc_LimHi 600;
BA_ "U_V710_MY2023_Rx" SG_ 561 TrnMsgTxt2_D_Rq 1;
BA_ "U_P708_MY2023_Rx" SG_ 561 TrnMsgTxt2_D_Rq 1;
BA_ "U_V713AV_MY2022_Rx" SG_ 561 TrnMsgTxt2_D_Rq 1;
BA_ "U_V713N_MY2022_Rx" SG_ 561 TrnMsgTxt2_D_Rq 1;
BA_ "U_V710_MY2023_Rx" SG_ 561 TrnMsgTxt_D_Rq 1;
BA_ "U_P708_MY2023_Rx" SG_ 561 TrnMsgTxt_D_Rq 1;
BA_ "U_V713N_MY2022_Rx" SG_ 561 TrnMsgTxt_D_Rq 1;
BA_ "U_V710_MY2023_Rx" SG_ 602 HtrnWarnLamp_B_Dsply 1;
BA_ "U_V713N_MY2022_Rx" SG_ 602 HtrnWarnLamp_B_Dsply 1;
BA_ "U_V710_MY2023_Rx" SG_ 602 PwPckTqRdy_B_Dsply 1;
BA_ "U_V713N_MY2022_Rx" SG_ 602 PwPckTqRdy_B_Dsply 1;
BA_ "GenSigStartValue" SG_ 602 BattTracRsrvSoc_Pc_Rq 16382;
BA_ "U_V710_MY2023_Rx" SG_ 92 TrnGearMsgTxt2_D_Rq 1;
BA_ "U_P708_MY2023_Rx" SG_ 92 TrnGearMsgTxt2_D_Rq 1;
BA_ "ContentDependant" SG_ 92 TrnGearMsgTxt2_D_Rq 1;
BA_ "GenSigStartValue" SG_ 92 TrnLvrV_D_Rq 1;
BA_ "GenSigStartValue" SG_ 92 TrnSbwSysHlth_D_Actl 1;
BA_ "GenSigStartValue" SG_ 92 TrnDtpCmd_D_Actl 1;
BA_ "WakeupSignal" SG_ 92 TrnDtpCmd_D_Actl 1;
BA_ "U_V710_MY2023_Rx" SG_ 92 TrnGearNtmAllow_B_Stat 1;
BA_ "U_P708_MY2023_Rx" SG_ 92 TrnGearNtmAllow_B_Stat 1;
BA_ "U_V713N_MY2022_Rx" SG_ 92 TrnGearNtmAllow_B_Stat 1;
BA_ "MetaData" SG_ 92 TrnGearCmd_No_Cs 1;
BA_ "GenSigStartValue" SG_ 92 PrkBrkActv_D_RqTrnGear 1;
BA_ "U_V710_MY2023_Rx" SG_ 92 TrnGearMsgTxt_D_Rq 1;
BA_ "U_P708_MY2023_Rx" SG_ 92 TrnGearMsgTxt_D_Rq 1;
BA_ "U_V713N_MY2022_Rx" SG_ 92 TrnGearMsgTxt_D_Rq 1;
BA_ "MetaData" SG_ 92 TrnGearCmd_No_Cnt 1;
BA_ "GenSigStartValue" SG_ 1156 RngPerChrgAvg_L2_Dsply 8190;
BA_ "U_V713N_MY2022_Rx" SG_ 1156 RngImpctDrv_L_Dsply 1;
BA_ "U_V713N_MY2022_Rx" SG_ 1156 RngImpctClim_L_Dsply 1;
BA_ "U_V710_MY2023_Rx" SG_ 1156 VehElEffAvg_No_Dsply 1;
BA_ "U_V713N_MY2022_Rx" SG_ 1156 VehElEffAvg_No_Dsply 1;
BA_ "GenSigStartValue" SG_ 1156 VehElEffAvg_No_Dsply 126;
BA_ "GenSigStartValue" SG_ 357 BPedDrvAppl_D_Qf 1;
BA_ "MetaData" SG_ 357 BPedDrvAppl_D_Qf 1;
BA_ "MetaData" SG_ 357 BpedDrvAppl_No_Cs 1;
BA_ "MetaData" SG_ 357 BpedDrvAppl_No_Cnt 1;
BA_ "U_P708_MY2023_Rx" SG_ 357 BpedDrvAppl_D_Actl 1;
BA_ "U_V713N_MY2022_Rx" SG_ 357 BpedDrvAppl_D_Actl 1;
BA_ "GenSigStartValue" SG_ 357 BpedDrvAppl_D_Actl 1;
BA_ "U_V710_MY2023_Rx" SG_ 357 Veh_V_DsplyCcSet 1;
BA_ "U_P708_MY2023_Rx" SG_ 357 Veh_V_DsplyCcSet 1;
BA_ "U_V713N_MY2022_Rx" SG_ 357 Veh_V_DsplyCcSet 1;
BA_ "U_P708_MY2023_Rx" SG_ 357 CcStat_D_Actl 1;
BA_ "U_V713N_MY2022_Rx" SG_ 357 CcStat_D_Actl 1;
BA_ "U_P708_MY2023_Rx" SG_ 357 CcOvrrdActv_B_Actl 1;
BA_ "U_V713N_MY2022_Rx" SG_ 357 CcOvrrdActv_B_Actl 1;
BA_ "U_P708_MY2023_Rx" SG_ 1100 RearDiffLckLamp_D_Rq2 1;
BA_ "U_V713N_MY2022_Rx" SG_ 1100 RearDiffLckLamp_D_Rq2 1;
BA_ "U_P708_MY2023_Rx" SG_ 1100 RvltnMatchAllw_D_Stat 1;
BA_ "U_V713N_MY2022_Rx" SG_ 1100 RvltnMatchAllw_D_Stat 1;
BA_ "GenSigStartValue" SG_ 1100 WakeAlarm1_T_Rq 32767;
BA_ "WakeupSignal" SG_ 1100 WakeAlarm1_B_Typ 1;
BA_ "U_P708_MY2023_Rx" SG_ 1100 Veh_V_DsplyTrailCtlSet 1;
BA_ "U_P708_MY2023_Rx" SG_ 1100 AutoTowAllw_D_StatMnu 1;
BA_ "U_V713N_MY2022_Rx" SG_ 1100 AutoTowAllw_D_StatMnu 1;
BA_ "U_P708_MY2023_Rx" SG_ 1100 AutoTowActv_B_Stat 1;
BA_ "U_V713N_MY2022_Rx" SG_ 1100 AutoTowActv_B_Stat 1;
BA_ "GenSigStartValue" SG_ 1100 RearDiffSumpOil_Te_Est 254;
BA_ "GenSigStartValue" SG_ 1100 GrossTrainWeight_M_Est 254;
BA_ "U_P708_MY2023_Rx" SG_ 1100 SuspVlimMsgTxt_B_Rq 1;
BA_ "U_V713N_MY2022_Rx" SG_ 1100 SuspVlimMsgTxt_B_Rq 1;
BA_ "U_P708_MY2023_Rx" SG_ 1100 RearDiffLckMsg2_D_Rq 1;
BA_ "U_V713N_MY2022_Rx" SG_ 1100 RearDiffLckMsg2_D_Rq 1;
BA_ "U_V713AV_MY2022_Rx" SG_ 1100 EngExhMdeQuiet_D2_Stat 1;
BA_ "U_P708_MY2023_Rx" SG_ 1100 EngExhMdeQuiet_D2_Stat 1;
BA_ "U_V713N_MY2022_Rx" SG_ 1100 EngExhMdeQuiet_D2_Stat 1;
BA_ "U_V710_MY2023_Rx" SG_ 1152 StopStrtVThres_D_Stat 1;
BA_ "U_V713N_MY2022_Rx" SG_ 1152 StopStrtVThres_D_Stat 1;
BA_ "GenSigStartValue" SG_ 1152 StopStrtVThres_D_Stat 1;
BA_ "U_V710_MY2023_Rx" SG_ 1152 GrdAsstActv_B_Stat 1;
BA_ "U_V713N_MY2022_Rx" SG_ 1152 GrdAsstActv_B_Stat 1;
BA_ "U_V713N_MY2022_Rx" SG_ 1152 OnePdlDrv_D_Dsply 1;
BA_ "U_V713N_MY2022_Rx" SG_ 1152 OnePdlDrvLamp_B_Rq 1;
BA_ "GenSigStartValue" SG_ 1152 VehElEff_No_Avg 126;
BA_ "U_V710_MY2023_Tx" SG_ 2612224064 PARSEDPushWCMtoGWM_ECG 1;
BA_ "U_P708_MY2023_Tx" SG_ 2612224064 PARSEDPushWCMtoGWM_ECG 1;
BA_ "U_V713N_MY2022_Tx" SG_ 2612224064 PARSEDPushWCMtoGWM_ECG 1;
BA_ "U_V710_MY2023_Rx" SG_ 2612224064 PARSEDPushWCMtoGWM_ECG 1;
BA_ "U_P708_MY2023_Rx" SG_ 2612224064 PARSEDPushWCMtoGWM_ECG 1;
BA_ "U_V713AV_MY2022_Rx" SG_ 2612224064 PARSEDPushWCMtoGWM_ECG 1;
BA_ "U_V713N_MY2022_Rx" SG_ 2612224064 PARSEDPushWCMtoGWM_ECG 1;
BA_ "ECGUsedRxSignal" SG_ 2612224064 PARSEDPushWCMtoGWM_ECG 1;
BA_ "GenSigSendType" SG_ 2612224064 PARSEDPushWCMtoGWM_ECG 3;
BA_ "U_V710_MY2023_Tx" SG_ 2612068568 PARSEDPushFcGWM_ECGtoWCM 1;
BA_ "U_P708_MY2023_Tx" SG_ 2612068568 PARSEDPushFcGWM_ECGtoWCM 1;
BA_ "U_V713AV_MY2022_Tx" SG_ 2612068568 PARSEDPushFcGWM_ECGtoWCM 1;
BA_ "U_V713N_MY2022_Tx" SG_ 2612068568 PARSEDPushFcGWM_ECGtoWCM 1;
BA_ "ECGUsedTxSignal" SG_ 2612068568 PARSEDPushFcGWM_ECGtoWCM 1;
BA_ "U_V710_MY2023_Rx" SG_ 2612068568 PARSEDPushFcGWM_ECGtoWCM 1;
BA_ "U_P708_MY2023_Rx" SG_ 2612068568 PARSEDPushFcGWM_ECGtoWCM 1;
BA_ "GenSigSendType" SG_ 2612068568 PARSEDPushFcGWM_ECGtoWCM 3;
BA_ "U_V710_MY2023_Tx" SG_ 2611175488 PARSEDPhysWCMtoGWM_ECG 1;
BA_ "U_P708_MY2023_Tx" SG_ 2611175488 PARSEDPhysWCMtoGWM_ECG 1;
BA_ "U_V713N_MY2022_Tx" SG_ 2611175488 PARSEDPhysWCMtoGWM_ECG 1;
BA_ "U_V710_MY2023_Rx" SG_ 2611175488 PARSEDPhysWCMtoGWM_ECG 1;
BA_ "U_P708_MY2023_Rx" SG_ 2611175488 PARSEDPhysWCMtoGWM_ECG 1;
BA_ "U_V713AV_MY2022_Rx" SG_ 2611175488 PARSEDPhysWCMtoGWM_ECG 1;
BA_ "U_V713N_MY2022_Rx" SG_ 2611175488 PARSEDPhysWCMtoGWM_ECG 1;
BA_ "ECGUsedRxSignal" SG_ 2611175488 PARSEDPhysWCMtoGWM_ECG 1;
BA_ "GenSigSendType" SG_ 2611175488 PARSEDPhysWCMtoGWM_ECG 3;
BA_ "U_V710_MY2023_Tx" SG_ 2611019992 PARSEDPhysGWM_ECGtoWCM 1;
BA_ "U_P708_MY2023_Tx" SG_ 2611019992 PARSEDPhysGWM_ECGtoWCM 1;
BA_ "U_V713AV_MY2022_Tx" SG_ 2611019992 PARSEDPhysGWM_ECGtoWCM 1;
BA_ "U_V713N_MY2022_Tx" SG_ 2611019992 PARSEDPhysGWM_ECGtoWCM 1;
BA_ "ECGUsedTxSignal" SG_ 2611019992 PARSEDPhysGWM_ECGtoWCM 1;
BA_ "U_V710_MY2023_Rx" SG_ 2611019992 PARSEDPhysGWM_ECGtoWCM 1;
BA_ "U_P708_MY2023_Rx" SG_ 2611019992 PARSEDPhysGWM_ECGtoWCM 1;
BA_ "GenSigSendType" SG_ 2611019992 PARSEDPhysGWM_ECGtoWCM 3;
BA_ "U_V710_MY2023_Tx" SG_ 2610126912 OTAPhysWCMtoGWM_ECG 1;
BA_ "U_P708_MY2023_Tx" SG_ 2610126912 OTAPhysWCMtoGWM_ECG 1;
BA_ "U_V713N_MY2022_Tx" SG_ 2610126912 OTAPhysWCMtoGWM_ECG 1;
BA_ "U_V710_MY2023_Rx" SG_ 2610126912 OTAPhysWCMtoGWM_ECG 1;
BA_ "U_P708_MY2023_Rx" SG_ 2610126912 OTAPhysWCMtoGWM_ECG 1;
BA_ "U_V713AV_MY2022_Rx" SG_ 2610126912 OTAPhysWCMtoGWM_ECG 1;
BA_ "U_V713N_MY2022_Rx" SG_ 2610126912 OTAPhysWCMtoGWM_ECG 1;
BA_ "ECGUsedRxSignal" SG_ 2610126912 OTAPhysWCMtoGWM_ECG 1;
BA_ "GenSigSendType" SG_ 2610126912 OTAPhysWCMtoGWM_ECG 3;
BA_ "U_V710_MY2023_Tx" SG_ 2609971416 OTAPhysGWM_ECGtoWCM 1;
BA_ "U_P708_MY2023_Tx" SG_ 2609971416 OTAPhysGWM_ECGtoWCM 1;
BA_ "U_V713AV_MY2022_Tx" SG_ 2609971416 OTAPhysGWM_ECGtoWCM 1;
BA_ "U_V713N_MY2022_Tx" SG_ 2609971416 OTAPhysGWM_ECGtoWCM 1;
BA_ "ECGUsedTxSignal" SG_ 2609971416 OTAPhysGWM_ECGtoWCM 1;
BA_ "U_V710_MY2023_Rx" SG_ 2609971416 OTAPhysGWM_ECGtoWCM 1;
BA_ "U_P708_MY2023_Rx" SG_ 2609971416 OTAPhysGWM_ECGtoWCM 1;
BA_ "GenSigSendType" SG_ 2609971416 OTAPhysGWM_ECGtoWCM 3;
BA_ "U_V710_MY2023_Rx" SG_ 560 GearLvrPosActl_No_Cs 1;
BA_ "U_P708_MY2023_Rx" SG_ 560 GearLvrPosActl_No_Cs 1;
BA_ "MetaData" SG_ 560 GearLvrPosActl_No_Cs 1;
BA_ "U_V710_MY2023_Rx" SG_ 560 GearLvrPosActl_No_Cnt 1;
BA_ "U_P708_MY2023_Rx" SG_ 560 GearLvrPosActl_No_Cnt 1;
BA_ "MetaData" SG_ 560 GearLvrPosActl_No_Cnt 1;
BA_ "U_V710_MY2023_Rx" SG_ 560 TrnSrvcRqd_B_Rq 1;
BA_ "U_P708_MY2023_Rx" SG_ 560 TrnSrvcRqd_B_Rq 1;
BA_ "U_V713AV_MY2022_Rx" SG_ 560 GearLvrPos_D_Actl 1;
BA_ "U_V713N_MY2022_Rx" SG_ 560 GearLvrPos_D_Actl 1;
BA_ "U_V710_MY2023_Rx" SG_ 560 GearLvrPos_D_Actl 1;
BA_ "U_P708_MY2023_Rx" SG_ 560 GearLvrPos_D_Actl 1;
BA_ "GenSigStartValue" SG_ 560 GearLvrPos_D_Actl 14;
BA_ "U_P708_MY2023_Rx" SG_ 560 GboxOil_Te_Actl 1;
BA_ "GenSigStartValue" SG_ 560 GboxOil_Te_Actl 254;
BA_ "U_P708_MY2023_Rx" SG_ 930 BalrWndwRight_B_Stat 1;
BA_ "U_P708_MY2023_Rx" SG_ 930 BalrSnsRight_D_Falt 1;
BA_ "U_P708_MY2023_Rx" SG_ 930 BalrRight_D_Stat 1;
BA_ "GenSigStartValue" SG_ 930 BalrRight_D_Stat 2;
BA_ "U_P708_MY2023_Rx" SG_ 930 BalrMdeSelRight_B_Stat 1;
BA_ "U_P708_MY2023_Rx" SG_ 930 BalrMdeRight_D_Stat 1;
BA_ "GenSigStartValue" SG_ 930 BalrMdeRight_D_Stat 1;
BA_ "U_P708_MY2023_Rx" SG_ 930 BalrLckRight_B_Stat 1;
BA_ "U_P708_MY2023_Rx" SG_ 930 BalrChimeRight_D_Rq 1;
BA_ "U_V710_MY2023_Rx" SG_ 930 CamraRearOn_B_RqBalrr 1;
BA_ "U_V713AV_MY2022_Rx" SG_ 930 CamraRearOn_B_RqBalrr 1;
BA_ "U_V713N_MY2022_Rx" SG_ 930 CamraRearOn_B_RqBalrr 1;
BA_ "U_P708_MY2023_Rx" SG_ 929 BalrChimeLeft_D_Rq 1;
BA_ "U_P708_MY2023_Rx" SG_ 929 BalrLeft_D_Stat 1;
BA_ "GenSigStartValue" SG_ 929 BalrLeft_D_Stat 2;
BA_ "U_P708_MY2023_Rx" SG_ 929 BalrSnsLeft_D_Falt 1;
BA_ "U_P708_MY2023_Rx" SG_ 929 BalrMdeSelLeft_B_Stat 1;
BA_ "U_P708_MY2023_Rx" SG_ 929 BalrMdeLeft_D_Stat 1;
BA_ "GenSigStartValue" SG_ 929 BalrMdeLeft_D_Stat 1;
BA_ "U_P708_MY2023_Rx" SG_ 929 BalrLckLeft_B_Stat 1;
BA_ "U_V710_MY2023_Rx" SG_ 929 CamraRearOn_B_RqBalrl 1;
BA_ "U_V713N_MY2022_Rx" SG_ 929 CamraRearOn_B_RqBalrl 1;
BA_ "U_P708_MY2023_Rx" SG_ 929 BalrWndwLeft_B_Stat 1;
BA_ "GenSigStartValue" SG_ 788 EcoCochDecel2_Pc_Dsply 255;
BA_ "GenSigStartValue" SG_ 788 EcoCochDecel1_Pc_Dsply 255;
BA_ "GenSigStartValue" SG_ 788 EcoCochCrus2_Pc_Dsply 255;
BA_ "GenSigStartValue" SG_ 788 EcoCochCrus1_Pc_Dsply 255;
BA_ "GenSigStartValue" SG_ 788 EcoCochATrip2_Pc_Dsply 255;
BA_ "GenSigStartValue" SG_ 788 EcoCochATrip1_Pc_Dsply 255;
BA_ "U_P708_MY2023_Tx" SG_ 391 ACU_CtrlChimeChan_Rq 1;
BA_ "U_V713AV_MY2022_Tx" SG_ 391 ACU_CtrlChimeChan_Rq 1;
BA_ "U_V713N_MY2022_Tx" SG_ 391 ACU_CtrlChimeChan_Rq 1;
BA_ "GenSigSendType" SG_ 391 ACU_CtrlChimeChan_Rq 3;
BA_ "U_P708_MY2023_Rx" SG_ 670 DrHandleOuterRl_D_Stat 1;
BA_ "U_P708_MY2023_Rx" SG_ 670 DrHandleOuterFl_D_Stat 1;
BA_ "ECGUsedRxSignal" SG_ 672 SetVolume 1;
BA_ "U_V710_MY2023_Rx" SG_ 672 SetVolume 1;
BA_ "U_P708_MY2023_Rx" SG_ 672 SetVolume 1;
BA_ "U_V713AV_MY2022_Rx" SG_ 672 SetVolume 1;
BA_ "U_V713N_MY2022_Rx" SG_ 672 SetVolume 1;
BA_ "GenSigSendType" SG_ 672 SetVolume 3;
BA_ "GenSigStartValue" SG_ 672 SetVolume 30;
BA_ "WakeupSignal" SG_ 672 SetVolume 1;
BA_ "ECGUsedRxSignal" SG_ 672 SetPointVolume 1;
BA_ "U_V710_MY2023_Rx" SG_ 672 SetPointVolume 1;
BA_ "U_P708_MY2023_Rx" SG_ 672 SetPointVolume 1;
BA_ "U_V713AV_MY2022_Rx" SG_ 672 SetPointVolume 1;
BA_ "U_V713N_MY2022_Rx" SG_ 672 SetPointVolume 1;
BA_ "GenSigSendType" SG_ 672 SetPointVolume 3;
BA_ "WakeupSignal" SG_ 672 SetPointVolume 1;
BA_ "U_V710_MY2023_Rx" SG_ 672 Coding_BtnID_D 1;
BA_ "U_P708_MY2023_Rx" SG_ 672 Coding_BtnID_D 1;
BA_ "U_V713AV_MY2022_Rx" SG_ 672 Coding_BtnID_D 1;
BA_ "U_V713N_MY2022_Rx" SG_ 672 Coding_BtnID_D 1;
BA_ "GenSigSendType" SG_ 672 Coding_BtnID_D 3;
BA_ "WakeupSignal" SG_ 672 Coding_BtnID_D 1;
BA_ "U_V710_MY2023_Rx" SG_ 672 Coding_BtnID_C 1;
BA_ "U_P708_MY2023_Rx" SG_ 672 Coding_BtnID_C 1;
BA_ "U_V713AV_MY2022_Rx" SG_ 672 Coding_BtnID_C 1;
BA_ "U_V713N_MY2022_Rx" SG_ 672 Coding_BtnID_C 1;
BA_ "GenSigSendType" SG_ 672 Coding_BtnID_C 3;
BA_ "WakeupSignal" SG_ 672 Coding_BtnID_C 1;
BA_ "U_V710_MY2023_Rx" SG_ 672 Coding_BtnID_B 1;
BA_ "U_P708_MY2023_Rx" SG_ 672 Coding_BtnID_B 1;
BA_ "U_V713AV_MY2022_Rx" SG_ 672 Coding_BtnID_B 1;
BA_ "U_V713N_MY2022_Rx" SG_ 672 Coding_BtnID_B 1;
BA_ "GenSigSendType" SG_ 672 Coding_BtnID_B 3;
BA_ "WakeupSignal" SG_ 672 Coding_BtnID_B 1;
BA_ "U_V710_MY2023_Rx" SG_ 672 Coding_BtnID_A 1;
BA_ "U_P708_MY2023_Rx" SG_ 672 Coding_BtnID_A 1;
BA_ "U_V713AV_MY2022_Rx" SG_ 672 Coding_BtnID_A 1;
BA_ "U_V713N_MY2022_Rx" SG_ 672 Coding_BtnID_A 1;
BA_ "GenSigSendType" SG_ 672 Coding_BtnID_A 3;
BA_ "WakeupSignal" SG_ 672 Coding_BtnID_A 1;
BA_ "U_V710_MY2023_Rx" SG_ 672 BtnID_D 1;
BA_ "U_P708_MY2023_Rx" SG_ 672 BtnID_D 1;
BA_ "U_V713AV_MY2022_Rx" SG_ 672 BtnID_D 1;
BA_ "U_V713N_MY2022_Rx" SG_ 672 BtnID_D 1;
BA_ "GenSigStartValue" SG_ 672 BtnID_D 255;
BA_ "WakeupSignal" SG_ 672 BtnID_D 1;
BA_ "U_V710_MY2023_Rx" SG_ 672 BtnID_C 1;
BA_ "U_P708_MY2023_Rx" SG_ 672 BtnID_C 1;
BA_ "U_V713AV_MY2022_Rx" SG_ 672 BtnID_C 1;
BA_ "U_V713N_MY2022_Rx" SG_ 672 BtnID_C 1;
BA_ "GenSigStartValue" SG_ 672 BtnID_C 255;
BA_ "WakeupSignal" SG_ 672 BtnID_C 1;
BA_ "U_V710_MY2023_Rx" SG_ 672 BtnID_B 1;
BA_ "U_P708_MY2023_Rx" SG_ 672 BtnID_B 1;
BA_ "U_V713AV_MY2022_Rx" SG_ 672 BtnID_B 1;
BA_ "U_V713N_MY2022_Rx" SG_ 672 BtnID_B 1;
BA_ "GenSigStartValue" SG_ 672 BtnID_B 255;
BA_ "WakeupSignal" SG_ 672 BtnID_B 1;
BA_ "U_V710_MY2023_Rx" SG_ 672 BtnID_A 1;
BA_ "U_P708_MY2023_Rx" SG_ 672 BtnID_A 1;
BA_ "U_V713AV_MY2022_Rx" SG_ 672 BtnID_A 1;
BA_ "U_V713N_MY2022_Rx" SG_ 672 BtnID_A 1;
BA_ "GenSigStartValue" SG_ 672 BtnID_A 255;
BA_ "WakeupSignal" SG_ 672 BtnID_A 1;
BA_ "U_V710_MY2023_Rx" SG_ 672 BCP_Audible_Beep_Rq 1;
BA_ "U_P708_MY2023_Rx" SG_ 672 BCP_Audible_Beep_Rq 1;
BA_ "U_P708_MY2023_Rx" SG_ 1205 CstmDrvMdeCfg2_B_Avail 1;
BA_ "U_P708_MY2023_Rx" SG_ 1205 CstmDrvMdeCfg1_B_Avail 1;
BA_ "U_V710_MY2023_Rx" SG_ 1205 CstmDrvMde_No_Confg2 1;
BA_ "U_P708_MY2023_Rx" SG_ 1205 CstmDrvMde_No_Confg2 1;
BA_ "GenSigStartValue" SG_ 1205 CstmDrvMde_No_Confg2 63;
BA_ "U_V710_MY2023_Rx" SG_ 1205 CstmDrvMde_No_Confg1 1;
BA_ "U_P708_MY2023_Rx" SG_ 1205 CstmDrvMde_No_Confg1 1;
BA_ "GenSigStartValue" SG_ 1205 CstmDrvMde_No_Confg1 63;
BA_ "U_P708_MY2023_Rx" SG_ 1205 CstmDrvMde_No_Confg 1;
BA_ "U_P708_MY2023_Rx" SG_ 1205 CstmDrvMde5_No_Confg2 1;
BA_ "GenSigStartValue" SG_ 1205 CstmDrvMde5_No_Confg2 15;
BA_ "U_P708_MY2023_Rx" SG_ 1205 CstmDrvMde5_No_Confg1 1;
BA_ "GenSigStartValue" SG_ 1205 CstmDrvMde5_No_Confg1 15;
BA_ "U_P708_MY2023_Rx" SG_ 1205 CstmDrvMde4_No_Confg2 1;
BA_ "GenSigStartValue" SG_ 1205 CstmDrvMde4_No_Confg2 15;
BA_ "U_P708_MY2023_Rx" SG_ 1205 CstmDrvMde4_No_Confg1 1;
BA_ "GenSigStartValue" SG_ 1205 CstmDrvMde4_No_Confg1 15;
BA_ "U_P708_MY2023_Rx" SG_ 1205 CstmDrvMde3_No_Confg2 1;
BA_ "GenSigStartValue" SG_ 1205 CstmDrvMde3_No_Confg2 15;
BA_ "U_P708_MY2023_Rx" SG_ 1205 CstmDrvMde3_No_Confg1 1;
BA_ "GenSigStartValue" SG_ 1205 CstmDrvMde3_No_Confg1 15;
BA_ "U_P708_MY2023_Rx" SG_ 1205 CstmDrvMde2_No_Confg2 1;
BA_ "GenSigStartValue" SG_ 1205 CstmDrvMde2_No_Confg2 15;
BA_ "U_P708_MY2023_Rx" SG_ 1205 CstmDrvMde2_No_Confg1 1;
BA_ "GenSigStartValue" SG_ 1205 CstmDrvMde2_No_Confg1 15;
BA_ "U_P708_MY2023_Rx" SG_ 1205 CstmDrvMde1_No_Confg2 1;
BA_ "GenSigStartValue" SG_ 1205 CstmDrvMde1_No_Confg2 15;
BA_ "U_P708_MY2023_Rx" SG_ 1205 CstmDrvMde1_No_Confg1 1;
BA_ "GenSigStartValue" SG_ 1205 CstmDrvMde1_No_Confg1 15;
BA_ "GenSigStartValue" SG_ 1200 BrkBstrVac_P_Actl 127;
BA_ "MetaData" SG_ 1200 BrkTotTqRqDrv_No_Cnt 1;
BA_ "MetaData" SG_ 1200 BrkTotTqRqDrv_No_Cs 1;
BA_ "U_V710_MY2023_Tx" SG_ 593 ECG_MC_WORD_Tx 1;
BA_ "U_V713AV_MY2022_Tx" SG_ 593 ECG_MC_WORD_Tx 1;
BA_ "ECGUsedTxSignal" SG_ 593 ECG_MC_WORD_Tx 1;
BA_ "U_P708_MY2023_Rx" SG_ 593 ECG_MC_WORD_Tx 1;
BA_ "U_V713AV_MY2022_Rx" SG_ 593 ECG_MC_WORD_Tx 1;
BA_ "U_V713N_MY2022_Rx" SG_ 593 ECG_MC_WORD_Tx 1;
BA_ "U_P708_MY2023_Tx" SG_ 601 ECG_MC_WORD_Rx 1;
BA_ "U_V710_MY2023_Rx" SG_ 601 ECG_MC_WORD_Rx 1;
BA_ "U_P708_MY2023_Rx" SG_ 601 ECG_MC_WORD_Rx 1;
BA_ "U_V713AV_MY2022_Rx" SG_ 601 ECG_MC_WORD_Rx 1;
BA_ "U_V713N_MY2022_Rx" SG_ 601 ECG_MC_WORD_Rx 1;
BA_ "ECGUsedRxSignal" SG_ 601 ECG_MC_WORD_Rx 1;
BA_ "U_P708_MY2023_Rx" SG_ 1018 TrlrTireSensILM_D_Stat 1;
BA_ "U_P708_MY2023_Rx" SG_ 1018 TrlrTireSensILF_D_Stat 1;
BA_ "U_P708_MY2023_Rx" SG_ 1018 TrlrTireILR_P_Actl 1;
BA_ "GenSigStartValue" SG_ 1018 TrlrTireILR_P_Actl 65533;
BA_ "U_P708_MY2023_Rx" SG_ 1018 TrlrTireILM_P_Actl 1;
BA_ "GenSigStartValue" SG_ 1018 TrlrTireILM_P_Actl 65533;
BA_ "U_P708_MY2023_Rx" SG_ 1018 TrlrTireILF_P_Actl 1;
BA_ "GenSigStartValue" SG_ 1018 TrlrTireILF_P_Actl 65533;
BA_ "U_P708_MY2023_Rx" SG_ 1018 TrlrTireSensILR_D_Stat 1;
BA_ "U_V710_MY2023_Rx" SG_ 1238 GfhbMnu_D_Rq 1;
BA_ "U_P708_MY2023_Rx" SG_ 1238 GfhbMnu_D_Rq 1;
BA_ "U_V710_MY2023_Rx" SG_ 1238 AhbcMnu_D_Rq 1;
BA_ "U_P708_MY2023_Rx" SG_ 1238 AhbcMnu_D_Rq 1;
BA_ "U_V710_MY2023_Rx" SG_ 1238 TjaLaneBias_D_Stat 1;
BA_ "U_V710_MY2023_Rx" SG_ 1238 IaccVAdjReas_D_Dsply 1;
BA_ "U_P708_MY2023_Rx" SG_ 1238 IaccVAdjReas_D_Dsply 1;
BA_ "U_V713N_MY2022_Rx" SG_ 1238 IaccVAdjReas_D_Dsply 1;
BA_ "U_V710_MY2023_Rx" SG_ 1238 IaccVAdjLim_No_Actl 1;
BA_ "U_P708_MY2023_Rx" SG_ 1238 IaccVAdjLim_No_Actl 1;
BA_ "U_V713N_MY2022_Rx" SG_ 1238 IaccVAdjLim_No_Actl 1;
BA_ "U_P708_MY2023_Rx" SG_ 766 McCntrStckNotfn_B_Stat 1;
BA_ "GenSigSendType" SG_ 766 McCntrStckNotfn_B_Stat 3;
BA_ "U_P708_MY2023_Rx" SG_ 766 McSelMsgId_No_Actl 1;
BA_ "U_P708_MY2023_Rx" SG_ 766 McSelMsgId_B_Stat 1;
BA_ "GenSigSendType" SG_ 766 McSelMsgId_B_Stat 3;
BA_ "U_P708_MY2023_Rx" SG_ 766 McSelChoice_D_Stat 1;
BA_ "U_P708_MY2023_Rx" SG_ 766 McPrsntMsgId_No_Actl 1;
BA_ "GenSigSendType" SG_ 766 McPrsntMsgId_No_Actl 3;
BA_ "U_P708_MY2023_Rx" SG_ 766 McPrsntMsgId_B_Stat 1;
BA_ "GenSigSendType" SG_ 766 McPrsntMsgId_B_Stat 3;
BA_ "U_P708_MY2023_Rx" SG_ 766 McPrsntActv_D_Stat 1;
BA_ "GenSigSendType" SG_ 766 McPrsntActv_D_Stat 3;
BA_ "U_V710_MY2023_Tx" SG_ 840 FohAddHeater_D_Rq 1;
BA_ "GenSigSendType" SG_ 840 FohAddHeater_D_Rq 3;
BA_ "U_V710_MY2023_Tx" SG_ 840 FohStrtDateYr_No_Rq 1;
BA_ "U_V710_MY2023_Tx" SG_ 840 FohStrtDateDay_No_Rq 1;
BA_ "U_V710_MY2023_Tx" SG_ 840 FohT2Friday_T_Rq 1;
BA_ "GenSigSendType" SG_ 840 FohT2Friday_T_Rq 3;
BA_ "U_V710_MY2023_Tx" SG_ 840 FohT1Friday_T_Rq 1;
BA_ "GenSigSendType" SG_ 840 FohT1Friday_T_Rq 3;
BA_ "U_V710_MY2023_Tx" SG_ 840 FohT2Wednesday_T_Rq 1;
BA_ "GenSigSendType" SG_ 840 FohT2Wednesday_T_Rq 3;
BA_ "U_V710_MY2023_Tx" SG_ 840 FohT2Tuesday_T_Rq 1;
BA_ "GenSigSendType" SG_ 840 FohT2Tuesday_T_Rq 3;
BA_ "U_V710_MY2023_Tx" SG_ 840 FohT2Thursday_T_Rq 1;
BA_ "GenSigSendType" SG_ 840 FohT2Thursday_T_Rq 3;
BA_ "U_V710_MY2023_Tx" SG_ 840 FohT2Sunday_T_Rq 1;
BA_ "GenSigSendType" SG_ 840 FohT2Sunday_T_Rq 3;
BA_ "U_V710_MY2023_Tx" SG_ 840 FohT2Saturday_T_Rq 1;
BA_ "GenSigSendType" SG_ 840 FohT2Saturday_T_Rq 3;
BA_ "U_V710_MY2023_Tx" SG_ 840 FohT2Monday_T_Rq 1;
BA_ "GenSigSendType" SG_ 840 FohT2Monday_T_Rq 3;
BA_ "U_V710_MY2023_Tx" SG_ 840 FohT1Wednesday_T_Rq 1;
BA_ "GenSigSendType" SG_ 840 FohT1Wednesday_T_Rq 3;
BA_ "U_V710_MY2023_Tx" SG_ 840 FohT1Tuesday_T_Rq 1;
BA_ "GenSigSendType" SG_ 840 FohT1Tuesday_T_Rq 3;
BA_ "U_V710_MY2023_Tx" SG_ 840 FohT1Thursday_T_Rq 1;
BA_ "GenSigSendType" SG_ 840 FohT1Thursday_T_Rq 3;
BA_ "U_V710_MY2023_Tx" SG_ 840 FohT1Sunday_T_Rq 1;
BA_ "GenSigSendType" SG_ 840 FohT1Sunday_T_Rq 3;
BA_ "U_V710_MY2023_Tx" SG_ 840 FohT1Saturday_T_Rq 1;
BA_ "GenSigSendType" SG_ 840 FohT1Saturday_T_Rq 3;
BA_ "U_V710_MY2023_Tx" SG_ 840 FohT1Monday_T_Rq 1;
BA_ "GenSigSendType" SG_ 840 FohT1Monday_T_Rq 3;
BA_ "U_V713AV_MY2022_Tx" SG_ 494 HEC_TUPresetArea_Rq 1;
BA_ "U_V713N_MY2022_Tx" SG_ 494 HEC_TUPresetArea_Rq 1;
BA_ "U_V710_MY2023_Rx" SG_ 494 HEC_TUPresetArea_Rq 1;
BA_ "U_P708_MY2023_Rx" SG_ 494 HEC_TUPresetArea_Rq 1;
BA_ "U_V713AV_MY2022_Rx" SG_ 494 HEC_TUPresetArea_Rq 1;
BA_ "U_V713N_MY2022_Rx" SG_ 494 HEC_TUPresetArea_Rq 1;
BA_ "GenSigSendType" SG_ 494 HEC_TUPresetArea_Rq 3;
BA_ "U_V710_MY2023_Tx" SG_ 494 Mc_SetCurrPreset2_Rq 1;
BA_ "U_V713AV_MY2022_Tx" SG_ 494 Mc_SetCurrPreset2_Rq 1;
BA_ "U_V713N_MY2022_Tx" SG_ 494 Mc_SetCurrPreset2_Rq 1;
BA_ "U_V710_MY2023_Rx" SG_ 494 Mc_SetCurrPreset2_Rq 1;
BA_ "U_P708_MY2023_Rx" SG_ 494 Mc_SetCurrPreset2_Rq 1;
BA_ "U_V713AV_MY2022_Rx" SG_ 494 Mc_SetCurrPreset2_Rq 1;
BA_ "U_V713N_MY2022_Rx" SG_ 494 Mc_SetCurrPreset2_Rq 1;
BA_ "GenSigSendType" SG_ 494 Mc_SetCurrPreset2_Rq 3;
BA_ "U_V713AV_MY2022_Tx" SG_ 494 HEC_TUNbrOfPresets_Rq 1;
BA_ "U_V713N_MY2022_Tx" SG_ 494 HEC_TUNbrOfPresets_Rq 1;
BA_ "U_V710_MY2023_Rx" SG_ 494 HEC_TUNbrOfPresets_Rq 1;
BA_ "U_P708_MY2023_Rx" SG_ 494 HEC_TUNbrOfPresets_Rq 1;
BA_ "U_V713AV_MY2022_Rx" SG_ 494 HEC_TUNbrOfPresets_Rq 1;
BA_ "U_V713N_MY2022_Rx" SG_ 494 HEC_TUNbrOfPresets_Rq 1;
BA_ "U_V713AV_MY2022_Tx" SG_ 494 HEC_SetCurrTUBand_Rq 1;
BA_ "U_V713N_MY2022_Tx" SG_ 494 HEC_SetCurrTUBand_Rq 1;
BA_ "U_V710_MY2023_Rx" SG_ 494 HEC_SetCurrTUBand_Rq 1;
BA_ "U_P708_MY2023_Rx" SG_ 494 HEC_SetCurrTUBand_Rq 1;
BA_ "U_V713AV_MY2022_Rx" SG_ 494 HEC_SetCurrTUBand_Rq 1;
BA_ "U_V713N_MY2022_Rx" SG_ 494 HEC_SetCurrTUBand_Rq 1;
BA_ "GenSigSendType" SG_ 494 HEC_SetCurrTUBand_Rq 3;
BA_ "U_V713AV_MY2022_Tx" SG_ 494 HEC_TUStartIndex2_Rq 1;
BA_ "U_V713N_MY2022_Tx" SG_ 494 HEC_TUStartIndex2_Rq 1;
BA_ "U_V710_MY2023_Rx" SG_ 494 HEC_TUStartIndex2_Rq 1;
BA_ "U_P708_MY2023_Rx" SG_ 494 HEC_TUStartIndex2_Rq 1;
BA_ "U_V713AV_MY2022_Rx" SG_ 494 HEC_TUStartIndex2_Rq 1;
BA_ "U_V713N_MY2022_Rx" SG_ 494 HEC_TUStartIndex2_Rq 1;
BA_ "U_P708_MY2023_Tx" SG_ 714 SDARS_MC_WORD_Rx 1;
BA_ "U_V713AV_MY2022_Tx" SG_ 714 SDARS_MC_WORD_Rx 1;
BA_ "U_V713N_MY2022_Tx" SG_ 714 SDARS_MC_WORD_Rx 1;
BA_ "U_V710_MY2023_Rx" SG_ 714 SDARS_MC_WORD_Rx 1;
BA_ "U_P708_MY2023_Rx" SG_ 714 SDARS_MC_WORD_Rx 1;
BA_ "U_V713AV_MY2022_Rx" SG_ 714 SDARS_MC_WORD_Rx 1;
BA_ "U_V713N_MY2022_Rx" SG_ 714 SDARS_MC_WORD_Rx 1;
BA_ "U_V710_MY2023_Tx" SG_ 498 HEC_ARReqstrPriority_Rq 1;
BA_ "U_V713AV_MY2022_Tx" SG_ 498 HEC_ARReqstrPriority_Rq 1;
BA_ "U_V713N_MY2022_Tx" SG_ 498 HEC_ARReqstrPriority_Rq 1;
BA_ "U_V710_MY2023_Rx" SG_ 498 HEC_ARReqstrPriority_Rq 1;
BA_ "U_P708_MY2023_Rx" SG_ 498 HEC_ARReqstrPriority_Rq 1;
BA_ "U_V713AV_MY2022_Rx" SG_ 498 HEC_ARReqstrPriority_Rq 1;
BA_ "U_V713N_MY2022_Rx" SG_ 498 HEC_ARReqstrPriority_Rq 1;
BA_ "U_V710_MY2023_Tx" SG_ 498 HEC_AROperationType_Rq 1;
BA_ "U_V713AV_MY2022_Tx" SG_ 498 HEC_AROperationType_Rq 1;
BA_ "U_V713N_MY2022_Tx" SG_ 498 HEC_AROperationType_Rq 1;
BA_ "U_V710_MY2023_Rx" SG_ 498 HEC_AROperationType_Rq 1;
BA_ "U_P708_MY2023_Rx" SG_ 498 HEC_AROperationType_Rq 1;
BA_ "U_V713AV_MY2022_Rx" SG_ 498 HEC_AROperationType_Rq 1;
BA_ "U_V713N_MY2022_Rx" SG_ 498 HEC_AROperationType_Rq 1;
BA_ "GenSigSendType" SG_ 498 HEC_AROperationType_Rq 3;
BA_ "U_V710_MY2023_Tx" SG_ 498 HEC_ARReqstrSystem_Rq 1;
BA_ "U_V713AV_MY2022_Tx" SG_ 498 HEC_ARReqstrSystem_Rq 1;
BA_ "U_V713N_MY2022_Tx" SG_ 498 HEC_ARReqstrSystem_Rq 1;
BA_ "U_V710_MY2023_Rx" SG_ 498 HEC_ARReqstrSystem_Rq 1;
BA_ "U_P708_MY2023_Rx" SG_ 498 HEC_ARReqstrSystem_Rq 1;
BA_ "U_V713AV_MY2022_Rx" SG_ 498 HEC_ARReqstrSystem_Rq 1;
BA_ "U_V713N_MY2022_Rx" SG_ 498 HEC_ARReqstrSystem_Rq 1;
BA_ "U_V710_MY2023_Tx" SG_ 498 HEC_ARAudioSource_Rq 1;
BA_ "U_V713AV_MY2022_Tx" SG_ 498 HEC_ARAudioSource_Rq 1;
BA_ "U_V713N_MY2022_Tx" SG_ 498 HEC_ARAudioSource_Rq 1;
BA_ "U_V710_MY2023_Rx" SG_ 498 HEC_ARAudioSource_Rq 1;
BA_ "U_P708_MY2023_Rx" SG_ 498 HEC_ARAudioSource_Rq 1;
BA_ "U_V713AV_MY2022_Rx" SG_ 498 HEC_ARAudioSource_Rq 1;
BA_ "U_V713N_MY2022_Rx" SG_ 498 HEC_ARAudioSource_Rq 1;
BA_ "U_V713N_MY2022_Rx" SG_ 145 MFD_Year 1;
BA_ "U_V713N_MY2022_Rx" SG_ 145 MFD_Second 1;
BA_ "GenSigSendType" SG_ 145 MFD_Second 3;
BA_ "U_V713N_MY2022_Rx" SG_ 145 MFD_Month 1;
BA_ "U_V713N_MY2022_Rx" SG_ 145 MFD_Minute 1;
BA_ "U_V713N_MY2022_Rx" SG_ 145 MFD_Hour 1;
BA_ "U_V713N_MY2022_Rx" SG_ 145 MFD_Day 1;
BA_ "U_V710_MY2023_Tx" SG_ 597 AUDIO_RSE_WORD_Tx 1;
BA_ "U_P708_MY2023_Tx" SG_ 597 AUDIO_RSE_WORD_Tx 1;
BA_ "U_V713AV_MY2022_Tx" SG_ 597 AUDIO_RSE_WORD_Tx 1;
BA_ "U_V713N_MY2022_Tx" SG_ 597 AUDIO_RSE_WORD_Tx 1;
BA_ "U_V710_MY2023_Rx" SG_ 605 AUDIO_RSE_WORD_Rx 1;
BA_ "U_P708_MY2023_Rx" SG_ 605 AUDIO_RSE_WORD_Rx 1;
BA_ "U_V713AV_MY2022_Rx" SG_ 605 AUDIO_RSE_WORD_Rx 1;
BA_ "U_V713N_MY2022_Rx" SG_ 605 AUDIO_RSE_WORD_Rx 1;
BA_ "U_P708_MY2023_Rx" SG_ 827 LghtAmbIntns_D2_Sns 1;
BA_ "GenSigStartValue" SG_ 827 LghtAmbIntns_D2_Sns 3;
BA_ "WakeupSignal" SG_ 827 SteClmnSwtchTlt_D_Stat 1;
BA_ "WakeupSignal" SG_ 827 SteClmnSwtchTel_D_Stat 1;
BA_ "U_P708_MY2023_Rx" SG_ 827 LghtAmbIntns_D_Sns 1;
BA_ "U_P708_MY2023_Rx" SG_ 827 LghtAmb_Intns_Sns 1;
BA_ "U_P708_MY2023_Rx" SG_ 1043 PrkBrkPerfMde_D_Stat 1;
BA_ "U_P708_MY2023_Rx" SG_ 1043 PrkBrkPerfMsgTxt_D_Rq 1;
BA_ "U_V710_MY2023_Rx" SG_ 1043 SelDrvMdeHmi04_D_Rq 1;
BA_ "U_P708_MY2023_Rx" SG_ 1043 SelDrvMdeHmi04_D_Rq 1;
BA_ "U_V713AV_MY2022_Rx" SG_ 1043 SelDrvMdeHmi04_D_Rq 1;
BA_ "U_V713N_MY2022_Rx" SG_ 1043 SelDrvMdeHmi04_D_Rq 1;
BA_ "U_V710_MY2023_Rx" SG_ 1043 SelDrvMdeHmi02_D_Rq 1;
BA_ "U_P708_MY2023_Rx" SG_ 1043 SelDrvMdeHmi02_D_Rq 1;
BA_ "U_P708_MY2023_Rx" SG_ 1043 IndvMde5_B_Avail 1;
BA_ "U_P708_MY2023_Rx" SG_ 1043 IndvMde4_B_Avail 1;
BA_ "U_P708_MY2023_Rx" SG_ 1043 IndvMde3_B_Avail 1;
BA_ "U_P708_MY2023_Rx" SG_ 1043 IndvMde2_B_Avail 1;
BA_ "U_P708_MY2023_Rx" SG_ 1043 IndvMde1_B_Avail 1;
BA_ "U_V710_MY2023_Rx" SG_ 1043 IndvMdeSusp_No_Stat 1;
BA_ "U_P708_MY2023_Rx" SG_ 1043 IndvMdeSusp_No_Stat 1;
BA_ "GenSigStartValue" SG_ 1043 IndvMdeSusp_No_Stat 15;
BA_ "U_V710_MY2023_Rx" SG_ 1043 IndvMdeSte_No_Stat 1;
BA_ "U_P708_MY2023_Rx" SG_ 1043 IndvMdeSte_No_Stat 1;
BA_ "GenSigStartValue" SG_ 1043 IndvMdeSte_No_Stat 15;
BA_ "U_V710_MY2023_Rx" SG_ 1043 IndvMdeSel_No_Rq 1;
BA_ "U_P708_MY2023_Rx" SG_ 1043 IndvMdeSel_No_Rq 1;
BA_ "GenSigStartValue" SG_ 1043 IndvMdeSel_No_Rq 15;
BA_ "U_V710_MY2023_Rx" SG_ 1043 IndvMdeSel_D_Stat 1;
BA_ "U_P708_MY2023_Rx" SG_ 1043 IndvMdeSel_D_Stat 1;
BA_ "U_V710_MY2023_Rx" SG_ 1043 IndvMdeMsgTxt_D_Rq 1;
BA_ "U_P708_MY2023_Rx" SG_ 1043 IndvMdeMsgTxt_D_Rq 1;
BA_ "U_P708_MY2023_Rx" SG_ 1043 TrailOnePdlMsgTxt_D_Rq 1;
BA_ "U_P708_MY2023_Rx" SG_ 1043 TrailOnePdlMde_D_Ind 1;
BA_ "U_P708_MY2023_Rx" SG_ 1043 OrtaMsgTxt_D_Rq 1;
BA_ "U_P708_MY2023_Rx" SG_ 1043 OrtaMde_D_Ind 1;
BA_ "GenSigStartValue" SG_ 876 SeatLmbrUpRr_Pc_Actl 127;
BA_ "GenSigStartValue" SG_ 876 SeatLmbrMidRr_Pc_Actl 127;
BA_ "GenSigStartValue" SG_ 876 SeatLmbrLoRr_Pc_Actl 127;
BA_ "GenSigStartValue" SG_ 875 SeatLmbrUpRl_Pc_Actl 127;
BA_ "GenSigStartValue" SG_ 875 SeatLmbrMidRl_Pc_Actl 127;
BA_ "GenSigStartValue" SG_ 875 SeatLmbrLoRl_Pc_Actl 127;
BA_ "GenSigSendType" SG_ 545 SpkrDgtlRight_D_Stat 3;
BA_ "GenSigSendType" SG_ 545 SpkrDgtlLeft_D_Stat 3;
BA_ "U_V710_MY2023_Rx" SG_ 545 SpkrDgtlCntr_D_Stat 1;
BA_ "U_P708_MY2023_Rx" SG_ 545 SpkrDgtlCntr_D_Stat 1;
BA_ "U_V713AV_MY2022_Rx" SG_ 545 SpkrDgtlCntr_D_Stat 1;
BA_ "U_V713N_MY2022_Rx" SG_ 545 SpkrDgtlCntr_D_Stat 1;
BA_ "GenSigSendType" SG_ 545 SpkrDgtlCntr_D_Stat 3;
BA_ "GenSigSendType" SG_ 545 SurndSndUpmix2_D_Stat 3;
BA_ "GenSigSendType" SG_ 545 DSP_Bezel_Diag_St 3;
BA_ "GenSigSendType" SG_ 545 SndImmrsnLvl_D_Stat 3;
BA_ "GenSigSendType" SG_ 545 DSP_Sur_Sound_st 3;
BA_ "GenSigSendType" SG_ 545 DSP_MyKeyVolLimitUp_St 3;
BA_ "GenSigSendType" SG_ 545 DSP_MyKeyVolLim_St 3;
BA_ "GenSigSendType" SG_ 545 DSP_BeltminderAudio_St 3;
BA_ "U_V710_MY2023_Rx" SG_ 545 DSP_Audio_Volume_Up_St 1;
BA_ "U_P708_MY2023_Rx" SG_ 545 DSP_Audio_Volume_Up_St 1;
BA_ "U_V713AV_MY2022_Rx" SG_ 545 DSP_Audio_Volume_Up_St 1;
BA_ "U_V713N_MY2022_Rx" SG_ 545 DSP_Audio_Volume_Up_St 1;
BA_ "ECGUsedRxSignal" SG_ 545 DSP_Audio_Volume_Up_St 1;
BA_ "GenSigSendType" SG_ 545 DSP_Audio_Volume_Up_St 3;
BA_ "U_V710_MY2023_Rx" SG_ 545 DSP_Audio_Vol_Level_St 1;
BA_ "U_V713AV_MY2022_Rx" SG_ 545 DSP_Audio_Vol_Level_St 1;
BA_ "U_P708_MY2023_Rx" SG_ 545 DSP_Audio_Vol_Level_St 1;
BA_ "U_V713N_MY2022_Rx" SG_ 545 DSP_Audio_Vol_Level_St 1;
BA_ "GenSigSendType" SG_ 545 DSP_Audio_Vol_Level_St 3;
BA_ "GenSigSendType" SG_ 545 AutoConfigOcc_Rear 3;
BA_ "GenSigSendType" SG_ 545 AutoConfigOcc_Front 3;
BA_ "GenSigSendType" SG_ 545 AutoConfigOcc_Driver 3;
BA_ "GenSigSendType" SG_ 545 AutoConfigOcc_AllSeats 3;
BA_ "GenSigSendType" SG_ 545 AudioOccMde_D_Stat 3;
BA_ "GenSigStartValue" SG_ 1092 BattTracMnCell_Te_Actl 254;
BA_ "GenSigStartValue" SG_ 1092 BattTracMxCell_Te_Actl 254;
BA_ "GenSigStartValue" SG_ 1092 BattTracInsltn_R_Actl 255;
BA_ "U_V710_MY2023_Rx" SG_ 936 ApaSys_D_Stat 1;
BA_ "U_P708_MY2023_Rx" SG_ 936 ApaSys_D_Stat 1;
BA_ "U_V713AV_MY2022_Rx" SG_ 936 ApaSys_D_Stat 1;
BA_ "U_V713N_MY2022_Rx" SG_ 936 ApaSys_D_Stat 1;
BA_ "GenSigSendType" SG_ 936 ApaSys_D_Stat 3;
BA_ "U_P708_MY2023_Rx" SG_ 936 ApaSteWhl_D_RqDrv 1;
BA_ "U_V713AV_MY2022_Rx" SG_ 936 ApaSteWhl_D_RqDrv 1;
BA_ "U_V713N_MY2022_Rx" SG_ 936 ApaSteWhl_D_RqDrv 1;
BA_ "GenSigSendType" SG_ 936 ApaSteWhl_D_RqDrv 3;
BA_ "U_P708_MY2023_Rx" SG_ 936 ApaSteScanMde_D_Stat 1;
BA_ "U_V713AV_MY2022_Rx" SG_ 936 ApaSteScanMde_D_Stat 1;
BA_ "U_V713N_MY2022_Rx" SG_ 936 ApaSteScanMde_D_Stat 1;
BA_ "GenSigSendType" SG_ 936 ApaSteScanMde_D_Stat 3;
BA_ "U_P708_MY2023_Rx" SG_ 936 ApaSelSapp_D_Stat 1;
BA_ "U_V713AV_MY2022_Rx" SG_ 936 ApaSelSapp_D_Stat 1;
BA_ "U_V713N_MY2022_Rx" SG_ 936 ApaSelSapp_D_Stat 1;
BA_ "GenSigSendType" SG_ 936 ApaSelSapp_D_Stat 3;
BA_ "U_P708_MY2023_Rx" SG_ 936 ApaSelPpa_D_Stat 1;
BA_ "U_V713AV_MY2022_Rx" SG_ 936 ApaSelPpa_D_Stat 1;
BA_ "U_V713N_MY2022_Rx" SG_ 936 ApaSelPpa_D_Stat 1;
BA_ "GenSigSendType" SG_ 936 ApaSelPpa_D_Stat 3;
BA_ "U_P708_MY2023_Rx" SG_ 936 ApaSelPoa_D_Stat 1;
BA_ "U_V713AV_MY2022_Rx" SG_ 936 ApaSelPoa_D_Stat 1;
BA_ "U_V713N_MY2022_Rx" SG_ 936 ApaSelPoa_D_Stat 1;
BA_ "GenSigSendType" SG_ 936 ApaSelPoa_D_Stat 3;
BA_ "U_P708_MY2023_Rx" SG_ 936 ApaScan_D_Stat 1;
BA_ "U_V713AV_MY2022_Rx" SG_ 936 ApaScan_D_Stat 1;
BA_ "U_V713N_MY2022_Rx" SG_ 936 ApaScan_D_Stat 1;
BA_ "GenSigSendType" SG_ 936 ApaScan_D_Stat 3;
BA_ "U_P708_MY2023_Rx" SG_ 936 ApaLongCtl_D_RqDrv 1;
BA_ "U_V713AV_MY2022_Rx" SG_ 936 ApaLongCtl_D_RqDrv 1;
BA_ "U_V713N_MY2022_Rx" SG_ 936 ApaLongCtl_D_RqDrv 1;
BA_ "GenSigSendType" SG_ 936 ApaLongCtl_D_RqDrv 3;
BA_ "U_P708_MY2023_Rx" SG_ 936 ApaGearShif_D_RqDrv 1;
BA_ "U_V713AV_MY2022_Rx" SG_ 936 ApaGearShif_D_RqDrv 1;
BA_ "U_V713N_MY2022_Rx" SG_ 936 ApaGearShif_D_RqDrv 1;
BA_ "GenSigSendType" SG_ 936 ApaGearShif_D_RqDrv 3;
BA_ "U_P708_MY2023_Rx" SG_ 936 ApaActvSide2_D_Stat 1;
BA_ "U_V713AV_MY2022_Rx" SG_ 936 ApaActvSide2_D_Stat 1;
BA_ "U_V713N_MY2022_Rx" SG_ 936 ApaActvSide2_D_Stat 1;
BA_ "GenSigSendType" SG_ 936 ApaActvSide2_D_Stat 3;
BA_ "U_P708_MY2023_Rx" SG_ 936 ApaAcsy_D_RqDrv 1;
BA_ "U_V713AV_MY2022_Rx" SG_ 936 ApaAcsy_D_RqDrv 1;
BA_ "U_V713N_MY2022_Rx" SG_ 936 ApaAcsy_D_RqDrv 1;
BA_ "GenSigSendType" SG_ 936 ApaAcsy_D_RqDrv 3;
BA_ "U_V710_MY2023_Rx" SG_ 936 ApaChime_D_Rq 1;
BA_ "U_P708_MY2023_Rx" SG_ 936 ApaChime_D_Rq 1;
BA_ "U_V713AV_MY2022_Rx" SG_ 936 ApaChime_D_Rq 1;
BA_ "U_V713N_MY2022_Rx" SG_ 936 ApaChime_D_Rq 1;
BA_ "GenSigSendType" SG_ 936 ApaChime_D_Rq 3;
BA_ "GenSigSendType" SG_ 936 EPASExtAngleStatReq 3;
BA_ "U_V710_MY2023_Rx" SG_ 936 ApaTrgtDist_D_Stat 1;
BA_ "U_P708_MY2023_Rx" SG_ 936 ApaTrgtDist_D_Stat 1;
BA_ "U_V713AV_MY2022_Rx" SG_ 936 ApaTrgtDist_D_Stat 1;
BA_ "U_V713N_MY2022_Rx" SG_ 936 ApaTrgtDist_D_Stat 1;
BA_ "U_V710_MY2023_Rx" SG_ 936 ApaMsgTxt_D_Rq 1;
BA_ "U_P708_MY2023_Rx" SG_ 936 ApaMsgTxt_D_Rq 1;
BA_ "U_V713AV_MY2022_Rx" SG_ 936 ApaMsgTxt_D_Rq 1;
BA_ "U_V713N_MY2022_Rx" SG_ 936 ApaMsgTxt_D_Rq 1;
BA_ "GenSigSendType" SG_ 674 ArmrestStwdRear_B_Stat 3;
BA_ "GenSigStartValue" SG_ 674 ArmrestStwdRear_B_Stat 1;
BA_ "GenSigSendType" SG_ 674 RACM_SetVolume 3;
BA_ "GenSigSendType" SG_ 674 RACM_Coding_BtnID_D 3;
BA_ "GenSigSendType" SG_ 674 RACM_Coding_BtnID_C 3;
BA_ "GenSigSendType" SG_ 674 RACM_Coding_BtnID_B 3;
BA_ "GenSigSendType" SG_ 674 RACM_Coding_BtnID_A 3;
BA_ "GenSigSendType" SG_ 674 RACM_BtnID_D 3;
BA_ "GenSigSendType" SG_ 674 RACM_BtnID_C 3;
BA_ "GenSigSendType" SG_ 674 RACM_BtnID_B 3;
BA_ "GenSigSendType" SG_ 674 RACM_BtnID_A 3;
BA_ "GenSigSendType" SG_ 674 RearAudioCtlLck_D_Stat 3;
BA_ "U_P708_MY2023_Rx" SG_ 75 VedsPasKneeBag_D_Ltchd 1;
BA_ "U_V713AV_MY2022_Rx" SG_ 75 VedsPasKneeBag_D_Ltchd 1;
BA_ "U_V713N_MY2022_Rx" SG_ 75 VedsPasKneeBag_D_Ltchd 1;
BA_ "GenSigSendType" SG_ 75 VedsPasKneeBag_D_Ltchd 3;
BA_ "GenSigSendType" SG_ 75 VedsRw1mBckl_D_Ltchd 3;
BA_ "GenSigSendType" SG_ 75 VedsRw1mBelt_D_Ltchd 3;
BA_ "GenSigSendType" SG_ 75 VedsRw2pRib_D_Ltchd 3;
BA_ "GenSigSendType" SG_ 75 VedsRw2dRib_D_Ltchd 3;
BA_ "GenSigSendType" SG_ 75 VedsRw3pBckl_D_Ltchd 3;
BA_ "GenSigSendType" SG_ 75 VedsRw3mBckl_D_Ltchd 3;
BA_ "GenSigSendType" SG_ 75 VedsRw3dBckl_D_Ltchd 3;
BA_ "GenSigSendType" SG_ 75 VedsRw2pBckl_D_Ltchd 3;
BA_ "GenSigSendType" SG_ 75 VedsRw2mBckl_D_Ltchd 3;
BA_ "GenSigSendType" SG_ 75 VedsRw2dBckl_D_Ltchd 3;
BA_ "GenSigSendType" SG_ 75 VedsRw1PasChld_D_Ltchd 3;
BA_ "GenSigSendType" SG_ 75 VedsRw1PasBckl_D_Ltchd 3;
BA_ "GenSigSendType" SG_ 75 VedsRw1DrvBckl_D_Ltchd 3;
BA_ "GenSigSendType" SG_ 75 VedsRw3pRib_D_Ltchd 3;
BA_ "GenSigSendType" SG_ 75 VedsRw3dRib_D_Ltchd 3;
BA_ "GenSigSendType" SG_ 74 VedsPasSideBag_D_Ltchd 3;
BA_ "GenSigSendType" SG_ 74 VedsPasCrtnBag_D_Ltchd 3;
BA_ "GenSigSendType" SG_ 74 VedsPasBelt_D_Ltchd 3;
BA_ "GenSigSendType" SG_ 74 VedsPasBag_D_Ltchd 3;
BA_ "GenSigSendType" SG_ 74 VedsMultiEvnt_D_Ltchd 3;
BA_ "GenSigSendType" SG_ 74 VedsDrvKneeBag_D_Ltchd 3;
BA_ "GenSigSendType" SG_ 74 VedsEvntType_D_Ltchd 3;
BA_ "GenSigSendType" SG_ 74 VedsEvntRoll_D_Ltchd 3;
BA_ "GenSigSendType" SG_ 74 VedsDrvSideBag_D_Ltchd 3;
BA_ "GenSigSendType" SG_ 74 VedsDrvCrtnBag_D_Ltchd 3;
BA_ "GenSigSendType" SG_ 74 VedsDrvBelt_D_Ltchd 3;
BA_ "U_V710_MY2023_Rx" SG_ 74 VedsDrvBag_D_Ltchd 1;
BA_ "U_P708_MY2023_Rx" SG_ 74 VedsDrvBag_D_Ltchd 1;
BA_ "U_V713AV_MY2022_Rx" SG_ 74 VedsDrvBag_D_Ltchd 1;
BA_ "U_V713N_MY2022_Rx" SG_ 74 VedsDrvBag_D_Ltchd 1;
BA_ "GenSigSendType" SG_ 74 VedsDrvBag_D_Ltchd 3;
BA_ "GenSigSendType" SG_ 74 eCallNotification 3;
BA_ "GenSigStartValue" SG_ 74 eCallNotification 1;
BA_ "U_P708_MY2023_Rx" SG_ 780 TrlrTireSensRm_D_Stat 1;
BA_ "U_V713N_MY2022_Rx" SG_ 780 TrlrTireSensRm_D_Stat 1;
BA_ "U_P708_MY2023_Rx" SG_ 780 TrlrTireSensRf_D_Stat 1;
BA_ "U_V713N_MY2022_Rx" SG_ 780 TrlrTireSensRf_D_Stat 1;
BA_ "U_P708_MY2023_Rx" SG_ 780 TrlrTireRr_P_Actl 1;
BA_ "U_V713N_MY2022_Rx" SG_ 780 TrlrTireRr_P_Actl 1;
BA_ "GenSigStartValue" SG_ 780 TrlrTireRr_P_Actl 65533;
BA_ "U_P708_MY2023_Rx" SG_ 780 TrlrTireRm_P_Actl 1;
BA_ "U_V713N_MY2022_Rx" SG_ 780 TrlrTireRm_P_Actl 1;
BA_ "GenSigStartValue" SG_ 780 TrlrTireRm_P_Actl 65533;
BA_ "U_P708_MY2023_Rx" SG_ 780 TrlrTireRf_P_Actl 1;
BA_ "U_V713N_MY2022_Rx" SG_ 780 TrlrTireRf_P_Actl 1;
BA_ "GenSigStartValue" SG_ 780 TrlrTireRf_P_Actl 65533;
BA_ "U_P708_MY2023_Rx" SG_ 780 TrlrTireSensRr_D_Stat 1;
BA_ "U_V713N_MY2022_Rx" SG_ 780 TrlrTireSensRr_D_Stat 1;
BA_ "U_P708_MY2023_Rx" SG_ 779 TrlrTireSensLr_D_Stat 1;
BA_ "U_V713N_MY2022_Rx" SG_ 779 TrlrTireSensLr_D_Stat 1;
BA_ "U_P708_MY2023_Rx" SG_ 779 TrlrTireSensLm_D_Stat 1;
BA_ "U_V713N_MY2022_Rx" SG_ 779 TrlrTireSensLm_D_Stat 1;
BA_ "U_P708_MY2023_Rx" SG_ 779 TrlrTireSensLf_D_Stat 1;
BA_ "U_V713N_MY2022_Rx" SG_ 779 TrlrTireSensLf_D_Stat 1;
BA_ "U_P708_MY2023_Rx" SG_ 779 TrlrTireLr_P_Actl 1;
BA_ "U_V713N_MY2022_Rx" SG_ 779 TrlrTireLr_P_Actl 1;
BA_ "GenSigStartValue" SG_ 779 TrlrTireLr_P_Actl 65533;
BA_ "U_P708_MY2023_Rx" SG_ 779 TrlrTireLm_P_Actl 1;
BA_ "U_V713N_MY2022_Rx" SG_ 779 TrlrTireLm_P_Actl 1;
BA_ "GenSigStartValue" SG_ 779 TrlrTireLm_P_Actl 65533;
BA_ "U_P708_MY2023_Rx" SG_ 779 TrlrTireLf_P_Actl 1;
BA_ "U_V713N_MY2022_Rx" SG_ 779 TrlrTireLf_P_Actl 1;
BA_ "GenSigStartValue" SG_ 779 TrlrTireLf_P_Actl 65533;
BA_ "U_V713AV_MY2022_Tx" SG_ 783 TrlrTireThresh_D_RqDrv 1;
BA_ "U_V713N_MY2022_Tx" SG_ 783 TrlrTireThresh_D_RqDrv 1;
BA_ "U_P708_MY2023_Tx" SG_ 783 TrlrTireCnt_D_RqDrv 1;
BA_ "U_V713AV_MY2022_Tx" SG_ 783 TrlrTireCnt_D_RqDrv 1;
BA_ "U_V713N_MY2022_Tx" SG_ 783 TrlrTireCnt_D_RqDrv 1;
BA_ "GenSigSendType" SG_ 783 TrlrTireCnt_D_RqDrv 3;
BA_ "U_P708_MY2023_Tx" SG_ 783 TrlrLearnMdeOn_B_RqDrv 1;
BA_ "U_V713AV_MY2022_Tx" SG_ 783 TrlrLearnMdeOn_B_RqDrv 1;
BA_ "U_V713N_MY2022_Tx" SG_ 783 TrlrLearnMdeOn_B_RqDrv 1;
BA_ "GenSigSendType" SG_ 783 TrlrLearnMdeOn_B_RqDrv 3;
BA_ "U_V710_MY2023_Rx" SG_ 638 EmgcyCallFalt_B_Dsply 1;
BA_ "U_P708_MY2023_Rx" SG_ 638 EmgcyCallFalt_B_Dsply 1;
BA_ "U_V713AV_MY2022_Rx" SG_ 638 EmgcyCallFalt_B_Dsply 1;
BA_ "U_V713N_MY2022_Rx" SG_ 638 EmgcyCallFalt_B_Dsply 1;
BA_ "U_P708_MY2023_Tx" SG_ 555 HudVertSzMnuOn_B_Stat 1;
BA_ "U_V710_MY2023_Rx" SG_ 555 HudVertSzMnuOn_B_Stat 1;
BA_ "U_V713AV_MY2022_Rx" SG_ 555 HudVertSzMnuOn_B_Stat 1;
BA_ "U_V713N_MY2022_Rx" SG_ 555 HudVertSzMnuOn_B_Stat 1;
BA_ "GenSigSendType" SG_ 555 HudVertSzMnuOn_B_Stat 3;
BA_ "U_P708_MY2023_Tx" SG_ 555 HudVertMnuOn_B_Stat 1;
BA_ "U_V710_MY2023_Rx" SG_ 555 HudVertMnuOn_B_Stat 1;
BA_ "U_V713AV_MY2022_Rx" SG_ 555 HudVertMnuOn_B_Stat 1;
BA_ "U_V713N_MY2022_Rx" SG_ 555 HudVertMnuOn_B_Stat 1;
BA_ "GenSigSendType" SG_ 555 HudVertMnuOn_B_Stat 3;
BA_ "U_P708_MY2023_Tx" SG_ 555 HudTestMdeActv_B_Stat 1;
BA_ "U_V710_MY2023_Rx" SG_ 555 HudTestMdeActv_B_Stat 1;
BA_ "U_V713AV_MY2022_Rx" SG_ 555 HudTestMdeActv_B_Stat 1;
BA_ "U_V713N_MY2022_Rx" SG_ 555 HudTestMdeActv_B_Stat 1;
BA_ "GenSigSendType" SG_ 555 HudTestMdeActv_B_Stat 3;
BA_ "U_P708_MY2023_Tx" SG_ 555 HudSwtch_B_Stat 1;
BA_ "U_V710_MY2023_Rx" SG_ 555 HudSwtch_B_Stat 1;
BA_ "U_V713AV_MY2022_Rx" SG_ 555 HudSwtch_B_Stat 1;
BA_ "U_V713N_MY2022_Rx" SG_ 555 HudSwtch_B_Stat 1;
BA_ "GenSigSendType" SG_ 555 HudSwtch_B_Stat 3;
BA_ "U_P708_MY2023_Tx" SG_ 555 HudRotatMnuOn_B_Stat 1;
BA_ "U_V713AV_MY2022_Rx" SG_ 555 HudRotatMnuOn_B_Stat 1;
BA_ "U_V713N_MY2022_Rx" SG_ 555 HudRotatMnuOn_B_Stat 1;
BA_ "GenSigSendType" SG_ 555 HudRotatMnuOn_B_Stat 3;
BA_ "U_P708_MY2023_Tx" SG_ 555 HudMsgTxt_D_Rq 1;
BA_ "U_V710_MY2023_Rx" SG_ 555 HudMsgTxt_D_Rq 1;
BA_ "U_V713AV_MY2022_Rx" SG_ 555 HudMsgTxt_D_Rq 1;
BA_ "U_V713N_MY2022_Rx" SG_ 555 HudMsgTxt_D_Rq 1;
BA_ "GenSigSendType" SG_ 555 HudMsgTxt_D_Rq 3;
BA_ "U_P708_MY2023_Tx" SG_ 555 HudHzntlMnuOn_B_Stat 1;
BA_ "U_V713AV_MY2022_Rx" SG_ 555 HudHzntlMnuOn_B_Stat 1;
BA_ "U_V713N_MY2022_Rx" SG_ 555 HudHzntlMnuOn_B_Stat 1;
BA_ "GenSigSendType" SG_ 555 HudHzntlMnuOn_B_Stat 3;
BA_ "U_P708_MY2023_Tx" SG_ 555 HudBrightMnuOn_B_Stat 1;
BA_ "U_V710_MY2023_Rx" SG_ 555 HudBrightMnuOn_B_Stat 1;
BA_ "U_V713AV_MY2022_Rx" SG_ 555 HudBrightMnuOn_B_Stat 1;
BA_ "U_V713N_MY2022_Rx" SG_ 555 HudBrightMnuOn_B_Stat 1;
BA_ "GenSigSendType" SG_ 555 HudBrightMnuOn_B_Stat 3;
BA_ "U_P708_MY2023_Tx" SG_ 555 HudActv_D_Stat 1;
BA_ "U_V710_MY2023_Rx" SG_ 555 HudActv_D_Stat 1;
BA_ "U_V713AV_MY2022_Rx" SG_ 555 HudActv_D_Stat 1;
BA_ "U_V713N_MY2022_Rx" SG_ 555 HudActv_D_Stat 1;
BA_ "GenSigSendType" SG_ 555 HudActv_D_Stat 3;
BA_ "GenSigStartValue" SG_ 124 VehTrvlDir_D_Stat 6;
BA_ "U_P708_MY2023_Rx" SG_ 124 VehOverGnd_V_Est 1;
BA_ "U_V713AV_MY2022_Rx" SG_ 124 VehOverGnd_V_Est 1;
BA_ "U_V713N_MY2022_Rx" SG_ 124 VehOverGnd_V_Est 1;
BA_ "U_P708_MY2023_Rx" SG_ 124 VehLongComp_A_Actl 1;
BA_ "U_V713AV_MY2022_Rx" SG_ 124 VehLongComp_A_Actl 1;
BA_ "U_V713N_MY2022_Rx" SG_ 124 VehLongComp_A_Actl 1;
BA_ "GenSigStartValue" SG_ 124 VehLongComp_A_Actl 1022;
BA_ "U_P708_MY2023_Rx" SG_ 124 VehLatComp_A_Actl 1;
BA_ "U_V713AV_MY2022_Rx" SG_ 124 VehLatComp_A_Actl 1;
BA_ "U_V713N_MY2022_Rx" SG_ 124 VehLatComp_A_Actl 1;
BA_ "GenSigStartValue" SG_ 124 VehLatComp_A_Actl 1022;
BA_ "U_P708_MY2023_Rx" SG_ 124 VehYawComp_W_Actl 1;
BA_ "U_V713AV_MY2022_Rx" SG_ 124 VehYawComp_W_Actl 1;
BA_ "U_V713N_MY2022_Rx" SG_ 124 VehYawComp_W_Actl 1;
BA_ "GenSigStartValue" SG_ 124 VehYawComp_W_Actl 4094;
BA_ "U_P708_MY2023_Rx" SG_ 736 TextMessage_Rsp 1;
BA_ "U_V713AV_MY2022_Rx" SG_ 736 TextMessage_Rsp 1;
BA_ "U_V713N_MY2022_Rx" SG_ 736 TextMessage_Rsp 1;
BA_ "GenSigSendType" SG_ 736 TextMessage_Rsp 3;
BA_ "GenSigSendType" SG_ 736 VRM_IncCallOption_St 3;
BA_ "U_P708_MY2023_Rx" SG_ 736 VRM_CallDuration_St 1;
BA_ "U_V713AV_MY2022_Rx" SG_ 736 VRM_CallDuration_St 1;
BA_ "U_V713N_MY2022_Rx" SG_ 736 VRM_CallDuration_St 1;
BA_ "U_P708_MY2023_Rx" SG_ 736 BTInCallOptions_St 1;
BA_ "U_V713AV_MY2022_Rx" SG_ 736 BTInCallOptions_St 1;
BA_ "U_V713N_MY2022_Rx" SG_ 736 BTInCallOptions_St 1;
BA_ "GenSigSendType" SG_ 736 BTInCallOptions_St 3;
BA_ "GenSigSendType" SG_ 722 VRM_ComShuffleTrack_St 3;
BA_ "GenSigSendType" SG_ 722 VRM_ComCompression_St 3;
BA_ "GenSigSendType" SG_ 722 VRM_ComStFreqMode_St 3;
BA_ "GenSigSendType" SG_ 722 VRM_ComAutostore_St 3;
BA_ "GenSigSendType" SG_ 722 VRM_ComBand_St 3;
BA_ "GenSigSendType" SG_ 722 VRM_TMCVoice 3;
BA_ "U_P708_MY2023_Rx" SG_ 722 VRM_NewSMS 1;
BA_ "U_V713AV_MY2022_Rx" SG_ 722 VRM_NewSMS 1;
BA_ "U_V713N_MY2022_Rx" SG_ 722 VRM_NewSMS 1;
BA_ "GenSigSendType" SG_ 722 VRM_NewSMS 3;
BA_ "GenSigSendType" SG_ 722 VRM_ComRSEDisplay_St 3;
BA_ "GenSigSendType" SG_ 722 VRM_ComPresetCall_St 3;
BA_ "GenSigSendType" SG_ 722 VRM_ComTape_St 3;
BA_ "GenSigSendType" SG_ 722 VRM_ComShuffleDiscs_St 3;
BA_ "GenSigSendType" SG_ 722 VRM_ComDolbyNR_St 3;
BA_ "GenSigSendType" SG_ 722 VRM_ComSourceSelect_St 3;
BA_ "GenSigSendType" SG_ 722 VRM_ComRouteStrategy_St 3;
BA_ "U_P708_MY2023_Rx" SG_ 721 VRM_BTDefaultPhone_St 1;
BA_ "U_V713AV_MY2022_Rx" SG_ 721 VRM_BTDefaultPhone_St 1;
BA_ "U_V713N_MY2022_Rx" SG_ 721 VRM_BTDefaultPhone_St 1;
BA_ "GenSigSendType" SG_ 721 VRM_BTDefaultPhone_St 3;
BA_ "GenSigSendType" SG_ 721 VRM_DetourUnit_st 3;
BA_ "GenSigSendType" SG_ 721 VRM_Zoom_Option_St 3;
BA_ "GenSigSendType" SG_ 721 VRM_ComBTDTMFTone_St 3;
BA_ "GenSigSendType" SG_ 721 VRM_SuggestedRoute_St 3;
BA_ "GenSigSendType" SG_ 721 VRM_ComDelWaypoint_St 3;
BA_ "GenSigSendType" SG_ 721 VRM_ComSelectDisc_St 3;
BA_ "GenSigSendType" SG_ 721 VRM_ComTelService_St 3;
BA_ "GenSigSendType" SG_ 721 VRM_ComDestHome_St 3;
BA_ "GenSigSendType" SG_ 721 VRM_ComShowNavInfo_St 3;
BA_ "U_P708_MY2023_Rx" SG_ 721 VRM_VoiceRecStatus_St 1;
BA_ "GenSigSendType" SG_ 721 VRM_VoiceRecStatus_St 3;
BA_ "GenSigSendType" SG_ 721 VRM_ComSelTrackSource_St 3;
BA_ "GenSigSendType" SG_ 721 VRM_ComDetour_St 3;
BA_ "GenSigSendType" SG_ 721 VRM_ComDisplay_St 3;
BA_ "GenSigSendType" SG_ 721 VRM_ComDynamicGuidande_St 3;
BA_ "GenSigSendType" SG_ 721 VRM_ComZoom_St 3;
BA_ "GenSigSendType" SG_ 721 VRM_ComCallControl_St 3;
BA_ "GenSigSendType" SG_ 721 VRM_ComGuidance_St 3;
BA_ "GenSigSendType" SG_ 721 VRM_ComTrafficInfDsp_St 3;
BA_ "U_P708_MY2023_Rx" SG_ 720 VRM_PhMicrophoneMute_St 1;
BA_ "U_V713AV_MY2022_Rx" SG_ 720 VRM_PhMicrophoneMute_St 1;
BA_ "U_V713N_MY2022_Rx" SG_ 720 VRM_PhMicrophoneMute_St 1;
BA_ "GenSigSendType" SG_ 720 VRM_PhMicrophoneMute_St 3;
BA_ "GenSigSendType" SG_ 720 Aioc_ExtSrcOutpMode_St 3;
BA_ "U_V710_MY2023_Rx" SG_ 720 VRM_BTPhoneSts_St 1;
BA_ "U_V713AV_MY2022_Rx" SG_ 720 VRM_BTPhoneSts_St 1;
BA_ "U_V713N_MY2022_Rx" SG_ 720 VRM_BTPhoneSts_St 1;
BA_ "ECGUsedRxSignal" SG_ 720 VRM_BTPhoneSts_St 1;
BA_ "U_P708_MY2023_Rx" SG_ 720 VRM_BTPhoneSts_St 1;
BA_ "GenSigSendType" SG_ 720 VRM_BTPhoneSts_St 3;
BA_ "GenSigSendType" SG_ 720 VRM_SubscribeStatus_St 3;
BA_ "U_P708_MY2023_Rx" SG_ 720 VRM_BlutoothStatus_St 1;
BA_ "U_V713AV_MY2022_Rx" SG_ 720 VRM_BlutoothStatus_St 1;
BA_ "U_V713N_MY2022_Rx" SG_ 720 VRM_BlutoothStatus_St 1;
BA_ "GenSigSendType" SG_ 720 VRM_BlutoothStatus_St 3;
BA_ "GenSigSendType" SG_ 720 VRM_BondRequest_St 3;
BA_ "GenSigSendType" SG_ 720 VRM_VRMMonoOutMode_St 3;
BA_ "U_P708_MY2023_Rx" SG_ 720 VRM_BTNetworkStatus_St 1;
BA_ "U_V713AV_MY2022_Rx" SG_ 720 VRM_BTNetworkStatus_St 1;
BA_ "U_V713N_MY2022_Rx" SG_ 720 VRM_BTNetworkStatus_St 1;
BA_ "GenSigSendType" SG_ 720 VRM_BTNetworkStatus_St 3;
BA_ "U_P708_MY2023_Rx" SG_ 720 VRM_BTSignalStrength_St 1;
BA_ "U_V713AV_MY2022_Rx" SG_ 720 VRM_BTSignalStrength_St 1;
BA_ "U_V713N_MY2022_Rx" SG_ 720 VRM_BTSignalStrength_St 1;
BA_ "GenSigSendType" SG_ 720 VRM_BTSignalStrength_St 3;
BA_ "U_P708_MY2023_Rx" SG_ 720 VRM_BTBatteryLevel_St 1;
BA_ "U_V713AV_MY2022_Rx" SG_ 720 VRM_BTBatteryLevel_St 1;
BA_ "U_V713N_MY2022_Rx" SG_ 720 VRM_BTBatteryLevel_St 1;
BA_ "GenSigSendType" SG_ 720 VRM_BTBatteryLevel_St 3;
BA_ "GenSigSendType" SG_ 470 VRM_BTActFeatDevInd_Rsp 3;
BA_ "GenSigSendType" SG_ 470 VRM_BTDebondDevice_Rsp 3;
BA_ "GenSigSendType" SG_ 470 VR_StartPhoneVR_Rsp 3;
BA_ "GenSigSendType" SG_ 470 VRM_DebondPhone_Rsp 3;
BA_ "GenSigSendType" SG_ 470 VRM_BTSendDTMFTone_Rsp 3;
BA_ "GenSigSendType" SG_ 470 VRM_SetDefaultPhone_Rsp 3;
BA_ "GenSigSendType" SG_ 470 VRM_DeleteNameTag_Rsp 3;
BA_ "GenSigSendType" SG_ 470 VRM_PlayNametag_Rsp 3;
BA_ "GenSigSendType" SG_ 470 VRM_SynchNavNameTag_Rsp 3;
BA_ "U_P708_MY2023_Rx" SG_ 470 VRM_BTIncomingCall_Rsp 1;
BA_ "U_V713AV_MY2022_Rx" SG_ 470 VRM_BTIncomingCall_Rsp 1;
BA_ "U_V713N_MY2022_Rx" SG_ 470 VRM_BTIncomingCall_Rsp 1;
BA_ "GenSigSendType" SG_ 470 VRM_BTIncomingCall_Rsp 3;
BA_ "U_P708_MY2023_Rx" SG_ 470 VRM_BTEndTelService_Rsp 1;
BA_ "U_V713AV_MY2022_Rx" SG_ 470 VRM_BTEndTelService_Rsp 1;
BA_ "U_V713N_MY2022_Rx" SG_ 470 VRM_BTEndTelService_Rsp 1;
BA_ "GenSigSendType" SG_ 470 VRM_BTEndTelService_Rsp 3;
BA_ "U_P708_MY2023_Tx" SG_ 1978 TesterPhysicalResHUD_ADV 1;
BA_ "GenSigSendType" SG_ 1978 TesterPhysicalResHUD_ADV 3;
BA_ "U_P708_MY2023_Rx" SG_ 1970 TesterPhysicalReqHUD_ADV 1;
BA_ "GenSigSendType" SG_ 1970 TesterPhysicalReqHUD_ADV 3;
BA_ "U_V710_MY2023_Tx" SG_ 758 SDARS_OpMode_St 1;
BA_ "U_P708_MY2023_Tx" SG_ 758 SDARS_OpMode_St 1;
BA_ "U_V713AV_MY2022_Tx" SG_ 758 SDARS_OpMode_St 1;
BA_ "U_V713N_MY2022_Tx" SG_ 758 SDARS_OpMode_St 1;
BA_ "U_V713AV_MY2022_Rx" SG_ 758 SDARS_OpMode_St 1;
BA_ "U_V713N_MY2022_Rx" SG_ 758 SDARS_OpMode_St 1;
BA_ "GenSigSendType" SG_ 758 SDARS_OpMode_St 3;
BA_ "U_V710_MY2023_Tx" SG_ 758 SDARS_SetCategory_St 1;
BA_ "U_P708_MY2023_Tx" SG_ 758 SDARS_SetCategory_St 1;
BA_ "U_V713AV_MY2022_Tx" SG_ 758 SDARS_SetCategory_St 1;
BA_ "U_V713N_MY2022_Tx" SG_ 758 SDARS_SetCategory_St 1;
BA_ "U_V713AV_MY2022_Rx" SG_ 758 SDARS_SetCategory_St 1;
BA_ "U_V713N_MY2022_Rx" SG_ 758 SDARS_SetCategory_St 1;
BA_ "GenSigSendType" SG_ 758 SDARS_SetCategory_St 3;
BA_ "U_V710_MY2023_Tx" SG_ 758 SDARS_GCI_Update_Prg_St 1;
BA_ "U_P708_MY2023_Tx" SG_ 758 SDARS_GCI_Update_Prg_St 1;
BA_ "U_V713AV_MY2022_Tx" SG_ 758 SDARS_GCI_Update_Prg_St 1;
BA_ "U_V713N_MY2022_Tx" SG_ 758 SDARS_GCI_Update_Prg_St 1;
BA_ "U_V713AV_MY2022_Rx" SG_ 758 SDARS_GCI_Update_Prg_St 1;
BA_ "U_V713N_MY2022_Rx" SG_ 758 SDARS_GCI_Update_Prg_St 1;
BA_ "GenSigSendType" SG_ 758 SDARS_GCI_Update_Prg_St 3;
BA_ "U_V710_MY2023_Tx" SG_ 758 SDARS_Factory_Reset_St 1;
BA_ "U_P708_MY2023_Tx" SG_ 758 SDARS_Factory_Reset_St 1;
BA_ "U_V713AV_MY2022_Tx" SG_ 758 SDARS_Factory_Reset_St 1;
BA_ "U_V713N_MY2022_Tx" SG_ 758 SDARS_Factory_Reset_St 1;
BA_ "U_V713AV_MY2022_Rx" SG_ 758 SDARS_Factory_Reset_St 1;
BA_ "U_V713N_MY2022_Rx" SG_ 758 SDARS_Factory_Reset_St 1;
BA_ "GenSigSendType" SG_ 758 SDARS_Factory_Reset_St 3;
VAL_ 413 LBS1_ListStatus 0 "Inactive" 1 "Valid" 2 "Updating" 3 "Reserved" ;
VAL_ 898 VedsPrmDirOfF_An_Ltchd 255 "Faulty" 254 "Not Supported" 0 "No Event" ;
VAL_ 898 VedsRoll_An_Ltchd 8191 "Faulty" 8190 "Not Supported" 0 "No Event" ;
VAL_ 898 SecondRowBcklPsngrMid 3 "Unknown" 2 "Unbelted" 1 "Belted" 0 "Faulty" ;
VAL_ 898 SecondRowBuckleDrvMid 3 "Unknown" 2 "Unbelted" 1 "Belted" 0 "Faulty" ;
VAL_ 898 FourthRowBucklePsngr 3 "Unknown" 2 "Unbelted" 1 "Belted" 0 "Faulty" ;
VAL_ 898 FourthRowBuckleMid 3 "Unknown" 2 "Unbelted" 1 "Belted" 0 "Faulty" ;
VAL_ 898 FourthRowBuckleDriver 3 "Unknown" 2 "Unbelted" 1 "Belted" 0 "Faulty" ;
VAL_ 898 Row3PsngrPrsnc_D_Actl 3 "Unknown" 2 "Empty" 1 "Occupied" 0 "Fault" ;
VAL_ 898 Row3MidPrsnc_D_Actl 3 "Unknown" 2 "Empty" 1 "Occupied" 0 "Fault" ;
VAL_ 898 Row3DrvPrsnc_D_Actl 3 "Unknown" 2 "Empty" 1 "Occupied" 0 "Fault" ;
VAL_ 898 Row2PsngrPrsnc_D_Actl 3 "Unknown" 2 "Empty" 1 "Occupied" 0 "Fault" ;
VAL_ 898 Row2MidPrsnc_D_Actl 3 "Unknown" 2 "Empty" 1 "Occupied" 0 "Fault" ;
VAL_ 898 Row2DrvPrsnc_D_Actl 3 "Unknown" 2 "Empty" 1 "Occupied" 0 "Fault" ;
VAL_ 1020 CtrStkPersIndex2_D_Actl 7 "Unused_3" 6 "Unused_2" 5 "Unused_1" 4 "Vehicle" 3 "PERS_4" 2 "PERS_3" 1 "PERS_2" 0 "PERS_1" ;
VAL_ 1020 CtrStkDsplyOp2_D_Rq 7 "Unused_2" 6 "Unused_1" 5 "Copy" 4 "Restore" 3 "Upload" 2 "Set" 1 "Query" 0 "Null" ;
VAL_ 1007 PersIndexIpc2_D_Actl 7 "Unused_3" 6 "Unused_2" 5 "Unused_1" 4 "Vehicle" 3 "PERS_4" 2 "PERS_3" 1 "PERS_2" 0 "PERS_1" ;
VAL_ 1217 SldrrStat_B_Actl 1 "Ajar" 0 "Closed" ;
VAL_ 1217 SldrrMsgTxt_D2_Rq 7 "NotUsed_3" 6 "NotUsed_2" 5 "NotUsed_1" 4 "SlidingDrCalibNeeded2" 3 "SlidingDrOpenCltchReleased" 2 "SlidingDrCalibNeeded" 1 "SlidingDrClutchReleased" 0 "Null" ;
VAL_ 1217 SldrrChime_D_Rq 7 "NotUsed3" 6 "NotUsed2" 5 "NotUsed1" 4 "Warning" 3 "WarningRepeated" 2 "Programming" 1 "Operation" 0 "Off" ;
VAL_ 1217 PwStepRight_D_Rq 1 "Deploy" 0 "Null" 3 "NotUsed" 2 "Stow" ;
VAL_ 1217 SldrrUnlckSwtch_D_Stat 3 "InnerHandle" 2 "RearInteriorSwitch" 1 "IpSwitch" 0 "Null" ;
VAL_ 1217 Sldrr_D_Stat 3 "NotCalibrated" 2 "Closing" 1 "Opening" 0 "NotMoving" ;
VAL_ 1216 SldrlStat_B_Actl 1 "Ajar" 0 "Closed" ;
VAL_ 1216 SldrlMsgTxt_D2_Rq 7 "NotUsed_3" 6 "NotUsed_2" 5 "NotUsed_1" 4 "SlidingDrCalibNeeded2" 3 "SlidingDrOpenCltchReleased" 2 "SlidingDrCalibNeeded" 1 "SlidingDrClutchReleased" 0 "Null" ;
VAL_ 1216 SldrlChime_D_Rq 7 "NotUsed3" 6 "NotUsed2" 5 "NotUsed1" 4 "Warning" 3 "WarningRepeated" 2 "Programming" 1 "Operation" 0 "Off" ;
VAL_ 1216 PwStepLeft_D_Rq 1 "Deploy" 0 "Null" 3 "NotUsed" 2 "Stow" ;
VAL_ 1216 SldrlUnlckSwtch_D_Stat 3 "InnerHandle" 2 "RearInteriorSwitch" 1 "IpSwitch" 0 "Null" ;
VAL_ 1216 Sldrl_D_Stat 3 "NotCalibrated" 2 "Closing" 1 "Opening" 0 "NotMoving" ;
VAL_ 820 AhbStatGfhbFdbk_D_Actl 3 "GfhbHighBeamFullyOn" 2 "GfhbHighBeamPartlyOn" 1 "GfhbHighBeamOff" 0 "GfhbUnavailable" ;
VAL_ 820 TurnLampFrOut_B_Stat 1 "Out" 0 "Null" ;
VAL_ 820 TurnLampFlOut_B_Stat 1 "Out" 0 "Null" ;
VAL_ 820 HeadLghtDrvSide_B_Stat 1 "Left_Hand_Traffic" 0 "Right_Hand_Traffic" ;
VAL_ 820 HeadLghtHiOn_B_StatHcm 1 "On" 0 "Off" ;
VAL_ 820 Adaptive_Hdlmp_Fault 1 "Yes" 0 "No" ;
VAL_ 1247 TrlrBrkCtl3_B_Falt 1 "True" 0 "False" ;
VAL_ 1247 StopLamp_B_RqTrlrAft 1 "True" 0 "False" ;
VAL_ 677 SeatFnPsgr_D_Rq3 7 "CushionMassage" 6 "LumbarMassage" 5 "UpperBolster" 4 "LowerBolster" 3 "UpperLumbar" 2 "MiddleLumbar" 1 "LowerLumbar" 0 "Null" ;
VAL_ 677 SeatFnDrv_D_Rq3 7 "CushionMassage" 6 "LumbarMassage" 5 "UpperBolster" 4 "LowerBolster" 3 "UpperLumbar" 2 "MiddleLumbar" 1 "LowerLumbar" 0 "Null" ;
VAL_ 677 SeatMasgPsngrRr_D_Rq2 15 "NotUsed_10" 14 "NotUsed_9" 13 "NotUsed_8" 12 "NotUsed_7" 11 "NotUsed_6" 10 "Pattern10" 9 "Pattern9" 8 "Pattern8" 7 "Pattern7" 6 "Pattern6" 5 "Pattern5" 4 "Pattern4" 3 "Pattern3" 2 "Pattern2" 1 "Pattern1" 0 "Null" ;
VAL_ 677 SeatMasgDrvRr_D_Rq2 15 "NotUsed_10" 14 "NotUsed_9" 13 "NotUsed_8" 12 "NotUsed_7" 11 "NotUsed_6" 10 "Pattern10" 9 "Pattern9" 8 "Pattern8" 7 "Pattern7" 6 "Pattern6" 5 "Pattern5" 4 "Pattern4" 3 "Pattern3" 2 "Pattern2" 1 "Pattern1" 0 "Null" ;
VAL_ 677 SeatFnChngPsgr2_D_Rq3 15 "Faulty" 14 "NotUsed9" 13 "NotUsed8" 12 "NotUsed7" 11 "NotUsed6" 10 "High_2" 9 "Med_2" 8 "Low_2" 7 "Off_2" 6 "High" 5 "Low" 4 "Off" 3 "Decrease" 2 "Increase" 1 "NotUsed1" 0 "Inactive" ;
VAL_ 677 SeatFnChngDrv2_D_Rq3 15 "Faulty" 14 "NotUsed9" 13 "NotUsed8" 12 "NotUsed7" 11 "NotUsed6" 10 "High_2" 9 "Med_2" 8 "Low_2" 7 "Off_2" 6 "High" 5 "Low" 4 "Off" 3 "Decrease" 2 "Increase" 1 "NotUsed1" 0 "Inactive" ;
VAL_ 582 PtLatchActv_B_RqBcm 1 "On" 0 "Off" ;
VAL_ 582 immoSecureIdleMode 3 "NotUsed2" 2 "NotUsed1" 1 "Active" 0 "Inactive" ;
VAL_ 582 ReFuelSwtchStat_D_Actl 3 "NotUsed2" 2 "NotUsed1" 1 "On" 0 "Off" ;
VAL_ 582 FuelPumpPwr_D_Stat 7 "NotUsed3" 6 "NotUsed2" 5 "NotUsed1" 4 "Power_Off_Default" 3 "Power_Off_Command" 2 "Power_Off_Service" 1 "Power_Off_Impact" 0 "Power_On" ;
VAL_ 582 BattULo_U_Actl 255 "Fault" ;
VAL_ 582 PrkLckCtl_B_Enbl 1 "Enable" 0 "Disable" ;
VAL_ 582 PrkLckCtlMsgTxt_D_Rq 3 "BTSI_DI_3" 2 "BTSI_DI_2" 1 "BTSI_DI_1" 0 "Null_BTSI_DI" ;
VAL_ 582 BrkTrnShifLck_B_Stat 1 "Shift" 0 "NoShift" ;
VAL_ 582 PrkLckCtlUnlck_D_Stat 3 "Trans_And_Steer_Unlckd" 2 "Steering_Unlckd" 1 "Transmission_Unlckd" 0 "Null" ;
VAL_ 582 PrkLckCtlTow_B_Enbl 1 "Enable" 0 "Disable" ;
VAL_ 582 DriverCrankingReq 1 "Crank_Request" 0 "No_Crank_Request" ;
VAL_ 582 EngOff_T_Actl 65535 "Invalid" ;
VAL_ 582 DcacElPw_D_Rq 3 "NotUsed" 2 "AC_HighPower_Requested" 1 "AC_LowPower_Requested" 0 "AC_Power_NotRequested" ;
VAL_ 582 BattULo_I_Actl 16383 "Fault" ;
VAL_ 1036 PdstrnAlrt_B_Falt 1 "Yes" 0 "No" ;
VAL_ 1047 TrlrAidSetup_D2_Stat 7 "NotUsed_2" 6 "NotUsed_1" 5 "SetupAcquisitionSuccess" 4 "TbaTadMonitor" 3 "SetupStartAcquisition" 2 "SetupPrepForAcquisition" 1 "TbaActive" 0 "Null" ;
VAL_ 1047 TrlrAidEnbl_D2_Stat 7 "NotUsed_1" 6 "TbaActiveExpertActive" 5 "TbaActiveExpertAvail" 4 "TbaOffTrgActive" 3 "TbaOffTrgSetup" 2 "TbaSetup" 1 "TbaActive" 0 "Inactive" ;
VAL_ 1047 TrlrAidMsgTxt_D2_Rq 63 "Message63" 62 "Message62" 61 "Message61" 60 "Message60" 55 "Message55" 50 "Message50" 45 "Message45" 40 "Message40" 35 "Message35" 31 "Message31" 30 "Message30" 29 "Message29" 28 "Message28" 27 "Message27" 26 "Message26" 25 "Message25" 24 "Message24" 23 "Message23" 22 "Message22" 21 "Message21" 20 "Message20" 19 "Message19" 18 "Message18" 17 "Message17" 16 "Message16" 15 "Message15" 14 "Message14" 13 "Message13" 12 "Message12" 11 "Message11" 10 "Message10" 9 "Message9" 8 "Message8" 7 "Message7" 6 "Message6" 5 "Message5" 4 "Message4" 3 "Message3" 2 "Message2" 1 "Message1" 0 "NoMessage" ;
VAL_ 1047 EsaOn_B_Stat 1 "On" 0 "Off" ;
VAL_ 1047 SelDrvMdeSte_D_Stat 0 "NotAvailable" 1 "Available" 2 "TemporarilyNotAvailable" 3 "Faulty" ;
VAL_ 1236 ApaSlotRight3_D_Stat 7 "NotUsed_3" 6 "NotUsed_2" 5 "NotUsed_1" 4 "IPeReady" 3 "IPeFound" 2 "IPaReady" 1 "IPaFound" 0 "None" ;
VAL_ 1236 ApaSlotRight3_B_Altr 1 "Available" 0 "NotAvailable" ;
VAL_ 1236 ApaSlotRight2_D_Stat 7 "NotUsed_3" 6 "NotUsed_2" 5 "NotUsed_1" 4 "IPeReady" 3 "IPeFound" 2 "IPaReady" 1 "IPaFound" 0 "None" ;
VAL_ 1236 ApaSlotRight2_B_Altr 1 "Available" 0 "NotAvailable" ;
VAL_ 1236 ApaSlotRight1_D_Stat 7 "NotUsed_3" 6 "NotUsed_2" 5 "NotUsed_1" 4 "IPeReady" 3 "IPeFound" 2 "IPaReady" 1 "IPaFound" 0 "None" ;
VAL_ 1236 ApaSlotRight1_B_Altr 1 "Available" 0 "NotAvailable" ;
VAL_ 1236 ApaSlotRear_D_Stat 1 "True" 0 "False" ;
VAL_ 1235 ApaSlotFront_D_Stat 1 "True" 0 "False" ;
VAL_ 1235 ApaSlotLeft3_D_Stat 7 "NotUsed_3" 6 "NotUsed_2" 5 "NotUsed_1" 4 "IPeReady" 3 "IPeFound" 2 "IPaReady" 1 "IPaFound" 0 "None" ;
VAL_ 1235 ApaSlotLeft3_B_Altr 1 "Available" 0 "NotAvailable" ;
VAL_ 1235 ApaSlotLeft2_D_Stat 7 "NotUsed_3" 6 "NotUsed_2" 5 "NotUsed_1" 4 "IPeReady" 3 "IPeFound" 2 "IPaReady" 1 "IPaFound" 0 "None" ;
VAL_ 1235 ApaSlotLeft2_B_Altr 1 "Unavailable" 0 "Available" ;
VAL_ 1235 ApaSlotLeft1_D_Stat 7 "NotUsed_3" 6 "NotUsed_2" 5 "NotUsed_1" 4 "IPeReady" 3 "IPeFound" 2 "IPaReady" 1 "IPaFound" 0 "None" ;
VAL_ 1235 ApaSlotLeft1_B_Altr 1 "Unavailable" 0 "Available" ;
VAL_ 841 FohAddHeater_D_Stat 3 "NotUsed" 2 "On" 1 "Off" 0 "NoModeSelected" ;
VAL_ 1189 SeatDfaltPosFront_B_Stat 1 "Yes" 0 "No" ;
VAL_ 1189 PwStepMsgTxt_D_Rq 1 "DriveInhibited" 0 "NoMessage" 3 "NotUsed" 2 "Malfunction" ;
VAL_ 1189 Running_Board_Stat 3 "Unused" 2 "Manually_Deployed" 1 "All_Enabled" 0 "All_Disabled" ;
VAL_ 1189 PwStep_D_Stat 3 "PositionNotKnown" 2 "StepsNotStowed" 1 "StepsStowed" 0 "Off" ;
VAL_ 772 SeatRelxPosDact_B_Stat 1 "Success" 0 "Fail" ;
VAL_ 772 SeatRelxPosActv_B_Stat 1 "Success" 0 "Fail" ;
VAL_ 772 SeatRelxPosSet_B_Stat 1 "Success" 0 "Fail" ;
VAL_ 772 SeatScrnDrvOn_B_Rq 1 "On" 0 "Off" ;
VAL_ 772 PwRnngBoardT_D_Stat 3 "NotUsed" 2 "Timer2" 1 "Timer1" 0 "Inactive" ;
VAL_ 772 PwRnngBoardSwtch_D_Stat 3 "NotUsed" 2 "DeployUnlocked" 1 "AlwaysActive" 0 "Inactive" ;
VAL_ 772 SeatSlprPosPsngr_D_Stat 3 "Faulty" 2 "Sleeper" 1 "Upright" 0 "Null" ;
VAL_ 772 SeatSlprPosMsgTxt_B_Rq 1 "On" 0 "Off" ;
VAL_ 772 SeatPos_D_Stat 7 "NotUsed3" 6 "NotUsed2" 5 "Error" 4 "Drive" 3 "Moving" 2 "Pending" 1 "EasyEntry" 0 "Null" ;
VAL_ 772 MemDrvDeny_B_Stat 1 "Yes" 0 "No" ;
VAL_ 772 Memory_Feedback_Rqst 1 "Yes" 0 "No" ;
VAL_ 772 Easy_Entry_Rqst 2 "Easy_Entry" 1 "Drive" 0 "Null" ;
VAL_ 772 Memory_Cmd 7 "Recall_3" 4 "Store_4" 3 "Store_3" 6 "Recall_2" 5 "Recall_1" 2 "Store_2" 1 "Store_1" 0 "Null" 8 "Recall_4" ;
VAL_ 772 Cancel_Auto_Movement 1 "Cancel" 0 "Null" ;
VAL_ 1054 SelDrvMdeChassis3_D_Rq 31 "Faulty" 30 "NotUsed17" 29 "NotUsed16" 28 "NotUsed15" 27 "NotUsed14" 26 "NotUsed13" 25 "NotUsed12" 24 "NotUsed11" 23 "NotUsed10" 22 "NotUsed9" 21 "NotUsed8" 20 "NotUsed7" 19 "NotUsed6" 18 "NotUsed5" 17 "NotUsed4" 16 "OnePedalDrive" 15 "DragMode" 14 "RoughRoadMode" 13 "TrackMode" 12 "HighSpeedDesertMode" 11 "TowHaulMode" 10 "RockCrawlMode" 9 "SandMode" 8 "MudAndRutsMode" 7 "LowMuMode" 6 "ComfortAdaptiveMode" 5 "ComfortMode" 4 "SportAdaptiveMode" 3 "SportMode" 2 "EconomyMode" 1 "NormalAdaptiveMode" 0 "NormalMode" ;
VAL_ 1054 RbaBrk_D_Stat 3 "Denied" 2 "Active" 1 "Open" 0 "Closed" ;
VAL_ 1054 SelDrvMdeChassis2_D_Rq 31 "Faulty" 30 "NotUsed17" 29 "NotUsed16" 28 "NotUsed15" 27 "NotUsed14" 26 "NotUsed13" 25 "NotUsed12" 24 "NotUsed11" 23 "NotUsed10" 22 "NotUsed9" 21 "NotUsed8" 20 "NotUsed7" 19 "NotUsed6" 18 "NotUsed5" 17 "NotUsed4" 16 "OnePedalDrive" 15 "DragMode" 14 "RoughRoadMode" 13 "TrackMode" 12 "HighSpeedDesertMode" 11 "TowHaulMode" 10 "RockCrawlMode" 9 "SandMode" 8 "MudAndRutsMode" 7 "LowMuMode" 6 "ComfortAdaptiveMode" 5 "ComfortMode" 4 "SportAdaptiveMode" 3 "SportMode" 2 "EconomyMode" 1 "NormalAdaptiveMode" 0 "NormalMode" ;
VAL_ 1054 BrkBstrLoLampOn_B_Rq 1 "On" 0 "Off" ;
VAL_ 1054 TrailCtl_D_Stat 7 "Faulty" 6 "DescentOnly" 5 "EnabledDeny" 4 "StandbyOverThreshold" 3 "StandbyOverride" 2 "Active" 1 "EnabledDescent" 0 "Off" ;
VAL_ 1054 TrailCtlMsgTxt_D_Rq 15 "Message15" 14 "Message14" 13 "Message13" 12 "Message12" 11 "Message11" 10 "Message10" 9 "Message9" 8 "Message8" 7 "Message7" 6 "Message6" 5 "Message5" 4 "Message4" 3 "Message3" 2 "Message2" 1 "Message1" 0 "NoMessage" ;
VAL_ 1054 BrkPadMsgTxt_D_Rq 3 "Faulty" 2 "PadsOk" 1 "ReplacePads" 0 "Null" ;
VAL_ 1054 BrkBstrVac_D_Stat 3 "NotUsed" 2 "BoosterVacEstimator" 1 "BoosterVacSensor" 0 "NoBoosterVacuumMonitor" ;
VAL_ 1054 DrvSlipCtlOffLamp_D_Rq 3 "Fast_Flash" 2 "Slow_Flash" 1 "On" 0 "Off" ;
VAL_ 1054 DrvSlipCtlMdeMsg_D_Rq 31 "Message31" 30 "Message30" 29 "Message29" 28 "Message28" 27 "Message27" 26 "Message26" 25 "Message25" 24 "Message24" 23 "Message23" 22 "Message22" 21 "Message21" 20 "Message20" 19 "Message19" 18 "Message18" 17 "Message17" 16 "Message16" 15 "Message15" 14 "Message14" 13 "Message13" 12 "Message12" 11 "Message11" 10 "Message10" 9 "Message9" 8 "Message8" 7 "Message7" 6 "Message6" 5 "Message5" 4 "Message4" 3 "Message3" 2 "Message2" 1 "Message1" 0 "NoMessage" ;
VAL_ 1054 HdcOn_B_Ind 1 "On" 0 "Off" ;
VAL_ 1054 AutoHoldMsgTxt_D_Rq 15 "Message15" 14 "Message14" 13 "Message13" 12 "Message12" 11 "Message11" 10 "Message10" 9 "Message9" 8 "Message8" 7 "Message7" 6 "Message6" 5 "Message5" 4 "Message4" 3 "Message3" 2 "Message2" 1 "Message1" 0 "NoMessage" ;
VAL_ 1054 CtaBrk_D_Stat 3 "Denied" 2 "Active" 1 "Open" 0 "Closed" ;
VAL_ 1054 SelDrvMdeAwd_D_Rq 31 "Faulty" 30 "NotUsed_17" 29 "NotUsed_16" 28 "NotUsed_15" 27 "NotUsed_14" 26 "NotUsed_13" 25 "NotUsed_12" 24 "NotUsed_11" 23 "NotUsed_10" 22 "NotUsed_9" 21 "NotUsed_8" 20 "CustomMode" 19 "OnePedalDrive" 18 "DragMode" 17 "EvLaterChargeMode" 16 "EvNowMode" 15 "TrackMode" 14 "RoughRoadMode" 13 "NotAvailable" 12 "HighSpeedDesertMode_Baja" 11 "SportAdaptiveMode" 10 "RockCrawlMode" 9 "MudRutsMode" 8 "SandMode" 7 "EconomyMode" 6 "GrassGravelSnow" 5 "TowHaulMode" 4 "SportMode" 3 "Normal_4L" 2 "Normal_4A" 1 "Normal_2H" 0 "NormalMode" ;
VAL_ 1054 AutoHoldSwMde_B_Ind 1 "On" 0 "Off" ;
VAL_ 1054 AutoHoldMde_D_Ind 3 "Indication_3" 2 "Indication_2" 1 "Indication_1" 0 "Off" ;
VAL_ 1054 BrkMdeInhbt_B_RqDsply 1 "Yes" 0 "No" ;
VAL_ 1054 BrkLineLck_D_Stat 7 "NotUsed_3" 6 "NotUsed_2" 5 "NotUsed_1" 4 "NotAvailable" 3 "Off" 2 "Engaged" 1 "Initiated" 0 "Available" ;
VAL_ 1054 SelDrvMdeChassis_D_Rq 31 "Faulty" 30 "NotUsed17" 29 "NotUsed16" 28 "NotUsed15" 27 "NotUsed14" 26 "NotUsed13" 25 "NotUsed12" 24 "NotUsed11" 23 "NotUsed10" 22 "NotUsed9" 21 "NotUsed8" 20 "NotUsed7" 19 "NotUsed6" 18 "NotUsed5" 17 "NotUsed4" 16 "OnePedalDrive" 15 "DragMode" 14 "RoughRoadMode" 13 "TrackMode" 12 "HighSpeedDesertMode" 11 "TowHaulMode" 10 "RockCrawlMode" 9 "SandMode" 8 "MudAndRutsMode" 7 "LowMuMode" 6 "ComfortAdaptiveMode" 5 "ComfortMode" 4 "SportAdaptiveMode" 3 "SportMode" 2 "EconomyMode" 1 "NormalAdaptiveMode" 0 "NormalMode" ;
VAL_ 1054 ApaBrk_D_Stat 3 "Denied" 2 "Active" 1 "Open" 0 "Closed" ;
VAL_ 1054 FrontDiffElckrOpen_B_Rq 1 "Yes" 0 "No" ;
VAL_ 1054 OnePdlDrvDeny_B_Stat 1 "Yes" 0 "No" ;
VAL_ 1054 BrkDrvMde_D_Stat 7 "Faulty" 6 "RockCrawl" 5 "Baja" 4 "DragOrMudAndSand" 3 "Track" 2 "Snow_Wet" 1 "Sport" 0 "Normal" ;
VAL_ 1054 TrailOnePdlTqLm_B_Actl 1 "Yes" 0 "No" ;
VAL_ 572 BattTracClnt_Te_Actl 255 "Faulty" 254 "NoDataExists" ;
VAL_ 572 PwSrcULoMde_D_Actl 3 "BuckSpecial" 2 "ReverseBoost" 1 "ForwardBuck" 0 "Standby" ;
VAL_ 572 BattTracWarnLamp_B_Rq 1 "On" 0 "Off" ;
VAL_ 572 BattTracSrvcRqd_B_Rq 1 "On" 0 "Off" ;
VAL_ 561 TrnMsgTxt2_D_Rq 7 "NotUsed3" 6 "NotUsed2" 5 "NotUsed1" 4 "TransTooHot_LoudChime" 3 "PressBrake_LoudChime" 2 "PressBrake_SoftChime" 1 "PressBrake_NoChime" 0 "NoText_NoChime" ;
VAL_ 561 TrnMsgTxt_D_Rq 15 "Message_15" 14 "Message_14" 13 "Message_13" 12 "Message_12" 11 "Message_11" 10 "Message_10" 9 "Message_9" 8 "Message_8" 7 "Message_7" 6 "Message_6" 5 "Message_5" 4 "Message_4" 3 "Message_3" 2 "Message_2" 1 "Message_1" 0 "NoMessage" ;
VAL_ 602 HtrnWarnLamp_B_Dsply 1 "On" 0 "Off" ;
VAL_ 602 HybPwLimOn_B_Stat 1 "Yes" 0 "No" ;
VAL_ 602 PwSrcULoMde_D_Rq 3 "BuckSpecial" 2 "ReverseBoost" 1 "ForwardBuck" 0 "Standby" ;
VAL_ 602 PtcHtrRun_B_Rq 1 "On" 0 "Off" ;
VAL_ 602 PwPckTqRdy_B_Dsply 1 "On" 0 "Off" ;
VAL_ 602 ObdEngStdy_B_Stat 1 "Yes" 0 "No" ;
VAL_ 602 EngStrtSrvc_B_Allw 1 "Yes" 0 "No" ;
VAL_ 602 BattTracRsrvSoc_Pc_Rq 16383 "Faulty" 16382 "NoDataExists" ;
VAL_ 92 TrnGearMsgTxt2_D_Rq 31 "Message31" 30 "Message30" 29 "Message29" 28 "Message28" 27 "Message27" 26 "Message26" 25 "Message25" 24 "Message24" 23 "Message23" 22 "Message22" 21 "Message21" 20 "Message20" 19 "Message19" 18 "Message18" 17 "Message17" 16 "Message16" 15 "Message15" 14 "Message14" 13 "Message13" 12 "Message12" 11 "Message11" 10 "Message10" 9 "Message9" 8 "Message8" 7 "Message7" 6 "Message6" 5 "Message5" 4 "Message4" 3 "Message3" 2 "Message2" 1 "Message1" 0 "NoMessage" ;
VAL_ 92 RaceTrakMde_D_Stat 3 "NotUsed" 2 "Available" 1 "NotAvailable" 0 "Null" ;
VAL_ 92 TrnLvrV_D_Rq 3 "Full_Speed" 2 "Aggressive" 1 "Normal" 0 "Quiet" ;
VAL_ 92 TrnSbwSysHlth_D_Actl 3 "OK" 2 "Degraded" 1 "No_Data_Exists" 0 "Faulty" ;
VAL_ 92 TrnDtpCmd_D_Actl 7 "NotUsed4" 6 "NotUsed3" 5 "NotUsed2" 4 "Relatch" 3 "Deploy" 2 "Self_Test" 1 "No_Command" 0 "NotUsed1" ;
VAL_ 92 TrnGearNtmAllow_B_Stat 1 "Yes" 0 "No" ;
VAL_ 92 GearSelLck_D_Rq 3 "PreventionBlocker" 2 "Unlock" 1 "Lock" 0 "Null" ;
VAL_ 92 TrnValidGear_D_Cnfm 3 "Accept" 2 "Reject" 1 "Internal_Request" 0 "No_Command" ;
VAL_ 92 TrnNtrlTowCmd_D_Actl 3 "NotUsed" 2 "Neutral_Tow_Entry" 1 "Car_Wash_Mode" 0 "Normal_Mode" ;
VAL_ 92 TrnGearCmd_Pc_ActlPt 1023 "Fault" ;
VAL_ 92 TrnGear_D_RqPt 7 "Fault" 6 "NotUsed" 5 "Manual" 4 "Drive" 3 "Neutral" 2 "Reverse" 1 "Park" 0 "No_Gear" ;
VAL_ 92 TrnCmdState_B_Actl 1 "Yes" 0 "No" ;
VAL_ 92 PrkBrkActv_D_RqTrnGear 3 "NotUsed2" 2 "RequestParkBrakeEngage" 1 "NoRequest" 0 "NotUsed1" ;
VAL_ 92 TrnGearMsgTxt_D_Rq 15 "Message_15" 14 "Message_14" 13 "Message_13" 12 "Message_12" 11 "Message_11" 10 "Message_10" 9 "Message_9" 8 "Message_8" 7 "Message_7" 6 "Message_6" 5 "Message_5" 4 "Message_4" 3 "Message_3" 2 "Message_2" 1 "Message_1" 0 "NoMessage" ;
VAL_ 1156 RngPerChrgAvg_L2_Dsply 8191 "Faulty" 8190 "NoDataExists" ;
VAL_ 1156 VehElEffAvg_No_Dsply 127 "Faulty" 126 "NoDataExists" ;
VAL_ 1156 PwFlwFuelDrv_D_Dsply 7 "NotUsed_4" 6 "NotUsed_3" 5 "NotUsed_2" 4 "NotUsed_1" 3 "FlwFromFuelToAllWhls" 2 "FlwFromFuelToFrontWhls" 1 "FlwFromFuelToRearWhls" 0 "NoFlow" ;
VAL_ 1156 PwFlwFuelClimt_B_Dsply 1 "On" 0 "Off" ;
VAL_ 1156 PwFlwFuelBatt_B_Dsply 1 "On" 0 "Off" ;
VAL_ 1156 PwFlwBattGen_D_Dsply 1 "On" 0 "Off" ;
VAL_ 1156 PwFlwBattClimt_B_Dsply 1 "On" 0 "Off" ;
VAL_ 1156 PwFlwBatt_D_Dsply 15 "NotUsed_8" 14 "NotUsed_7" 13 "NotUsed_6" 12 "NotUsed_5" 11 "NotUsed_4" 10 "NotUsed_3" 9 "NotUsed_2" 8 "NotUsed_1" 7 "FlwFromWallToBatt" 6 "FlwFromAllWhlsToBatt" 5 "FlwFromBattToAllWhls" 4 "FlwFromFrontWhlsToBatt" 3 "FlwFromBattToFrontWhls" 2 "FlwFromRearWhlsToBatt" 1 "FlwFromBattToRearWhls" 0 "NoFlow" ;
VAL_ 357 BPedDrvAppl_D_Qf 3 "OK" 2 "Not_Within_Specifications" 1 "No_Data_Exists" 0 "Faulty" ;
VAL_ 357 CmbbDeny_B_ActlPrpl 1 "Yes" 0 "No" ;
VAL_ 357 PrplTqMnSat_B_Actl 1 "Yes" 0 "No" ;
VAL_ 357 VehStrtStop_D_Rq 3 "NotUsed" 2 "Vehicle_Start_Request" 1 "Vehicle_Stop_Request" 0 "NoRequest" ;
VAL_ 357 BpedDrvAppl_D_Actl 3 "_Not_Allowed" 2 "Driver_Braking" 1 "Driver_Not_Braking" 0 "Not_Allowed" ;
VAL_ 357 CmbbEngTqMn_B_Actl 1 "Yes" 0 "No" ;
VAL_ 357 Veh_V_DsplyCcSet 255 "Fault" 254 "Unknown" ;
VAL_ 357 AccEngStat_D_Actl 7 "Undefined_2" 6 "Undefined_1" 5 "ACCSoonCancel_due_Low_Spd" 4 "Shift_Down_Recommendation" 3 "Shift_Up_Recommendation" 2 "ACCNotAllowedToBeActivated" 1 "ACCStandby_due_Auto_Cancel" 0 "Normal_Operation" ;
VAL_ 357 CcMde_D_Actl 7 "TapDownWaiting" 6 "TapUpWaiting" 5 "Resuming_Low" 4 "Resuming_High" 3 "Decelerating" 2 "Accelerating" 1 "Keeping_Speed" 0 "Not_Active" ;
VAL_ 357 CcStat_D_Actl 7 "Undefined_2" 6 "Undefined_1" 5 "Active" 4 "Active_Que_Assist" 3 "Standby" 2 "Standby_Denied" 1 "Denied" 0 "Off" ;
VAL_ 357 CcOvrrdActv_B_Actl 1 "Cruise_Overridden" 0 "Cruise_Req_Not_Overridden" ;
VAL_ 357 AccStopMde_D_Rq 3 "Stop_Mode_Active" 2 "EPBApplyOrBrakeReleaseWarn" 1 "Limit_Rolling_Speed" 0 "Stop_Mode_Not_Active" ;
VAL_ 1100 RearDiffLckLamp_D_Rq2 3 "Triggered" 2 "Flash" 1 "On" 0 "Off" ;
VAL_ 1100 RvltnMatchAllw_D_Stat 3 "RevolutionMatchDisabled" 2 "RevolutionMatchEnabled" 1 "ChangeWithDriveMode" 0 "NoSelection" ;
VAL_ 1100 WakeAlarm1_B_Typ 1 "CanAndEcuDriveCircuit" 0 "CanOnly" ;
VAL_ 1100 TrnNtrlIdlExit_B_Rq 1 "Active" 0 "Inactive" ;
VAL_ 1100 Veh_V_DsplyTrailCtlSet 63 "Faulty" ;
VAL_ 1100 TrailCtlPt_B_Falt 1 "Fault" 0 "NoFault" ;
VAL_ 1100 TrnNtrlIdlInhbt_B_Rq 1 "Inhibit" 0 "NoInhibit" ;
VAL_ 1100 AutoTowAllw_D_StatMnu 3 "TowHaulCommandedOn" 2 "AutoTowHaulEnabled" 1 "AutoTowHaulDisabled" 0 "NoSelection" ;
VAL_ 1100 AutoTowActv_B_Stat 1 "Yes" 0 "No" ;
VAL_ 1100 SpareTireDetct_B_Stat 1 "True" 0 "False" ;
VAL_ 1100 RearDiffSumpOil_Te_Est 255 "Faulty" 254 "NoDataExists" ;
VAL_ 1100 RearDiffMtrRun_B_Stat 1 "Allowed" 0 "NotAllowed" ;
VAL_ 1100 EngTrlrCnnct_D_Stat 3 "NotUsed_1" 2 "UnverifiedTrailer" 1 "HeavyTrailer" 0 "NoTrailer" ;
VAL_ 1100 GrossTrainWeight_M_Est 255 "Faulty" 254 "NoDataExists" ;
VAL_ 1100 SuspVlimMsgTxt_B_Rq 1 "Yes" 0 "No" ;
VAL_ 1100 RearDiffLckMsg2_D_Rq 15 "NotUsed_3" 14 "NotUsed_2" 13 "NotUsed_1" 12 "ElsdReduced" 11 "LockingFeatureNotAvailable" 10 "EsldOff" 9 "ElsdRestored" 8 "ElsdOverheated" 7 "Locker_Disabled" 6 "Locker_Enabled" 5 "LockerSpeed5" 4 "LockerSpeed4" 3 "LockerSpeed3" 2 "LockerSpeed2" 1 "LockerSpeed1" 0 "NormalNoMessage " ;
VAL_ 1100 EngExhMdeQuiet_D2_Stat 7 "Faulty" 6 "NotUsed_2" 5 "NotUsed_1" 4 "Track" 3 "Sport" 2 "Normal" 1 "Stealth" 0 "Null" ;
VAL_ 1100 HvacCmprLim_D_Stat 7 "NotUsed_2" 6 "NotUsed_1" 5 "CompressorHeadPressure" 4 "AvailableTorque" 3 "PedalPosition" 2 "RPM" 1 "ECT" 0 "NoLimit" ;
VAL_ 1152 PwCabinEnblScnd_B_Rq 1 "Enable" 0 "Disable" ;
VAL_ 1152 PwCabinEnbl_B_Rq 1 "Enable" 0 "Disable" ;
VAL_ 1152 PwTrnkFrntEnblScnd_B_Rq 1 "Enable" 0 "Disable" ;
VAL_ 1152 PwTrnkFrntEnbl_B_Rq 1 "Enable" 0 "Disable" ;
VAL_ 1152 PwOutlet8EnblScnd_B_Rq 1 "Enable" 0 "Disable" ;
VAL_ 1152 PwOutlet8Enbl_B_Rq 1 "Enable" 0 "Disable" ;
VAL_ 1152 PwOutlet7EnblScnd_B_Rq 1 "Enable" 0 "Disable" ;
VAL_ 1152 PwOutlet7Enbl_B_Rq 1 "Enable" 0 "Disable" ;
VAL_ 1152 PwOutlet6EnblScnd_B_Rq 1 "Enable" 0 "Disable" ;
VAL_ 1152 PwOutlet6Enbl_B_Rq 1 "Enable" 0 "Disable" ;
VAL_ 1152 HybPwULoLamp_B_Rq 1 "On" 0 "Off" ;
VAL_ 1152 StopStrtVThres_D_Stat 3 "High" 2 "Medium" 1 "Low" 0 "NoSelection" ;
VAL_ 1152 GrdAsstActv_B_Stat 1 "On" 0 "Off" ;
VAL_ 1152 EngTeHi_B_Actl 1 "EngineTempHigh" 0 "Normal" ;
VAL_ 1152 DcdcOn_B_Rq 1 "On" 0 "Off" ;
VAL_ 1152 ULoBattSpprtSustn_B_Rq 1 "Active" 0 "Inactive" ;
VAL_ 1152 OnePdlDrv_D_Dsply 3 "Faulty" 2 "Suspended" 1 "On" 0 "Off" ;
VAL_ 1152 OnePdlDrvLamp_B_Rq 1 "On" 0 "Off" ;
VAL_ 1152 BattTracDiagClr_B_Stat 1 "On" 0 "Off" ;
VAL_ 1152 VehElEff_No_Avg 127 "Faulty" 126 "NoDataExists" ;
VAL_ 652 TelematicsSrvc_D_St2 7 "NotUsed_1" 6 "NotifyNotActivatedYet" 5 "NotActivatedYet" 4 "NotifyExpired" 3 "Expired" 2 "ExpiringSoon" 1 "Active" 0 "Null" ;
VAL_ 560 SelDrvMdeSwtch_D_Stat3 3 "Faulty" 2 "SwitchState2" 1 "SwitchState1" 0 "NotPressed" ;
VAL_ 560 TrnGbox_Rt_Actl 65535 "Fault" 65534 "Unknown" ;
VAL_ 560 TrnSrvcRqd_B_Rq 1 "On" 0 "Off" ;
VAL_ 560 TrnCnvtClu_D_Actl 3 "Transition_or_Micro_Slip" 2 "Lock_Up_Fixed" 1 "Lock_Up_Slip" 0 "No_Lock_Up" ;
VAL_ 560 TrnShifActv_B_Actl 1 "Active" 0 "Inactive" ;
VAL_ 560 RtmTerrMdeChng_D_Rdy 7 "Fault" 6 "Undefined_2" 5 "Undefined_1" 4 "ModeUnavailDrInputRqd" 3 "SpOpModes_NotSupported" 2 "ModeUnavailDynamicCond" 1 "Module_In_Initialization" 0 "Mode_Change_Available" ;
VAL_ 560 RtmTerrMde_D_Actl 7 "Fail_Safe_Default" 6 "Dynamic_Mode" 5 "Rock_Crawl_Mode" 4 "Mud_Ruts_Mode" 3 "Sand_Mode" 2 "Undefined" 1 "Low_Mu_Mode" 0 "Special_Operating_Mode_Off" ;
VAL_ 560 GearLvrPos_D_Actl 15 "Fault" 14 "Unknown_Position" 13 "Undefined_Treat_as__Fault" 12 "Undefined_Treat_as_Fault" 11 "sixth" 10 "fifth" 9 "fourth" 8 "third" 7 "second" 6 "first" 5 "Low" 4 "Sport_DriveSport" 3 "Drive" 2 "Neutral" 1 "Reverse" 0 "Park" ;
VAL_ 560 GboxOil_Te_Actl 255 "Faulty" 254 "NoDataExists" ;
VAL_ 1153 TerrStat_D_RqDsply 15 "Reserved4" 14 "Reserved3" 13 "Reserved2" 12 "Crawl_Mode_4LOW_Reqd" 11 "Economy_Mode_Select" 10 "ModeChangeNotAvailable" 9 "Terrain_Sys_Not_Avail" 8 "Terrain_System_Fault" 7 "Mode_Change_InProgress" 6 "Dynamics_Mode_Select" 5 "Rock_Crawl_Mode_Select" 4 "Sand_Mode_Select" 3 "Mud_Ruts_Mode_Select" 2 "Low_Mu_Mode_Select" 1 "Special_Modes_Off" 0 "No_Message" ;
VAL_ 1153 TerrMde_D_RqDrv 7 "Fail_Safe_Default" 6 "Dynamic_Mode" 5 "Rock_Crawl_Mode" 4 "Mud_Ruts_Mode" 3 "Sand_Mode" 2 "Undefined" 1 "Low_Mu_Mode" 0 "Special_Operating_Mode_Off" ;
VAL_ 930 BalrWndwRight_B_Stat 1 "Enable" 0 "Disable" ;
VAL_ 930 BalrSnsRight_D_Falt 3 "Invalid" 2 "SystemFailure" 1 "Blocked" 0 "Clear" ;
VAL_ 930 WndwPsngrRear_D_RqBalrr 3 "NotUsed" 2 "Stop" 1 "AutoUp" 0 "NoRequest" ;
VAL_ 930 WndwPsngr_D_RqBalrr 3 "NotUsed" 2 "Stop" 1 "AutoUp" 0 "NoRequest" ;
VAL_ 930 WndwDrvRear_D_RqBalrr 3 "NotUsed" 2 "Stop" 1 "AutoUp" 0 "NoRequest" ;
VAL_ 930 WndwDrv_D_RqBalrr 3 "NotUsed" 2 "Stop" 1 "AutoUp" 0 "NoRequest" ;
VAL_ 930 BalrRight_D_Stat 3 "Inhibited" 2 "Disabled" 1 "On" 0 "Off" ;
VAL_ 930 BalrMdeSelRight_B_Stat 1 "Enable" 0 "Disable" ;
VAL_ 930 BalrMdeRight_D_Stat 3 "NotUsed" 2 "High" 1 "Medium" 0 "Low" ;
VAL_ 930 BalrLckRight_B_Stat 1 "Enable" 0 "Disable" ;
VAL_ 930 BalrChimeRight_D_Rq 3 "NotUsed" 2 "Soft" 1 "Normal" 0 "Off" ;
VAL_ 930 CamraRearOn_B_RqBalrr 1 "Active" 0 "Inactive" ;
VAL_ 930 DrLckActv_B_RqBalrr 1 "Active" 0 "Null" ;
VAL_ 929 BalrChimeLeft_D_Rq 3 "NotUsed" 2 "Soft" 1 "Normal" 0 "Off" ;
VAL_ 929 BalrLeft_D_Stat 3 "Inhibited" 2 "Disabled" 1 "On" 0 "Off" ;
VAL_ 929 WndwPsngrRear_D_RqBalrl 3 "NotUsed" 2 "Stop" 1 "AutoUp" 0 "NoRequest" ;
VAL_ 929 WndwPsngr_D_RqBalrl 3 "NotUsed" 2 "Stop" 1 "AutoUp" 0 "NoRequest" ;
VAL_ 929 WndwDrvRear_D_RqBalrl 3 "NotUsed" 2 "Stop" 1 "AutoUp" 0 "NoRequest" ;
VAL_ 929 WndwDrv_D_RqBalrl 3 "NotUsed" 2 "Stop" 1 "AutoUp" 0 "NoRequest" ;
VAL_ 929 BalrSnsLeft_D_Falt 3 "Invalid" 2 "SystemFailure" 1 "Blocked" 0 "Clear" ;
VAL_ 929 BalrMdeSelLeft_B_Stat 1 "Enable" 0 "Disable" ;
VAL_ 929 BalrMdeLeft_D_Stat 3 "NotUsed" 2 "High" 1 "Medium" 0 "Low" ;
VAL_ 929 BalrLckLeft_B_Stat 1 "Enable" 0 "Disable" ;
VAL_ 929 CamraRearOn_B_RqBalrl 1 "Active" 0 "Inactive" ;
VAL_ 929 DrLckActv_B_RqBalrl 1 "Active" 0 "Null" ;
VAL_ 929 BalrWndwLeft_B_Stat 1 "Enable" 0 "Disable" ;
VAL_ 391 ACU_CtrlChimeChan_Rq 3 "Reserved2" 2 "Reserved1" 1 "Mute" 0 "Inactive" ;
VAL_ 670 DrHandleOuterRl_D_Stat 7 "NotUsed" 6 "Transition" 5 "FlushFault" 4 "DeployFault2" 3 "DeployFault1" 2 "Flush" 1 "Deploy" 0 "None" ;
VAL_ 670 DrHandleOuterFl_D_Stat 7 "NotUsed" 6 "Transition" 5 "FlushFault" 4 "DeployFault2" 3 "DeployFault1" 2 "Flush" 1 "Deploy" 0 "None" ;
VAL_ 672 Coding_BtnID_D 1 "Pressed" 0 "Not_Pressed" ;
VAL_ 672 Coding_BtnID_C 1 "Pressed" 0 "Not_Pressed" ;
VAL_ 672 Coding_BtnID_B 1 "Pressed" 0 "Not_Pressed" ;
VAL_ 672 Coding_BtnID_A 1 "Pressed" 0 "Not_Pressed" ;
VAL_ 672 BCP_Audible_Beep_Rq 1 "Active" 0 "Inactive" ;
VAL_ 1205 CstmDrvMdeCfg2_B_Avail 1 "Available" 0 "NotAvailable" ;
VAL_ 1205 CstmDrvMdeCfg1_B_Avail 1 "Available" 0 "NotAvailable" ;
VAL_ 1200 BrkRearPCorrltn_B_Stat 1 "Yes" 0 "No" ;
VAL_ 1200 HsaTrnAout_Tq_Rq 65535 "Fault" 65534 "Unknown" ;
VAL_ 1200 BrkBstrVac_P_Actl 127 "Invalid" ;
VAL_ 1200 YawStabilityIndex 511 "Fault" 510 "NoDataExists" ;
VAL_ 1200 BrkTot_Tq_RqDrv 8191 "Fault" ;
VAL_ 1200 BrkHold_D_Stat 7 "NotUsed_3" 6 "NotUsed_2" 5 "NotUsed_1" 4 "HeldSecondary" 3 "HeldSecure" 2 "Held" 1 "Inactive" 0 "Off" ;
VAL_ 1200 HsaStat_D_Dsply 7 "NotUsed3" 6 "NotUsed2" 5 "NotUsed1" 4 "NotAvailable" 3 "SlowReleaseWithChime" 2 "SlowReleaseWithoutChime" 1 "Active" 0 "Inactive" ;
VAL_ 1018 TrlrTireSensILM_D_Stat 15 "NotSupported" 14 "NotUsed10" 13 "NotUsed9" 12 "NotUsed8" 11 "NotUsed7" 10 "NotUsed6" 9 "NotUsed5" 8 "NotUsed4" 7 "NotUsed3" 6 "NotUsed2" 5 "NotUsed1" 4 "Alert" 3 "Fault" 2 "Low" 1 "Normal" 0 "Unknown" ;
VAL_ 1018 TrlrTireSensILF_D_Stat 15 "NotSupported" 14 "NotUsed10" 13 "NotUsed9" 12 "NotUsed8" 11 "NotUsed7" 10 "NotUsed6" 9 "NotUsed5" 8 "NotUsed4" 7 "NotUsed3" 6 "NotUsed2" 5 "NotUsed1" 4 "Alert" 3 "Fault" 2 "Low" 1 "Normal" 0 "Unknown" ;
VAL_ 1018 TrlrTireILR_P_Actl 65534 "Invalid" 65535 "NotSupported" ;
VAL_ 1018 TrlrTireILM_P_Actl 65534 "Invalid" 65535 "NotSupported" ;
VAL_ 1018 TrlrTireILF_P_Actl 65534 "Invalid" 65535 "NotSupported" ;
VAL_ 1018 TrlrTireSensILR_D_Stat 15 "NotSupported" 14 "NotUsed10" 13 "NotUsed9" 12 "NotUsed8" 11 "NotUsed7" 10 "NotUsed6" 9 "NotUsed5" 8 "NotUsed4" 7 "NotUsed3" 6 "NotUsed2" 5 "NotUsed1" 4 "Alert" 3 "Fault" 2 "Low" 1 "Normal" 0 "Unknown" ;
VAL_ 1238 TjaCanclMsgTxt_D_Dsply 15 "NotUsed_9" 14 "NotUsed_8" 13 "NotUsed_7" 12 "NotUsed_6" 11 "NotUsed_5" 10 "NotUsed_4" 9 "NotUsed_3" 8 "NotUsed_2" 7 "NotUsed_1" 6 "DriverNotSeen2" 5 "DriverNotSeen1" 4 "HandsFreeUnavailInThisArea" 3 "HandsFreeUnavailForMaxSpd" 2 "CancelledForLaneConditions" 1 "CancelledForRoadCurvature" 0 "NoMessage" ;
VAL_ 1238 GfhbMnu_D_Rq 3 "EnableADB" 2 "EnableGFHB" 1 "Disable" 0 "Null" ;
VAL_ 1238 AhbcMnu_D_Rq 3 "NotUsed" 2 "Enable" 1 "Disable" 0 "Null" ;
VAL_ 1238 TjaLaneBias_D_Stat 7 "NotUsed" 6 "ElBiasRight" 5 "ElBiasLeft" 4 "SystemBiasRight" 3 "SystemBiasLeft" 2 "ManualBiasRight" 1 "ManualBiasLeft" 0 "NoBias" ;
VAL_ 1238 TjaLaneBiasEnbl_D_Stat 3 "NotUsed" 0 "Inactive" 2 "Enable" 1 "Disable" ;
VAL_ 1238 IaccVAdjReas_D_Dsply 15 "NotUsed_21" 11 "NotUsed_1" 10 "SpeedSign" 9 "LeftRamp" 8 "RightRamp" 7 "Roundabout_CCW" 6 "Roundabout_CW" 5 "LeftCurve" 4 "RightCurve" 3 "LeftTurnIntersection" 2 "RightTurnIntersection" 1 "RoadGeometryUnavailable" 0 "NoDisplay" ;
VAL_ 766 McCntrStckNotfn_B_Stat 1 "On" 0 "Off" ;
VAL_ 766 McSelMsgId_B_Stat 1 "Valid" 0 "Invalid" ;
VAL_ 766 McSelChoice_D_Stat 7 "Choice7" 6 "Choice6" 5 "Choice5" 4 "Choice4" 3 "Choice3" 2 "Choice2" 1 "Choice1" 0 "Ok" ;
VAL_ 766 McPrsntMsgId_B_Stat 1 "Valid" 0 "Invalid" ;
VAL_ 766 McPrsntActv_D_Stat 7 "NotUsed_4" 6 "NotUsed_3" 5 "NotUsed_2" 4 "NotUsed_1" 3 "Deactivated" 2 "UpdateGranted" 1 "ActiveGranted" 0 "Inactive" ;
VAL_ 840 FohAddHeater_D_Rq 3 "NotUsed" 2 "On" 1 "Off" 0 "NoModeSelected" ;
VAL_ 840 FohT2Friday_T_Rq 1 "Enable" 0 "Disable" ;
VAL_ 840 FohT1Friday_T_Rq 1 "Enable" 0 "Disable" ;
VAL_ 840 FohT2Wednesday_T_Rq 1 "Enable" 0 "Disable" ;
VAL_ 840 FohT2Tuesday_T_Rq 1 "Enable" 0 "Disable" ;
VAL_ 840 FohT2Thursday_T_Rq 1 "Enable" 0 "Disable" ;
VAL_ 840 FohT2Sunday_T_Rq 1 "Enable" 0 "Disable" ;
VAL_ 840 FohT2Saturday_T_Rq 1 "Enable" 0 "Disable" ;
VAL_ 840 FohT2Monday_T_Rq 1 "Enable" 0 "Disable" ;
VAL_ 840 FohT1Wednesday_T_Rq 1 "Enable" 0 "Disable" ;
VAL_ 840 FohT1Tuesday_T_Rq 1 "Enable" 0 "Disable" ;
VAL_ 840 FohT1Thursday_T_Rq 1 "Enable" 0 "Disable" ;
VAL_ 840 FohT1Sunday_T_Rq 1 "Enable" 0 "Disable" ;
VAL_ 840 FohT1Saturday_T_Rq 1 "Enable" 0 "Disable" ;
VAL_ 840 FohT1Monday_T_Rq 1 "Enable" 0 "Disable" ;
VAL_ 494 HEC_TUPresetArea_Rq 13 "reserved" 12 "GetSAT3PresetData" 11 "GetSAT2PresetData" 15 "reserved_last" 10 "GetSAT1PresetData" 9 "GetDAB2PresetData" 8 "GetDAB1PresetData" 7 "Reserved1" 6 "GetAmPresetData" 5 "GetAmAstPresetData" 4 "GetFmAstPresetData" 3 "GetFm3PresetData" 2 "GetFm2PresetData" 1 "GetFm1PresetData" 0 "Inactive" ;
VAL_ 494 HEC_SetCurrTUBand_Rq 12 "reserved" 11 "SAT3" 10 "SAT2" 15 "reserved_last" 9 "SAT1" 8 "DAB2" 7 "DAB1" 6 "AmAst" 5 "Am" 4 "FmAst" 3 "Fm3" 2 "Fm2" 1 "Fm1" 0 "Inactive" ;
VAL_ 498 HEC_ARReqstrPriority_Rq 0 "EmergencyServ" 1 "TelService" 2 "AutoAnswer" 3 "Ta" 4 "PttMutevoice" 5 "NavUserVoiceCmd" 6 "NavSysVoiceCmd" 7 "Radio" 8 "Disc" 9 "Alarm" 10 "Ptynews" 11 "Aux_ExtSource" 12 "BT_BTNavAndTelMute" 13 "ManualAudioMute" 14 "NotReq" ;
VAL_ 498 HEC_AROperationType_Rq 0 "Inactive" 1 "Requestaudioresource" 2 "Releaseaudioresource" 3 "Releaseallaudioresouces" 4 "Getresourceupdate" 5 "Getallresourceupdates" ;
VAL_ 498 HEC_ARReqstrSystem_Rq 0 "FrontRequester" 1 "RearRequester" ;
VAL_ 498 HEC_ARAudioSource_Rq 15 "iPod" 14 "USB" 13 "BTAudio" 0 "AmfmRadio" 1 "FrontDisc" 2 "SDARS_DAB" 3 "InDashCdChanger" 4 "VoiceRecogniser" 5 "TelematicUnit" 6 "BluetoothPhone" 7 "RearDisc" 8 "APIM" 9 "FrontAuxInput" 10 "Navigation" 11 "RearAux" 12 "NotReq" ;
VAL_ 827 LghtAmbIntns_D2_Sns 3 "Faulty" 2 "High" 1 "Medium" 0 "Low" ;
VAL_ 827 SteClmnSwtchTlt_D_Stat 3 "Unused" 2 "Down" 1 "Up" 0 "Null" ;
VAL_ 827 SteClmnSwtchTel_D_Stat 3 "Unused" 2 "Rearward" 1 "Forward" 0 "Null" ;
VAL_ 827 LghtAmbIntns_D_Sns 3 "Faulty" 2 "High" 1 "Low" 0 "Null" ;
VAL_ 1043 PrkBrkApplCpblty_B_Stat 1 "Ok" 0 "Degraded" ;
VAL_ 1043 PrkBrkPerfActv_B_Stat 1 "Active" 0 "Inactive" ;
VAL_ 1043 PrkBrkPerfMde_D_Stat 3 "Faulty" 2 "NotUsed" 1 "On" 0 "Off" ;
VAL_ 1043 PrkBrkPerfMsgTxt_D_Rq 31 "Message31" 30 "Message30" 29 "Message29" 28 "Message28" 27 "Message27" 26 "Message26" 25 "Message25" 24 "Message24" 23 "Message23" 22 "Message22" 21 "Message21" 20 "Message20" 19 "Message19" 18 "Message18" 17 "Message17" 16 "Message16" 15 "Message15" 14 "Message14" 13 "Message13" 12 "Message12" 11 "Message11" 10 "Message10" 9 "Message9" 8 "Message8" 7 "Message7" 6 "Message6" 5 "Message5" 4 "Message4" 3 "Message3" 2 "Message2" 1 "Message1" 0 "NoMessage" ;
VAL_ 1043 SelDrvMdeHmi04_D_Rq 31 "Faulty" 30 "SelDrvMde31" 29 "SelDrvMde30" 28 "SelDrvMde29" 27 "SelDrvMde28" 26 "SelDrvMde27" 25 "SelDrvMde26" 24 "SelDrvMde25" 23 "SelDrvMde24" 22 "SelDrvMde23" 21 "SelDrvMde22" 20 "SelDrvMde21" 19 "SelDrvMde20" 18 "SelDrvMde19" 17 "SelDrvMde18" 16 "SelDrvMde17" 15 "SelDrvMde16" 14 "SelDrvMde15" 13 "SelDrvMde14" 12 "SelDrvMde13" 11 "SelDrvMde12" 10 "SelDrvMde11" 9 "SelDrvMde10" 8 "SelDrvMde09" 7 "SelDrvMde08" 6 "SelDrvMde07" 5 "SelDrvMde06" 4 "SelDrvMde05" 3 "SelDrvMde04" 2 "SelDrvMde03" 1 "SelDrvMde02" 0 "SelDrvMde01" ;
VAL_ 1043 SelDrvMdeHmi02_D_Rq 31 "Faulty" 30 "SelDrvMde31" 29 "SelDrvMde30" 28 "SelDrvMde29" 27 "SelDrvMde28" 26 "SelDrvMde27" 25 "SelDrvMde26" 24 "SelDrvMde25" 23 "SelDrvMde24" 22 "SelDrvMde23" 21 "SelDrvMde22" 20 "SelDrvMde21" 19 "SelDrvMde20" 18 "SelDrvMde19" 17 "SelDrvMde18" 16 "SelDrvMde17" 15 "SelDrvMde16" 14 "SelDrvMde15" 13 "SelDrvMde14" 12 "SelDrvMde13" 11 "SelDrvMde12" 10 "SelDrvMde11" 9 "SelDrvMde10" 8 "SelDrvMde09" 7 "SelDrvMde08" 6 "SelDrvMde07" 5 "SelDrvMde06" 4 "SelDrvMde05" 3 "SelDrvMde04" 2 "SelDrvMde03" 1 "SelDrvMde02" 0 "SelDrvMde01" ;
VAL_ 1043 IndvMde5_B_Avail 1 "Available" 0 "NotAvailable" ;
VAL_ 1043 IndvMde4_B_Avail 1 "Available" 0 "NotAvailable" ;
VAL_ 1043 IndvMde3_B_Avail 1 "Available" 0 "NotAvailable" ;
VAL_ 1043 IndvMde2_B_Avail 1 "Available" 0 "NotAvailable" ;
VAL_ 1043 IndvMde1_B_Avail 1 "Available" 0 "NotAvailable" ;
VAL_ 1043 IndvMdeSel_D_Stat 3 "NotUsed" 2 "DriveModeChangeRequest" 1 "DriveModeChangeSelection" 0 "NoDriveModeChangeRequest" ;
VAL_ 1043 IndvMdeMsgTxt_D_Rq 15 "Message15" 14 "Message14" 13 "Message13" 12 "Message12" 11 "Message11" 10 "Message10" 9 "Message9" 8 "Message8" 7 "Message7" 6 "Message6" 5 "Message5" 4 "Message4" 3 "Message3" 2 "Message2" 1 "Message1" 0 "NoMessage" ;
VAL_ 1043 TrailOnePdlMsgTxt_D_Rq 7 "Message7" 6 "Message6" 5 "Message5" 4 "Message4" 3 "Message3" 2 "Message2" 1 "Message1" 0 "NoMessage" ;
VAL_ 1043 TrailOnePdlMde_D_Ind 7 "NotUsed_4" 6 "NotUsed_3" 5 "NotUsed_2" 4 "NotUsed_1" 3 "Standby" 2 "Active" 1 "Fault" 0 "Off" ;
VAL_ 1043 OrtaSwtchLamp_B_Rq 1 "On" 0 "Off" ;
VAL_ 1043 OrtaMsgTxt_D_Rq 15 "Message15" 14 "Message14" 13 "Message13" 12 "Message12" 11 "Message11" 10 "Message10" 9 "Message9" 8 "Message8" 7 "Message7" 6 "Message6" 5 "Message5" 4 "Message4" 3 "Message3" 2 "Message2" 1 "Message1" 0 "NoMessage" ;
VAL_ 1043 OrtaMde_D_Ind 2 "StandbyRight" 1 "StandbyLeft" 0 "Off" 7 "Faulty" 6 "NotUsed_2" 5 "NotUsed_1" 4 "ActiveRight" 3 "ActiveLeft" ;
VAL_ 876 SeatIntnsPsngrRr_D_Stat 7 "NotUsed_3" 6 "NotUsed_2" 5 "NotUsed_1" 4 "High" 3 "Medium" 2 "Low" 1 "Off" 0 "Null" ;
VAL_ 876 SeatMasgPsngrRr_D_Stat 15 "NotUsed_10" 14 "NotUsed_9" 13 "NotUsed_8" 12 "NotUsed_7" 11 "NotUsed_6" 10 "Pattern10" 9 "Pattern9" 8 "Pattern8" 7 "Pattern7" 6 "Pattern6" 5 "Pattern5" 4 "Pattern4" 3 "Pattern3" 2 "Pattern2" 1 "Pattern1" 0 "Null" ;
VAL_ 876 SeatSwtchRr_B_Stat 1 "On" 0 "Off" ;
VAL_ 876 SeatPRr_B_Stat 1 "Updating" 0 "NotUpdating" ;
VAL_ 876 SeatFnRr_D_Stat 7 "CushionMassage" 6 "LumbarMassage" 5 "UpperBolster" 4 "LowerBolster" 3 "UpperLumbar" 2 "MiddleLumbar" 1 "LowerLumbar" 0 "Null" ;
VAL_ 876 StmsCshnPsgr_D_Stat2 3 "High" 2 "Low" 1 "Off" 0 "Null" ;
VAL_ 876 StmsLmbrPsgr_D_Stat2 3 "High" 2 "Low" 1 "Off" 0 "Null" ;
VAL_ 875 SeatIntnsDrvRr_D_Stat 7 "NotUsed_3" 6 "NotUsed_2" 5 "NotUsed_1" 4 "High" 3 "Medium" 2 "Low" 1 "Off" 0 "Null" ;
VAL_ 875 SeatMasgDrvRr_D_Stat 15 "NotUsed_10" 14 "NotUsed_9" 13 "NotUsed_8" 12 "NotUsed_7" 11 "NotUsed_6" 10 "Pattern10" 9 "Pattern9" 8 "Pattern8" 7 "Pattern7" 6 "Pattern6" 5 "Pattern5" 4 "Pattern4" 3 "Pattern3" 2 "Pattern2" 1 "Pattern1" 0 "Null" ;
VAL_ 875 SeatSwtchRl_B_Stat 1 "On" 0 "Off" ;
VAL_ 875 SeatPRl_B_Stat 1 "Updating" 0 "NotUpdating" ;
VAL_ 875 SeatFnRl_D_Stat 7 "CushionMassage" 6 "LumbarMassage" 5 "UpperBolster" 4 "LowerBolster" 3 "UpperLumbar" 2 "MiddleLumbar" 1 "LowerLumbar" 0 "Null" ;
VAL_ 875 StmsLmbrDrv_D_Stat2 3 "High" 2 "Low" 1 "Off" 0 "Null" ;
VAL_ 875 StmsCshnDrv_D_Stat2 3 "High" 2 "Low" 1 "Off" 0 "Null" ;
VAL_ 545 SpkrDgtlRight_D_Stat 3 "Faulty" 2 "Normal" 1 "NotPresent" 0 "Null" ;
VAL_ 545 SpkrDgtlLeft_D_Stat 3 "Faulty" 2 "Normal" 1 "NotPresent" 0 "Null" ;
VAL_ 545 SpkrDgtlCntr_D_Stat 3 "Faulty" 2 "Normal" 1 "NotPresent" 0 "Null" ;
VAL_ 545 SurndSndUpmix2_D_Stat 4 "Audience" 3 "On_Stage" 2 "Surround" 1 "Stereo" 0 "Inactive" ;
VAL_ 545 DSP_Bezel_Diag_St 15 "NotUsed_11" 14 "NotUsed_10" 13 "NotUsed_9" 12 "NotUsed_8" 11 "NotUsed_7" 10 "NotUsed_6" 9 "NotUsed_5" 8 "NotUsed_4" 7 "NotUsed_3" 6 "NotUsed_2" 5 "NotUsed_1" 4 "SpeakerWalkAround" 3 "CalibrationPartNumber" 2 "HardwarePartNumber" 1 "SoftwarePartNumber" 0 "Inactive_NOP" ;
VAL_ 545 SndImmrsnLvl_D_Stat 255 "NotUsed_127" 254 "NotUsed_126" 253 "NotUsed_125" 252 "NotUsed_124" 251 "NotUsed_123" 250 "NotUsed_122" 249 "NotUsed_121" 248 "NotUsed_120" 247 "NotUsed_119" 246 "NotUsed_118" 245 "NotUsed_117" 244 "NotUsed_116" 243 "NotUsed_115" 242 "NotUsed_114" 241 "NotUsed_113" 240 "NotUsed_112" 239 "NotUsed_111" 238 "NotUsed_110" 237 "NotUsed_109" 236 "NotUsed_108" 235 "NotUsed_107" 234 "NotUsed_106" 233 "NotUsed_105" 232 "NotUsed_104" 231 "NotUsed_103" 230 "NotUsed_102" 229 "NotUsed_101" 228 "NotUsed_100" 227 "NotUsed_99" 226 "NotUsed_98" 225 "NotUsed_97" 224 "NotUsed_96" 223 "NotUsed_95" 222 "NotUsed_94" 221 "NotUsed_93" 220 "NotUsed_92" 219 "NotUsed_91" 218 "NotUsed_90" 217 "NotUsed_89" 216 "NotUsed_88" 215 "NotUsed_87" 214 "NotUsed_86" 213 "NotUsed_85" 212 "NotUsed_84" 211 "NotUsed_83" 210 "NotUsed_82" 209 "NotUsed_81" 208 "NotUsed_80" 207 "NotUsed_79" 206 "NotUsed_78" 205 "NotUsed_77" 204 "NotUsed_76" 203 "NotUsed_75" 202 "NotUsed_74" 201 "NotUsed_73" 200 "NotUsed_72" 199 "NotUsed_71" 198 "NotUsed_70" 197 "NotUsed_69" 196 "NotUsed_68" 195 "NotUsed_67" 194 "NotUsed_66" 193 "NotUsed_65" 192 "NotUsed_64" 191 "NotUsed_63" 190 "NotUsed_62" 189 "NotUsed_61" 188 "NotUsed_60" 187 "NotUsed_59" 186 "NotUsed_58" 185 "NotUsed_57" 184 "NotUsed_56" 183 "NotUsed_55" 182 "NotUsed_54" 181 "NotUsed_53" 180 "NotUsed_52" 179 "NotUsed_51" 178 "NotUsed_50" 177 "NotUsed_49" 176 "NotUsed_48" 175 "NotUsed_47" 174 "NotUsed_46" 173 "NotUsed_45" 172 "NotUsed_44" 171 "NotUsed_43" 170 "NotUsed_42" 169 "NotUsed_41" 168 "NotUsed_40" 167 "NotUsed_39" 166 "NotUsed_38" 165 "NotUsed_37" 164 "NotUsed_36" 163 "NotUsed_35" 162 "NotUsed_34" 161 "NotUsed_33" 160 "NotUsed_32" 159 "NotUsed_31" 158 "NotUsed_30" 157 "NotUsed_29" 156 "NotUsed_28" 155 "NotUsed_27" 154 "NotUsed_26" 153 "NotUsed_25" 152 "NotUsed_24" 151 "NotUsed_23" 150 "NotUsed_22" 149 "NotUsed_21" 148 "NotUsed_20" 147 "NotUsed_19" 146 "NotUsed_18" 145 "NotUsed_17" 144 "NotUsed_16" 143 "NotUsed_15" 142 "NotUsed_14" 141 "NotUsed_13" 140 "NotUsed_12" 139 "NotUsed_11" 138 "NotUsed_10" 137 "NotUsed_9" 136 "NotUsed_8" 135 "NotUsed_7" 134 "NotUsed_6" 133 "NotUsed_5" 132 "NotUsed_4" 131 "NotUsed_3" 130 "NotUsed_2" 129 "NotUsed_1" 128 "Level127" 127 "Level126" 126 "Level125" 125 "Level124" 124 "Level123" 123 "Level122" 122 "Level121" 121 "Level120" 120 "Level119" 119 "Level118" 118 "Level117" 117 "Level116" 116 "Level115" 115 "Level114" 114 "Level113" 113 "Level112" 112 "Level111" 111 "Level110" 110 "Level109" 109 "Level108" 108 "Level107" 107 "Level106" 106 "Level105" 105 "Level104" 104 "Level103" 103 "Level102" 102 "Level101" 101 "Level100" 100 "Level99" 99 "Level98" 98 "Level97" 97 "Level96" 96 "Level95" 95 "Level94" 94 "Level93" 93 "Level92" 92 "Level91" 91 "Level90" 90 "Level89" 89 "Level88" 88 "Level87" 87 "Level86" 86 "Level85" 85 "Level84" 84 "Level83" 83 "Level82" 82 "Level81" 81 "Level80" 80 "Level79" 79 "Level78" 78 "Level77" 77 "Level76" 76 "Level75" 75 "Level74" 74 "Level73" 73 "Level72" 72 "Level71" 71 "Level70" 70 "Level69" 69 "Level68" 68 "Level67" 67 "Level66" 66 "Level65" 65 "Level64" 64 "Level63" 63 "Level62" 62 "Level61" 61 "Level60" 60 "Level59" 59 "Level58" 58 "Level57" 57 "Level56" 56 "Level55" 55 "Level54" 54 "Level53" 53 "Level52" 52 "Level51" 51 "Level50" 50 "Level49" 49 "Level48" 48 "Level47" 47 "Level46" 46 "Level45" 45 "Level44" 44 "Level43" 43 "Level42" 42 "Level41" 41 "Level40" 40 "Level39" 39 "Level38" 38 "Level37" 37 "Level36" 36 "Level35" 35 "Level34" 34 "Level33" 33 "Level32" 32 "Level31" 31 "Level30" 30 "Level29" 29 "Level28" 28 "Level27" 27 "Level26" 26 "Level25" 25 "Level24" 24 "Level23" 23 "Level22" 22 "Level21" 21 "Level20" 20 "Level19" 19 "Level18" 18 "Level17" 17 "Level16" 16 "Level15" 15 "Level14" 14 "Level13" 13 "Level12" 12 "Level11" 11 "Level10" 10 "Level9" 9 "Level8" 8 "Level7" 7 "Level6" 6 "Level5" 5 "Level4" 4 "Level3" 3 "Level2" 2 "Level1" 1 "Level0" 0 "Inactive" ;
VAL_ 545 DSP_Sur_Sound_st 2 "Surround" 1 "Stereo" 0 "Inactive" ;
VAL_ 545 DSP_MyKeyVolLimitUp_St 2 "NotUpdated" 1 "Updated" 0 "Invalid" ;
VAL_ 545 DSP_MyKeyVolLim_St 0 "Invalid" 1 "Off" 2 "On" ;
VAL_ 545 DSP_BeltminderAudio_St 0 "Invalid" 1 "Off" 2 "On" ;
VAL_ 545 DSP_Audio_Volume_Up_St 1 "Update" 0 "NoUpdate" ;
VAL_ 545 AutoConfigOcc_Rear 1 "Supported" 0 "Not_Supported" ;
VAL_ 545 AutoConfigOcc_Front 1 "Supported" 0 "Not_Supported" ;
VAL_ 545 AutoConfigOcc_Driver 1 "Supported" 0 "Not_Supported" ;
VAL_ 545 AutoConfigOcc_AllSeats 1 "Supported" 0 "Not_Supported" ;
VAL_ 545 AudioOccMde_D_Stat 15 "Reserved9" 14 "Reserved8" 13 "Reserved7" 12 "Reserved6" 11 "Reserved5" 10 "Reserved4" 9 "Convertible" 8 "RearSeats" 7 "FrontSeats" 6 "Reserved3" 5 "Reserved2" 4 "Reserved1" 3 "Passenger" 2 "Driver" 1 "All" 0 "Invalid" ;
VAL_ 1092 BattChrgOvrCurnt_B_Falt 1 "Yes" 0 "No" ;
VAL_ 1092 BattTracCell_U_Mx 16383 "Faulty" ;
VAL_ 1092 BattTracMnCell_Te_Actl 255 "Faulty" 254 "NoDataExists" ;
VAL_ 1092 BattTracInsAlrm_B_Stat 1 "Active" 0 "Inactive" ;
VAL_ 1092 BattTracUMx_B_Stat 1 "Active" 0 "Inactive" ;
VAL_ 1092 BattTracTeMx_B_Stat 1 "Exceeded" 0 "NotExceeded" ;
VAL_ 1092 BattTracMxCell_Te_Actl 255 "Faulty" 254 "NoDataExists" ;
VAL_ 1092 BattTracEq_B_Actl 1 "Active" 0 "Inactive" ;
VAL_ 1092 BattTracCell_U_Mn 16383 "Faulty" ;
VAL_ 1092 BattTracUMn_B_Stat 1 "Active" 0 "Inactive" ;
VAL_ 1092 BattTracUAlrm_B_Stat 1 "Active" 0 "Inactive" ;
VAL_ 1092 BattTracTeMn_B_Stat 1 "Exceeded" 0 "NotExceeded" ;
VAL_ 1092 BattTracInsltn_R_Actl 255 "Faulty" ;
VAL_ 936 ApaButtnPrssd_B_Stat 1 "Pressed" 0 "Not_Pressed" ;
VAL_ 936 ApaSys_D_Stat 7 "Faulty" 6 "Finished" 5 "NotAccessible" 4 "ApaCancelled" 3 "Overspeed" 2 "On" 1 "Off" 0 "Null" ;
VAL_ 936 ApaSteWhl_D_RqDrv 3 "TakeControl" 2 "RemoveHands" 1 "NoRequest" 0 "Null" ;
VAL_ 936 ApaSteScanMde_D_Stat 0 "Null" 1 "NotScanning" 2 "Scanning" 3 "Steering" ;
VAL_ 936 ApaSelSapp_D_Stat 3 "NotConfigured" 2 "NotSelectable" 1 "Selectable" 0 "Null" ;
VAL_ 936 ApaSelPpa_D_Stat 3 "NotConfigured" 2 "NotSelectable" 1 "Selectable" 0 "Null" ;
VAL_ 936 ApaSelPoa_D_Stat 3 "NotConfigured" 2 "NotSelectable" 1 "Selectable" 0 "Null" ;
VAL_ 936 ApaScan_D_Stat 3 "ParkSlotReady" 2 "ParkSlotFound" 1 "NoParkSlot" 0 "Null" ;
VAL_ 936 ApaLongCtl_D_RqDrv 7 "NotUsed3" 6 "NotUsed2" 5 "ReleaseBrake" 4 "DriveBackward" 3 "DriveForward" 2 "Stop" 1 "NoRequest" 0 "Null" ;
VAL_ 936 ApaGearShif_D_RqDrv 7 "NotUSed2" 6 "NotUsed1" 5 "ShiftToP" 4 "ShiftToN" 3 "ShiftToD" 2 "ShiftToR" 1 "NoRequest" 0 "Null" ;
VAL_ 936 ApaActvSide2_D_Stat 3 "NoSide" 2 "Right" 1 "Left" 0 "Null" ;
VAL_ 936 ApaAcsy_D_RqDrv 7 "CloseDoor" 6 "SelectSideRight" 5 "SelectSideLeft" 4 "CheckForObject" 3 "PressApaButton" 2 "SelectSide" 1 "NoRequest" 0 "Null" ;
VAL_ 936 ApaChime_D_Rq 7 "NotUsed2" 6 "NotUsed1" 5 "Warning_Chime" 4 "Finish_Chime" 3 "Stop_Now_Chime" 2 "Spot_Ready_Chime" 1 "Spot_Found_Chime" 0 "No_Chime" ;
VAL_ 936 EPASExtAngleStatReq 1 "Request" 0 "NoRequest" ;
VAL_ 936 ExtSteeringAngleReq2 32767 "Invalid" 32766 "Unknown" ;
VAL_ 936 ApaTrgtDist_D_Stat 15 "Step15" 14 "Step14" 13 "Step13" 12 "Step12" 11 "Step11" 10 "Step10" 9 "Step9" 8 "Step8" 7 "Step7" 6 "Step6" 5 "Step5" 4 "Step4" 3 "Step3" 2 "Step2" 1 "Step1" 0 "Off" ;
VAL_ 674 ArmrestStwdRear_B_Stat 1 "Yes" 0 "No" ;
VAL_ 674 RACM_Coding_BtnID_D 1 "Pressed" 0 "Not_Pressed" ;
VAL_ 674 RACM_Coding_BtnID_C 1 "Pressed" 0 "Not_Pressed" ;
VAL_ 674 RACM_Coding_BtnID_B 1 "Pressed" 0 "Not_Pressed" ;
VAL_ 674 RACM_Coding_BtnID_A 1 "Pressed" 0 "Not_Pressed" ;
VAL_ 674 RearAudioCtlLck_D_Stat 2 "Unlocked" 1 "Locked" 0 "Null" ;
VAL_ 75 VedsPasKneeBag_D_Ltchd 7 "Fault" 6 "NotSupported" 5 "Unused_3" 4 "Unused_2" 3 "Unused_1" 2 "NotDeployed" 1 "Deployed" 0 "NoEvent" ;
VAL_ 75 VedsRw1mBckl_D_Ltchd 5 "Unused_3" 4 "Unused_2" 3 "Unused_1" 2 "NotBelted" 1 "Belted" 0 "NoEvent" 7 "Fault" 6 "NotSupported" ;
VAL_ 75 VedsRw1mBelt_D_Ltchd 7 "Fault" 6 "NotSupported" 5 "Unused_3" 4 "Unused_2" 3 "Unused_1" 2 "NotDeployed" 1 "Deployed" 0 "NoEvent" ;
VAL_ 75 VedsRw2pRib_D_Ltchd 7 "Fault" 6 "NotSupported" 5 "Unused_3" 4 "Unused_2" 3 "Unused_1" 2 "NotDeployed" 1 "Deployed" 0 "NoEvent" ;
VAL_ 75 VedsRw2dRib_D_Ltchd 7 "Fault" 6 "NotSupported" 5 "Unused_3" 4 "Unused_2" 3 "Unused_1" 2 "NotDeployed" 1 "Deployed" 0 "NoEvent" ;
VAL_ 75 VedsRw3pBckl_D_Ltchd 5 "Unused_3" 4 "Unused_2" 3 "Unused_1" 2 "NotBelted" 1 "Belted" 0 "NoEvent" 7 "Fault" 6 "NotSupported" ;
VAL_ 75 VedsRw3mBckl_D_Ltchd 5 "Unused_3" 4 "Unused_2" 3 "Unused_1" 2 "NotBelted" 1 "Belted" 0 "NoEvent" 7 "Fault" 6 "NotSupported" ;
VAL_ 75 VedsRw3dBckl_D_Ltchd 5 "Unused_3" 4 "Unused_2" 3 "Unused_1" 2 "NotBelted" 1 "Belted" 0 "NoEvent" 7 "Fault" 6 "NotSupported" ;
VAL_ 75 VedsRw2pBckl_D_Ltchd 5 "Unused_3" 4 "Unused_2" 3 "Unused_1" 2 "NotBelted" 1 "Belted" 0 "NoEvent" 7 "Fault" 6 "NotSupported" ;
VAL_ 75 VedsRw2mBckl_D_Ltchd 5 "Unused_3" 4 "Unused_2" 3 "Unused_1" 2 "NotBelted" 1 "Belted" 0 "NoEvent" 7 "Fault" 6 "NotSupported" ;
VAL_ 75 VedsRw2dBckl_D_Ltchd 5 "Unused_3" 4 "Unused_2" 3 "Unused_1" 2 "NotBelted" 1 "Belted" 0 "NoEvent" 7 "Fault" 6 "NotSupported" ;
VAL_ 75 VedsRw1PasChld_D_Ltchd 7 "Fault" 6 "NotSupported" 5 "Unused_3" 4 "Unused_2" 3 "Unused_1" 2 "ChildNotDetected" 1 "ChildDetected" 0 "NoEvent" ;
VAL_ 75 VedsRw1PasBckl_D_Ltchd 5 "Unused_3" 4 "Unused_2" 3 "Unused_1" 2 "NotBelted" 1 "Belted" 0 "NoEvent" 7 "Fault" 6 "NotSupported" ;
VAL_ 75 VedsRw1DrvBckl_D_Ltchd 5 "Unused_3" 4 "Unused_2" 3 "Unused_1" 2 "NotBelted" 1 "Belted" 0 "NoEvent" 7 "Fault" 6 "NotSupported" ;
VAL_ 75 VedsRw3pRib_D_Ltchd 7 "Fault" 6 "NotSupported" 5 "Unused_3" 4 "Unused_2" 3 "Unused_1" 2 "NotDeployed" 1 "Deployed" 0 "NoEvent" ;
VAL_ 75 VedsRw3dRib_D_Ltchd 7 "Fault" 6 "NotSupported" 5 "Unused_3" 4 "Unused_2" 3 "Unused_1" 2 "NotDeployed" 1 "Deployed" 0 "NoEvent" ;
VAL_ 74 VedsPasSideBag_D_Ltchd 7 "Fault" 6 "NotSupported" 5 "Unused_3" 4 "Unused_2" 3 "Unused_1" 2 "NotDeployed" 1 "Deployed" 0 "NoEvent" ;
VAL_ 74 VedsPasCrtnBag_D_Ltchd 7 "Fault" 6 "NotSupported" 5 "Unused_3" 4 "Unused_2" 3 "Unused_1" 2 "NotDeployed" 1 "Deployed" 0 "NoEvent" ;
VAL_ 74 VedsPasBelt_D_Ltchd 7 "Fault" 6 "NotSupported" 5 "Unused_3" 4 "Unused_2" 3 "Unused_1" 2 "NotDeployed" 1 "Deployed" 0 "NoEvent" ;
VAL_ 74 VedsPasBag_D_Ltchd 7 "Fault" 6 "NotSupported" 5 "Unused_3" 4 "Unused_2" 3 "Unused_1" 2 "NotDeployed" 1 "Deployed" 0 "NoEvent" ;
VAL_ 74 VedsMultiEvnt_D_Ltchd 7 "Fault" 6 "NotSupported" 5 "Unused_3" 4 "Unused_2" 3 "Unused_1" 2 "Yes" 1 "No" 0 "NoEvent" ;
VAL_ 74 VedsMaxDeltaV_D_Ltchd 0 "NoEvent" 255 "Fault" 254 "NotSupported" ;
VAL_ 74 VedsDrvKneeBag_D_Ltchd 7 "Fault" 6 "NotSupported" 5 "Unused_3" 4 "Unused_2" 3 "Unused_1" 2 "NotDeployed" 1 "Deployed" 0 "NoEvent" ;
VAL_ 74 VedsEvntType_D_Ltchd 7 "Fault" 6 "NotSupported" 5 "Unused" 4 "Rolllover" 3 "Rear" 2 "Side" 1 "Frontal" 0 "NoEvent" ;
VAL_ 74 VedsEvntRoll_D_Ltchd 7 "Fault" 6 "NotSupported" 5 "Unused_3" 4 "Unused_2" 3 "Unused_1" 2 "Yes" 1 "No" 0 "NoEvent" ;
VAL_ 74 VedsDrvSideBag_D_Ltchd 7 "Fault" 6 "NotSupported" 5 "Unused_3" 4 "Unused_2" 3 "Unused_1" 2 "NotDeployed" 1 "Deployed" 0 "NoEvent" ;
VAL_ 74 VedsDrvCrtnBag_D_Ltchd 7 "Fault" 6 "NotSupported" 5 "Unused_3" 4 "Unused_2" 3 "Unused_1" 2 "NotDeployed" 1 "Deployed" 0 "NoEvent" ;
VAL_ 74 VedsDrvBelt_D_Ltchd 7 "Fault" 6 "NotSupported" 5 "Unused_3" 4 "Unused_2" 3 "Unused_1" 2 "NotDeployed" 1 "Deployed" 0 "NoEvent" ;
VAL_ 74 VedsDrvBag_D_Ltchd 7 "Fault" 6 "NotSupported" 5 "Unused_3" 4 "Unused_2" 3 "Unused_1" 2 "NotDeployed" 1 "Deployed" 0 "NoEvent" ;
VAL_ 74 eCallNotification 3 "Not_Used" 2 "Active" 1 "Normal" 0 "Not_Supported" ;
VAL_ 780 TrlrTireSensRm_D_Stat 15 "NotSupported" 14 "NotUsed10" 13 "NotUsed9" 12 "NotUsed8" 11 "NotUsed7" 10 "NotUsed6" 9 "NotUsed5" 8 "NotUsed4" 7 "NotUsed3" 6 "NotUsed2" 5 "NotUsed1" 4 "Alert" 3 "Fault" 2 "Low" 1 "Normal" 0 "Unknown" ;
VAL_ 780 TrlrTireSensRf_D_Stat 15 "NotSupported" 14 "NotUsed10" 13 "NotUsed9" 12 "NotUsed8" 11 "NotUsed7" 10 "NotUsed6" 9 "NotUsed5" 8 "NotUsed4" 7 "NotUsed3" 6 "NotUsed2" 5 "NotUsed1" 4 "Alert" 3 "Fault" 2 "Low" 1 "Normal" 0 "Unknown" ;
VAL_ 780 TrlrTireRr_P_Actl 65534 "Invalid" 65535 "NotSupported" ;
VAL_ 780 TrlrTireRm_P_Actl 65534 "Invalid" 65535 "NotSupported" ;
VAL_ 780 TrlrTireRf_P_Actl 65534 "Invalid" 65535 "NotSupported" ;
VAL_ 780 TrlrTireSensRr_D_Stat 15 "NotSupported" 14 "NotUsed10" 13 "NotUsed9" 12 "NotUsed8" 11 "NotUsed7" 10 "NotUsed6" 9 "NotUsed5" 8 "NotUsed4" 7 "NotUsed3" 6 "NotUsed2" 5 "NotUsed1" 4 "Alert" 3 "Fault" 2 "Low" 1 "Normal" 0 "Unknown" ;
VAL_ 779 TrlrTireSensLr_D_Stat 15 "NotSupported" 14 "NotUsed10" 13 "NotUsed9" 12 "NotUsed8" 11 "NotUsed7" 10 "NotUsed6" 9 "NotUsed5" 8 "NotUsed4" 7 "NotUsed3" 6 "NotUsed2" 5 "NotUsed1" 4 "Alert" 3 "Fault" 2 "Low" 1 "Normal" 0 "Unknown" ;
VAL_ 779 TrlrTireSensLm_D_Stat 15 "NotSupported" 14 "NotUsed10" 13 "NotUsed9" 12 "NotUsed8" 11 "NotUsed7" 10 "NotUsed6" 9 "NotUsed5" 8 "NotUsed4" 7 "NotUsed3" 6 "NotUsed2" 5 "NotUsed1" 4 "Alert" 3 "Fault" 2 "Low" 1 "Normal" 0 "Unknown" ;
VAL_ 779 TrlrTireSensLf_D_Stat 15 "NotSupported" 14 "NotUsed10" 13 "NotUsed9" 12 "NotUsed8" 11 "NotUsed7" 10 "NotUsed6" 9 "NotUsed5" 8 "NotUsed4" 7 "NotUsed3" 6 "NotUsed2" 5 "NotUsed1" 4 "Alert" 3 "Fault" 2 "Low" 1 "Normal" 0 "Unknown" ;
VAL_ 779 TrlrTireLr_P_Actl 65534 "Invalid" 65535 "NotSupported" ;
VAL_ 779 TrlrTireLm_P_Actl 65534 "Invalid" 65535 "NotSupported" ;
VAL_ 779 TrlrTireLf_P_Actl 65534 "Invalid" 65535 "NotSupported" ;
VAL_ 783 TrlrTireCnt_D_RqDrv 7 "Faulty" 6 "TwelveTire" 5 "EightTire" 4 "FourTireOneAxle" 3 "Six_Tire" 2 "Four_Tire" 1 "Two_Tire" 0 "Unconfigured" ;
VAL_ 783 TrlrLearnMdeOn_B_RqDrv 1 "True" 0 "False" ;
VAL_ 638 EmgcyCallHmi_D_Stat 15 "NotUsed_1" 14 "Standby" 13 "Disabled" 12 "Malfunction" 11 "CallCompleted" 10 "CallDisconnected" 9 "CallNotPossible" 8 "CallCancelled" 7 "CallRetry" 6 "CallConnected" 5 "CallInProgress" 4 "CallMsdTransfer" 3 "CallDial" 2 "CallCancelTimer" 1 "NoEvent" 0 "Null" ;
VAL_ 638 EmgcyCallFalt_B_Dsply 1 "Yes" 0 "No" ;
VAL_ 638 EmgcyCall_D_Stat 7 "NotUsed_3" 6 "NotUsed_2" 5 "NotUsed_1" 4 "ManualEmergencyCall" 3 "AutoEmergencyCall" 2 "NoEvent" 1 "EmergencyCallNotSupported" 0 "Null" ;
VAL_ 555 HudVertSzMnuOn_B_Stat 1 "On" 0 "Off" ;
VAL_ 555 HudVertMnuOn_B_Stat 1 "Yes" 0 "No" ;
VAL_ 555 HudTestMdeActv_B_Stat 1 "Active" 0 "Inactive" ;
VAL_ 555 HudSwtch_B_Stat 1 "Pressed" 0 "Not_Pressed" ;
VAL_ 555 HudRotatMnuOn_B_Stat 1 "Yes" 0 "No" ;
VAL_ 555 HudMsgTxt_D_Rq 7 "Message7" 6 "Message6" 5 "Message5" 4 "Message4" 3 "Message3" 2 "Message2" 1 "Message1" 0 "NoMessage" ;
VAL_ 555 HudHzntlMnuOn_B_Stat 1 "Yes" 0 "No" ;
VAL_ 555 HudBrightMnuOn_B_Stat 1 "Yes" 0 "No" ;
VAL_ 555 HudActv_D_Stat 7 "Faulty" 6 "NotUsed_2" 5 "NotUsed_1" 4 "Error" 3 "Active" 2 "Pending" 1 "Inactive" 0 "NoData" ;
VAL_ 124 VehTrvlDir_D_Stat 7 "Faulty" 6 "NoDataExists" 5 "NotUsed2" 4 "NotUsed1" 3 "Reverse" 2 "LikelyReverse" 1 "Forward" 0 "LikelyForward" ;
VAL_ 124 VehOverGnd_V_Est 65535 "Invalid" 65534 "Unknown" ;
VAL_ 124 VehLongComp_A_Actl 1023 "Fault" 1022 "NoDataExists" ;
VAL_ 124 VehLatComp_A_Actl 1023 "Fault" 1022 "NoDataExists" ;
VAL_ 124 VehYawComp_W_Actl 4095 "Fault" 4094 "NoDataExists" ;
VAL_ 736 TextMessage_Rsp 3 "Cancelled" 2 "MessageIgnored" 1 "Listening" 0 "Invalid" ;
VAL_ 736 VRM_IncCallOption_St 0 "Inactive" 1 "RejectAll" 2 "AcceptIncomingCall" 3 "Silent" ;
VAL_ 736 BTInCallOptions_St 6 "HoldModeoff" 5 "InHoldMode" 4 "InHandsFreeMode" 3 "InPrivacyMode" 2 "Joined" 1 "Switched" 0 "Inactive" ;
VAL_ 722 VRM_ComShuffleTrack_St 0 "Invalid" 1 "CommandNotIssued" 2 "On" 3 "Off" ;
VAL_ 722 VRM_ComCompression_St 0 "Invalid" 1 "CommandNotIssued" 2 "On" 3 "Off" ;
VAL_ 722 VRM_ComStFreqMode_St 0 "Invalid" 1 "CommandNotIssued" 2 "Fm" 3 "Am" 4 "Reserved" ;
VAL_ 722 VRM_ComAutostore_St 0 "Invalid" 1 "CommandNotIssued" 2 "PerfomAutostore" ;
VAL_ 722 VRM_ComBand_St 0 "Invalid" 1 "CommandNotIssued" 2 "Fm1" 3 "Fm2" 4 "Fmas" 5 "Am" 6 "Amas" 7 "AutostoreMode" ;
VAL_ 722 VRM_TMCVoice 0 "Invalid" 1 "CommandNotIssued" 2 "On" 3 "Off" ;
VAL_ 722 VRM_NewSMS 3 "UnreadSMSMessagesAvailable" 0 "Invalid" 1 "NewSmsAvailable" 2 "NoNewSmsAvailable" ;
VAL_ 722 VRM_ComRSEDisplay_St 0 "Invalid" 1 "CommandNotIssued" 2 "On" 3 "Off" ;
VAL_ 722 VRM_ComPresetCall_St 0 "Invalid" 1 "CommandNotIssued" 2 "Prescall1" 3 "Prescall2" 4 "Prescall3" 5 "Prescall4" 6 "Prescall5" 7 "Prescall6" ;
VAL_ 722 VRM_ComTape_St 0 "Invalid" 1 "CommandNotIssued" 2 "Play" 3 "Rewind" 4 "Forward" 5 "ChangeSide" 6 "AutosearchForward" 7 "AutosearchBackward" ;
VAL_ 722 VRM_ComShuffleDiscs_St 0 "Invalid" 1 "CommandNotIssued" 2 "On" 3 "Off" ;
VAL_ 722 VRM_ComDolbyNR_St 0 "Invalid" 1 "CommandNotIssued" 2 "On" 3 "Off" ;
VAL_ 722 VRM_ComSourceSelect_St 7 "BTAudio" 6 "Con" 0 "Invalid" 1 "CommandNotIssued" 2 "Radio" 3 "SDCard" 4 "SingleDisc" 5 "MultiDisc" ;
VAL_ 722 VRM_ComRouteStrategy_St 0 "Invalid" 1 "CommandNotIssued" 2 "Shortesttime" 3 "Shortestdistance" 4 "Majorroadsavoid" 5 "Majorroadsprefer" 6 "TollRoadsaviod" 7 "TollRoadsprefer" 8 "Ferriesavoid" 9 "Ferriesprefer" ;
VAL_ 721 VRM_BTDefaultPhone_St 0 "Invalid" 1 "PhoneIndex1" 2 "PhoneIndex2" 3 "PhoneIndex3" 4 "PhoneIndex4" 5 "PhoneIndex5" 6 "PhoneIndex6" 7 "CradlePhone" 8 "NoPhone" ;
VAL_ 721 VRM_DetourUnit_st 0 "Invalid" 1 "Miles" 2 "Kilometer" 3 "Nounitdefined" ;
VAL_ 721 VRM_Zoom_Option_St 0 "Invalid" 1 "AbsoluteValue" 2 "InrelativeValue" 3 "OutrelativeValue" ;
VAL_ 721 VRM_ComBTDTMFTone_St 14 "Dtmfplus" 0 "Invalid" 1 "CommandNotIssued" 2 "Dtmf0" 3 "Dtmf1" 4 "Dtmf2" 5 "Dtmf3" 6 "Dtmf4" 7 "Dtmf5" 8 "Dtmf6" 9 "Dtmf7" 10 "Dtmf8" 11 "Dtmf9" 12 "Dtmfstar" 13 "Dtmfcross" ;
VAL_ 721 VRM_SuggestedRoute_St 0 "Invalid" 1 "CommandNotIssued" 2 "Accept" 3 "Reject" ;
VAL_ 721 VRM_ComDelWaypoint_St 0 "Invalid" 1 "CommandNotIssued" 2 "DeleteNextWayptDestination" ;
VAL_ 721 VRM_ComSelectDisc_St 0 "Invalid" 1 "CommandNotIssued" 2 "Disc1" 3 "Disc2" 4 "Disc3" 5 "Disc4" 6 "Disc5" 7 "Disc6" ;
VAL_ 721 VRM_ComTelService_St 0 "Invalid" 1 "CommandNotIssued" 2 "InformationCall" 3 "TelephonyCall" 4 "RedialLastIncoming" ;
VAL_ 721 VRM_ComDestHome_St 0 "Invalid" 1 "CommandNotIssued" 2 "SetDestinationHome" ;
VAL_ 721 VRM_ComShowNavInfo_St 0 "Invalid" 1 "CommandNotIssued" 2 "CurrentPos" 3 "Destination" 4 "CompleteRoute" 5 "NorthDirectionToTop" 6 "CarDirectionToTop" 7 "TurnList" ;
VAL_ 721 VRM_VoiceRecStatus_St 0 "Invalid" 1 "Idle" 2 "Listening" 3 "Reserved" 4 "CommandNotAllowed" ;
VAL_ 721 VRM_ComSelTrackSource_St 0 "Invalid" 1 "CommandNotIssued" 2 "Cd" 3 "CdChanger" ;
VAL_ 721 VRM_ComDetour_St 0 "Invalid" 1 "CommandNotIssued" 2 "Detour1" 3 "Detour2" 4 "Detour3" 5 "Detour4" 6 "Detour5" 7 "Detour10" 8 "Detour15" 9 "Detour20" 10 "Detour25" 11 "Detour50" 12 "Detour100" ;
VAL_ 721 VRM_ComDisplay_St 0 "Invalid" 1 "CommandNotIssued" 2 "DisplayOn" 3 "DisplayOff" 4 "Day" 5 "Night" 6 "Auto" 7 "Twilight" ;
VAL_ 721 VRM_ComDynamicGuidande_St 0 "Invalid" 1 "CommandNotIssued" 2 "On" 3 "Off" ;
VAL_ 721 VRM_ComZoom_St 0 "Invalid" 1 "CommandNotIssued" 2 "Level1" 3 "Level2" 4 "Level3" 5 "Level4" 6 "Level5" 7 "Level6" 8 "Level7" 9 "Level8" 10 "Level9" 11 "Level10" 12 "Level11" 13 "Level12" 14 "Level13" ;
VAL_ 721 VRM_ComCallControl_St 0 "Invalid" 1 "CommandNotIssued" 2 "Pickup" 3 "Reject" 4 "EndOngoingCall" ;
VAL_ 721 VRM_ComGuidance_St 0 "Invalid" 1 "CommandNotIssued" 2 "VoiceGuidanceOn" 3 "VoiceGuidanceOff" 4 "CancelGuidance" 5 "RepeatLastVoiceGuidance" ;
VAL_ 721 VRM_ComTrafficInfDsp_St 0 "Invalid" 1 "CommandNotIssued" 2 "ShowTrafficInfoOnDisplay" 3 "HideTrafficInfoOnDisplay" ;
VAL_ 720 VRM_PhMicrophoneMute_St 3 "Reserved" 2 "MicrophoneIsUnmuted" 1 "MicrophoneIsMuted" 0 "Invalid" ;
VAL_ 720 Aioc_ExtSrcOutpMode_St 8 "NotAllocated" 4 "AllocatedBtAudio" 3 "AllocatedBtNavigation" 2 "AllocatedBtPhone" 1 "AllocatedVr" 0 "Invalid" 7 "AllocatedAUX3" 6 "AllocatediPod" 5 "AllocatedUSB" ;
VAL_ 720 VRM_BTPhoneSts_St 16 "Connected_Call_on_hold" 15 "Conference_OtherCallOnHold" 0 "Invalid" 1 "Idle" 2 "Dialing" 3 "Connected" 4 "CradlephNotReady" 5 "NumUnobtainable" 6 "IncomCall" 7 "NoLinkToBt" 8 "InitBtCon" 9 "PhoneBusy" 10 "PhoneVr" 11 "NotSupported" 12 "BtPhPriv" 13 "ConfCall" 14 "Conference_2ndIncCall" ;
VAL_ 720 VRM_SubscribeStatus_St 0 "Invalid" 1 "OnSubscribingInfo" 2 "OffNotSubscribingInfo" ;
VAL_ 720 VRM_BlutoothStatus_St 0 "Invalid" 1 "On" 2 "Off" ;
VAL_ 720 VRM_BondRequest_St 0 "Invalid" 1 "BondRequestExist" 2 "NoBondRequestExist" ;
VAL_ 720 VRM_VRMMonoOutMode_St 0 "Invalid" 1 "AllocatedVr" 2 "AllocatedBt" 3 "NotAllocated" ;
VAL_ 720 VRM_BTNetworkStatus_St 0 "Invalid" 1 "NoNetwork" 2 "InNetwork" 3 "Roaming" 4 "NoLinkToBtPhone" 5 "NotSupportedByBtPhone" ;
VAL_ 720 VRM_BTSignalStrength_St 0 "Invalid" 1 "SignalStrength0" 2 "SignalStrength1" 3 "SignalStrength2" 4 "SignalStrength3" 5 "SignalStrength4" 6 "SignalStrength5" 7 "NoLinkToBtPhone" 8 "NotSupportedByBtPhone" ;
VAL_ 720 VRM_BTBatteryLevel_St 0 "Invalid" 1 "Level0" 2 "Level1" 3 "Level2" 4 "Level3" 5 "Level4" 6 "Level5" 7 "NoLinkToBtPhone" 8 "NotSupportedByBtPhone" ;
VAL_ 470 VRM_BTActFeatGroup_Rsp 15 "Reserved_last" 8 "Reserved" 7 "Office" 6 "Video" 5 "Voice" 4 "MobileCom" 3 "Nav" 2 "MP" 1 "Radio" 0 "ALL" ;
VAL_ 470 VRM_BTActFeatDevInd_Rsp 31 "IntermediateResult" 30 "FailureConEnvOrDevNotReact" 29 "Failure_ItemMissing" 28 "Failure" 15 "BTDeviceIndex15" 14 "BTDeviceIndex14" 13 "BTDeviceIndex13" 12 "BTDeviceIndex12" 11 "BTDeviceIndex11" 10 "BTDeviceIndex10" 9 "BTDeviceIndex9" 8 "BTDeviceIndex8" 7 "BTDeviceIndex7" 6 "BTDeviceIndex6" 5 "BTDeviceIndex5" 4 "BTDeviceIndex4" 3 "BTDeviceIndex3" 2 "BTDeviceIndex2" 1 "BTDeviceIndex1" 0 "Inactive" ;
VAL_ 470 VRM_BTDebondDevice_Rsp 15 "BTDeviceIndex15Debonded" 14 "BTDeviceIndex14Debonded" 13 "BTDeviceIndex13Debonded" 12 "BTDeviceIndex12Debonded" 11 "BTDeviceIndex11Debonded" 10 "BTDeviceIndex10Debonded" 9 "BTDeviceIndex9Debonded" 8 "BTDeviceIndex8Debonded" 7 "BTDeviceIndex7Debonded" 6 "BTDeviceIndex6Debonded" 5 "BTDeviceIndex5Debonded" 4 "BTDeviceIndex4Debonded" 3 "BTDeviceIndex3Debonded" 2 "BTDeviceIndex2Debonded" 1 "BTDeviceIndex1Debonded" 0 "Inactive" ;
VAL_ 470 VR_StartPhoneVR_Rsp 3 "NotAllowed" 2 "Recognized" 1 "Idle" 0 "Inactive" ;
VAL_ 470 VRM_DebondPhone_Rsp 0 "Inactive" 1 "PhoneIndex1Debonded" 2 "PhoneIndex2Debonded" 3 "PhoneIndex3Debonded" 4 "PhoneIndex4Debonded" 5 "PhoneIndex5Debonded" 6 "PhoneIndex6Debonded" 7 "NoPhoneAssocWithThisIndex" ;
VAL_ 470 VRM_BTSendDTMFTone_Rsp 0 "Inactive" 1 "FinalResult" 2 "IntermediateResult" 3 "Error" ;
VAL_ 470 VRM_SetDefaultPhone_Rsp 0 "Inactive" 1 "PhoneIndex1" 2 "PhoneIndex2" 3 "PhoneIndex3" 4 "PhoneIndex4" 5 "PhoneIndex5" 6 "PhoneIndex6" 7 "NoPhoneAssocWithThisIndex" 8 "NotAbleToCreateLinkToPhone" 9 "IntermediateResult" ;
VAL_ 470 VRM_PlayNametag_Rsp 0 "Inactive" 1 "NametagUnknown" ;
VAL_ 470 VRM_BTIncomingCall_Rsp 0 "Inactive" 1 "Accepted" 2 "Declined" 3 "Failed" ;
VAL_ 470 VRM_BTEndTelService_Rsp 3 "Error" 0 "Inactive" 1 "IntermediateResult" 2 "FinalResult" ;
VAL_ 758 SDARS_OpMode_St 7 "FastRewindSpeed2" 6 "FastRewindSpeed1" 5 "FastForwardSpeed2" 4 "FastForwardSpeed1" 3 "Pause" 2 "Play" 1 "Stop" 0 "Invalid" ;
VAL_ 758 SDARS_Factory_Reset_St 1 "FactorySettingsRestored" 0 "Invalid" ;
